VERSION ""

NS_ :

BS_:

BU_: PowertrainControlModule AtmosphericSensor SafetyRestraintSystem2 Aftertreatment_2_GasOutlet Aftertreatment_2_GasIntake DieselParticulateFilterControl Turbocharger SafetyRestraintSystem1 CabDisplay2 Aftertreatment_1_GasOutlet Aftertreatment_1_GasIntake OnBoardDataLogger OffBoardDiagnosticTool2 OffBoardDiagnosticTool1 FileServer ParkingBrakeController SeatController2 FanDriveController SteeringColumnUnit CommunicationUnitRadio CommunicationUnitSatellite CommunicationUnitCellular PropulsionBatteryCharger ChassisController2 ChassisController1 EngineValveControl AuxiliaryHeater2 AuxiliaryHeater1 ClutchUnit RampControl InformationSystem1 SuspensionSystemController2 OilSensor VehicleDynamicStability ExhaustEmissionController TransmissionDisplay2 TransmissionDisplay1 ClimateControl2 WaterPumpController RearAxleSteeringController LightingOperatorControl SeatController1 IgnitionController2 IgnitionController1 TirePressureController CabController2 CabController1 PneumaticSystemController SuspensionSystemController1 HydraulicPumpController EnduranceBrakingSystem RetarderExhaustEngine2 OnBoardDiagnosticUnit HeadwayController RetarderExhaustEngine1 CabDisplay1 ManagementComputer VirtualTerminal OffVehicleGateway PowerTakeOffFront HitchControl AuxiliaryValveControl BodyController TractorTrailerBridge1 StarterSystem ElectricalSystem VehicleSecurity VehicleNavigation AerodynamicControl ElectricalChargingSystem ClimateControl1 TripRecorder InstrumentCluster SuspensionDriveAxle2 SuspensionDriveAxle1 SuspensionSteerAxle SteeringController FuelSystem CruiseControl RetarderDriveline RetarderEngine BrakesDriveAxle2 BrakesDriveAxle1 BrakesSystemController BrakesSteerAxle AxleDrive2 AxleDrive1 AxleSteering PowerTakeOff ShiftConsoleSecondary ShiftConsolePrimary Transmission2 Transmission1 Engine2 Engine1

BO_ 2364723454 HVESP19S1: 8 Vector__XXX
 SG_ Status1CRC : 56|8@1+ (1,0) [0|255] "" Vector__XXX
 SG_ Status1Counter : 52|4@1+ (1,0) [0|15] "" Vector__XXX
 SG_ OperationalStatus : 44|4@1+ (1,0) [0|15] "" Vector__XXX
 SG_ HVBusConnectionStatus : 40|4@1+ (1,0) [0|15] "" Vector__XXX
 SG_ InternalChargerStatus : 32|2@1+ (1,0) [0|3] "" Vector__XXX
 SG_ CellBalancingActive : 30|2@1+ (1,0) [0|3] "" Vector__XXX
 SG_ CellBalanceStatus : 28|2@1+ (1,0) [0|3] "" Vector__XXX
 SG_ StOfChargeStatus : 24|4@1+ (1,0) [0|15] "" Vector__XXX
 SG_ InertiaSwStatus : 22|2@1+ (1,0) [0|3] "" Vector__XXX
 SG_ HVILStatus : 20|2@1+ (1,0) [0|3] "" Vector__XXX
 SG_ HVBusPassiveIsolTestStatus : 16|4@1+ (1,0) [0|15] "" Vector__XXX
 SG_ HVBusActiveIsolTestStatus : 12|4@1+ (1,0) [0|15] "" Vector__XXX
 SG_ CenterOfPackContactorSt : 10|2@1+ (1,0) [0|3] "" Vector__XXX
 SG_ HVBusPreChargeRelaySt : 8|2@1+ (1,0) [0|3] "" Vector__XXX
 SG_ HVBusDisconnectForewarning : 4|4@1+ (1,0) [0|15] "" Vector__XXX
 SG_ HVBusContactorSt16454 : 2|2@1+ (1,0) [0|3] "" Vector__XXX
 SG_ HVBusContactorSt : 0|2@1+ (1,0) [0|3] "" Vector__XXX

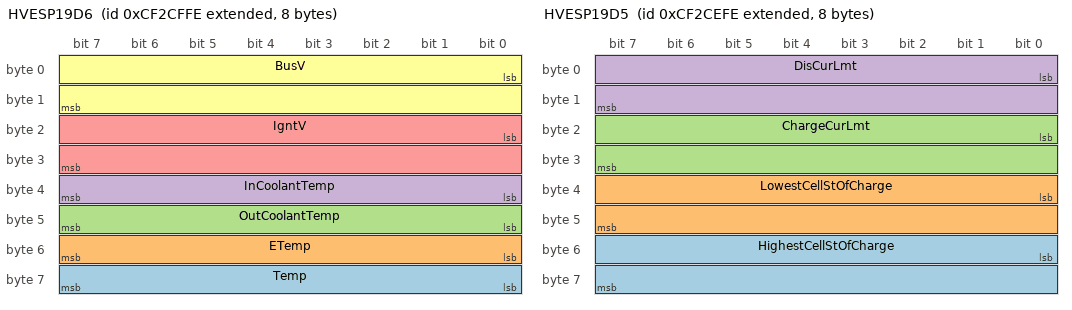
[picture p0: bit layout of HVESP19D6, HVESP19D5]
BO_ 2364723198 HVESP19D6: 8 Vector__XXX
 SG_ Temp : 56|8@1+ (1,-40) [-40|210] "°C" Vector__XXX
 SG_ ETemp : 48|8@1+ (1,-40) [-40|210] "°C" Vector__XXX
 SG_ OutCoolantTemp : 40|8@1+ (1,-40) [-40|210] "°C" Vector__XXX
 SG_ InCoolantTemp : 32|8@1+ (1,-40) [-40|210] "°C" Vector__XXX
 SG_ IgntV : 16|16@1+ (0.01,0) [0|642.55] "V" Vector__XXX
 SG_ BusV : 0|16@1+ (0.05,0) [0|3212.75] "V" Vector__XXX

BO_ 2364722942 HVESP19D5: 8 Vector__XXX
 SG_ HighestCellStOfCharge : 48|16@1+ (0.0015625,0) [0|100.3984375] "%" Vector__XXX
 SG_ LowestCellStOfCharge : 32|16@1+ (0.0015625,0) [0|100.3984375] "%" Vector__XXX
 SG_ ChargeCurLmt : 16|16@1+ (0.05,-1600) [0|1612.75] "A" Vector__XXX
 SG_ DisCurLmt : 0|16@1+ (0.05,-1600) [-1600|0] "A" Vector__XXX

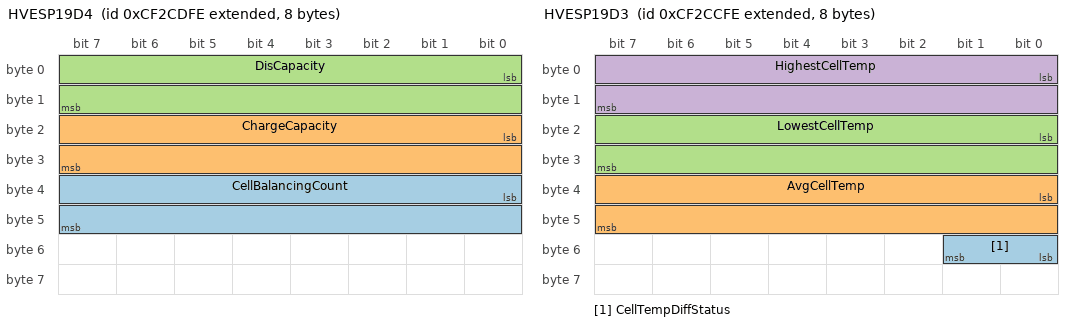
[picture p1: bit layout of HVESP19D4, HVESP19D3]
BO_ 2364722686 HVESP19D4: 8 Vector__XXX
 SG_ CellBalancingCount : 32|16@1+ (1,0) [0|64255] "" Vector__XXX
 SG_ ChargeCapacity : 16|16@1+ (0.01,0) [0|642.55] "Ah" Vector__XXX
 SG_ DisCapacity : 0|16@1+ (0.01,0) [0|642.55] "Ah" Vector__XXX

BO_ 2364722430 HVESP19D3: 8 Vector__XXX
 SG_ CellTempDiffStatus : 48|2@1+ (1,0) [0|3] "" Vector__XXX
 SG_ AvgCellTemp : 32|16@1+ (0.03125,-273) [-273|1734.96875] "°C" Vector__XXX
 SG_ LowestCellTemp : 16|16@1+ (0.03125,-273) [-273|1734.96875] "°C" Vector__XXX
 SG_ HighestCellTemp : 0|16@1+ (0.03125,-273) [-273|1734.96875] "°C" Vector__XXX

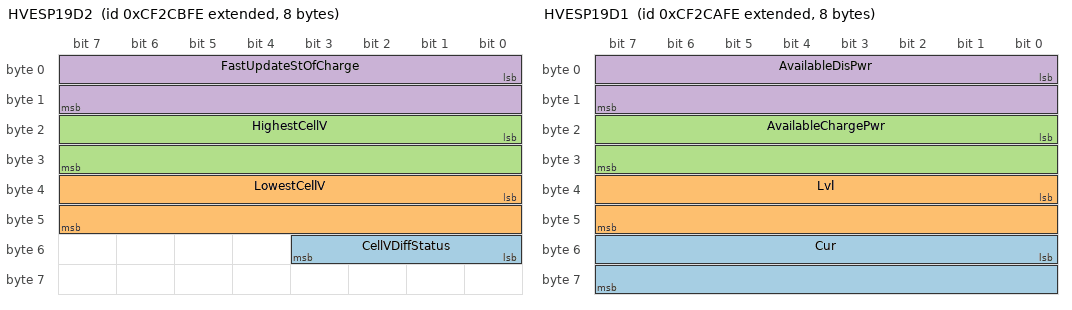
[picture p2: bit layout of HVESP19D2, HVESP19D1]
BO_ 2364722174 HVESP19D2: 8 Vector__XXX
 SG_ CellVDiffStatus : 48|4@1+ (1,0) [0|15] "" Vector__XXX
 SG_ LowestCellV : 32|16@1+ (0.001,0) [0|64.255] "V" Vector__XXX
 SG_ HighestCellV : 16|16@1+ (0.001,0) [0|64.255] "V" Vector__XXX
 SG_ FastUpdateStOfCharge : 0|16@1+ (0.0015625,0) [0|100.3984375] "%" Vector__XXX

BO_ 2364721918 HVESP19D1: 8 Vector__XXX
 SG_ Cur : 48|16@1+ (0.05,-1600) [-1600|1612.75] "A" Vector__XXX
 SG_ Lvl : 32|16@1+ (0.05,0) [0|3212.75] "V" Vector__XXX
 SG_ AvailableChargePwr : 16|16@1+ (0.05,0) [0|3212.75] "kW" Vector__XXX
 SG_ AvailableDisPwr : 0|16@1+ (0.05,0) [0|3212.75] "kW" Vector__XXX

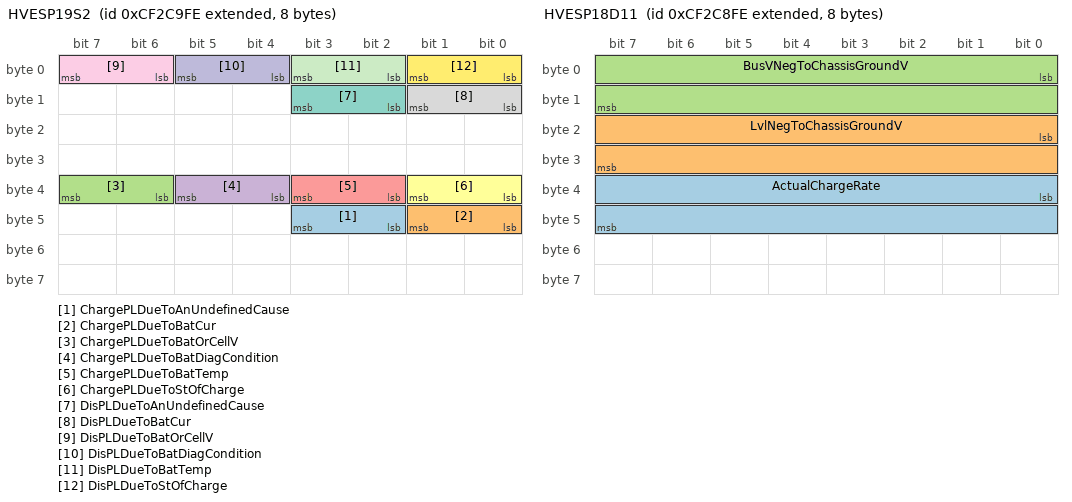
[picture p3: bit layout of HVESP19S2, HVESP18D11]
BO_ 2364721662 HVESP19S2: 8 Vector__XXX
 SG_ ChargePLDueToAnUndefinedCause : 42|2@1+ (1,0) [0|3] "" Vector__XXX
 SG_ ChargePLDueToBatCur : 40|2@1+ (1,0) [0|3] "" Vector__XXX
 SG_ ChargePLDueToBatOrCellV : 38|2@1+ (1,0) [0|3] "" Vector__XXX
 SG_ ChargePLDueToBatDiagCondition : 36|2@1+ (1,0) [0|3] "" Vector__XXX
 SG_ ChargePLDueToBatTemp : 34|2@1+ (1,0) [0|3] "" Vector__XXX
 SG_ ChargePLDueToStOfCharge : 32|2@1+ (1,0) [0|3] "" Vector__XXX
 SG_ DisPLDueToAnUndefinedCause : 10|2@1+ (1,0) [0|3] "" Vector__XXX
 SG_ DisPLDueToBatCur : 8|2@1+ (1,0) [0|3] "" Vector__XXX
 SG_ DisPLDueToBatOrCellV : 6|2@1+ (1,0) [0|3] "" Vector__XXX
 SG_ DisPLDueToBatDiagCondition : 4|2@1+ (1,0) [0|3] "" Vector__XXX
 SG_ DisPLDueToBatTemp : 2|2@1+ (1,0) [0|3] "" Vector__XXX
 SG_ DisPLDueToStOfCharge : 0|2@1+ (1,0) [0|3] "" Vector__XXX

BO_ 2364721406 HVESP18D11: 8 Vector__XXX
 SG_ ActualChargeRate : 32|16@1+ (0.05,0) [0|3212.75] "kW" Vector__XXX
 SG_ LvlNegToChassisGroundV : 16|16@1+ (0.05,0) [0|3212.75] "V" Vector__XXX
 SG_ BusVNegToChassisGroundV : 0|16@1+ (0.05,0) [0|3212.75] "V" Vector__XXX

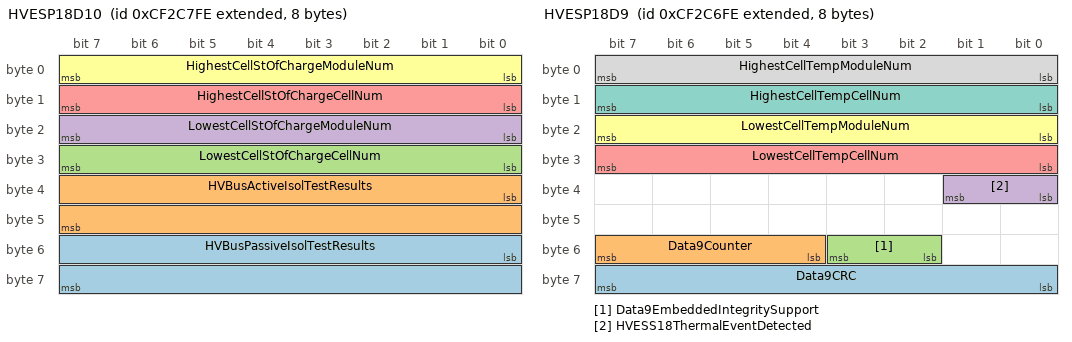
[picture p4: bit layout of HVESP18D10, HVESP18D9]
BO_ 2364721150 HVESP18D10: 8 Vector__XXX
 SG_ HVBusPassiveIsolTestResults : 48|16@1+ (0.1,0) [0|6425.5] "Ohm/V" Vector__XXX
 SG_ HVBusActiveIsolTestResults : 32|16@1+ (0.1,0) [0|6425.5] "Ohm/V" Vector__XXX
 SG_ LowestCellStOfChargeCellNum : 24|8@1+ (1,0) [0|250] "" Vector__XXX
 SG_ LowestCellStOfChargeModuleNum : 16|8@1+ (1,0) [0|250] "" Vector__XXX
 SG_ HighestCellStOfChargeCellNum : 8|8@1+ (1,0) [0|250] "" Vector__XXX
 SG_ HighestCellStOfChargeModuleNum : 0|8@1+ (1,0) [0|250] "" Vector__XXX

BO_ 2364720894 HVESP18D9: 8 Vector__XXX
 SG_ Data9CRC : 56|8@1+ (1,0) [0|255] "" Vector__XXX
 SG_ Data9Counter : 52|4@1+ (1,0) [0|15] "" Vector__XXX
 SG_ Data9EmbeddedIntegritySupport : 50|2@1+ (1,0) [0|3] "" Vector__XXX
 SG_ HVESS18ThermalEventDetected : 32|2@1+ (1,0) [0|3] "" Vector__XXX
 SG_ LowestCellTempCellNum : 24|8@1+ (1,0) [0|250] "" Vector__XXX
 SG_ LowestCellTempModuleNum : 16|8@1+ (1,0) [0|250] "" Vector__XXX
 SG_ HighestCellTempCellNum : 8|8@1+ (1,0) [0|250] "" Vector__XXX
 SG_ HighestCellTempModuleNum : 0|8@1+ (1,0) [0|250] "" Vector__XXX

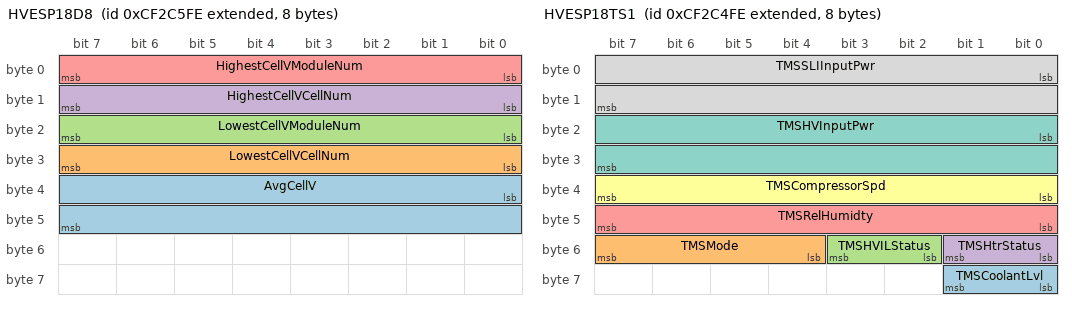
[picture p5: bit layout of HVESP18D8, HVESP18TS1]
BO_ 2364720638 HVESP18D8: 8 Vector__XXX
 SG_ AvgCellV : 32|16@1+ (0.001,0) [0|64.255] "V" Vector__XXX
 SG_ LowestCellVCellNum : 24|8@1+ (1,0) [0|250] "" Vector__XXX
 SG_ LowestCellVModuleNum : 16|8@1+ (1,0) [0|250] "" Vector__XXX
 SG_ HighestCellVCellNum : 8|8@1+ (1,0) [0|250] "" Vector__XXX
 SG_ HighestCellVModuleNum : 0|8@1+ (1,0) [0|250] "" Vector__XXX

BO_ 2364720382 HVESP18TS1: 8 Vector__XXX
 SG_ TMSCoolantLvl : 56|2@1+ (1,0) [0|3] "" Vector__XXX
 SG_ TMSMode : 52|4@1+ (1,0) [0|15] "" Vector__XXX
 SG_ TMSHVILStatus : 50|2@1+ (1,0) [0|3] "" Vector__XXX
 SG_ TMSHtrStatus : 48|2@1+ (1,0) [0|3] "" Vector__XXX
 SG_ TMSRelHumidty : 40|8@1+ (0.4,0) [0|100] "%" Vector__XXX
 SG_ TMSCompressorSpd : 32|8@1+ (32,0) [0|8000] "rpm" Vector__XXX
 SG_ TMSHVInputPwr : 16|16@1+ (0.5,0) [0|32127.5] "W" Vector__XXX
 SG_ TMSSLIInputPwr : 0|16@1+ (0.5,0) [0|32127.5] "W" Vector__XXX

BO_ 2364720126 HVESP18MS1: 8 Vector__XXX
 SG_ Module32OperationalStatus : 62|2@1+ (1,0) [0|3] "" Vector__XXX
 SG_ Module31OperationalStatus : 60|2@1+ (1,0) [0|3] "" Vector__XXX
 SG_ Module30OperationalStatus : 58|2@1+ (1,0) [0|3] "" Vector__XXX
 SG_ Module29OperationalStatus : 56|2@1+ (1,0) [0|3] "" Vector__XXX
 SG_ Module28OperationalStatus : 54|2@1+ (1,0) [0|3] "" Vector__XXX
 SG_ Module27OperationalStatus : 52|2@1+ (1,0) [0|3] "" Vector__XXX
 SG_ Module26OperationalStatus : 50|2@1+ (1,0) [0|3] "" Vector__XXX
 SG_ Module25OperationalStatus : 48|2@1+ (1,0) [0|3] "" Vector__XXX
 SG_ Module24OperationalStatus : 46|2@1+ (1,0) [0|3] "" Vector__XXX
 SG_ Module23OperationalStatus : 44|2@1+ (1,0) [0|3] "" Vector__XXX
 SG_ Module22OperationalStatus : 42|2@1+ (1,0) [0|3] "" Vector__XXX
 SG_ Module21OperationalStatus : 40|2@1+ (1,0) [0|3] "" Vector__XXX
 SG_ Module20OperationalStatus : 38|2@1+ (1,0) [0|3] "" Vector__XXX
 SG_ Module19OperationalStatus : 36|2@1+ (1,0) [0|3] "" Vector__XXX
 SG_ Module18OperationalStatus : 34|2@1+ (1,0) [0|3] "" Vector__XXX
 SG_ Module17OperationalStatus : 32|2@1+ (1,0) [0|3] "" Vector__XXX
 SG_ Module16OperationalStatus : 30|2@1+ (1,0) [0|3] "" Vector__XXX
 SG_ Module15OperationalStatus : 28|2@1+ (1,0) [0|3] "" Vector__XXX
 SG_ Module14OperationalStatus : 26|2@1+ (1,0) [0|3] "" Vector__XXX
 SG_ Module13OperationalStatus : 24|2@1+ (1,0) [0|3] "" Vector__XXX
 SG_ Module12OperationalStatus : 22|2@1+ (1,0) [0|3] "" Vector__XXX
 SG_ Module11OperationalStatus : 20|2@1+ (1,0) [0|3] "" Vector__XXX
 SG_ Module10OperationalStatus : 18|2@1+ (1,0) [0|3] "" Vector__XXX
 SG_ Module9OperationalStatus : 16|2@1+ (1,0) [0|3] "" Vector__XXX
 SG_ Module8OperationalStatus : 14|2@1+ (1,0) [0|3] "" Vector__XXX
 SG_ Module7OperationalStatus : 12|2@1+ (1,0) [0|3] "" Vector__XXX
 SG_ Module6OperationalStatus : 10|2@1+ (1,0) [0|3] "" Vector__XXX
 SG_ Module5OperationalStatus : 8|2@1+ (1,0) [0|3] "" Vector__XXX
 SG_ Module4OperationalStatus : 6|2@1+ (1,0) [0|3] "" Vector__XXX
 SG_ Module3OperationalStatus : 4|2@1+ (1,0) [0|3] "" Vector__XXX
 SG_ Module2OperationalStatus : 2|2@1+ (1,0) [0|3] "" Vector__XXX
 SG_ Module1OperationalStatus : 0|2@1+ (1,0) [0|3] "" Vector__XXX

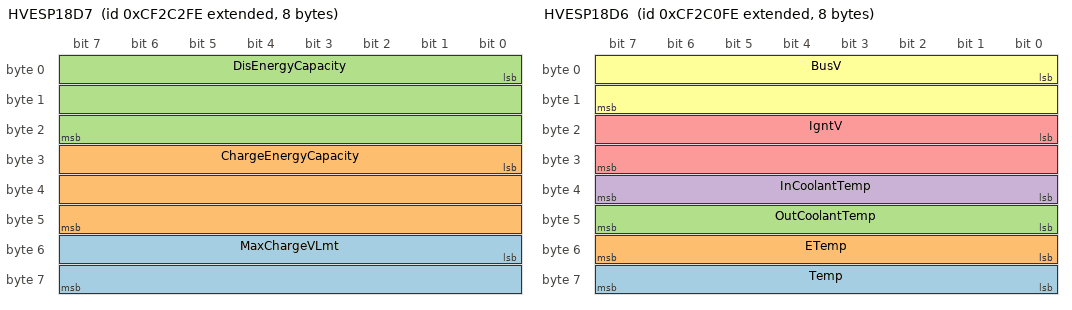
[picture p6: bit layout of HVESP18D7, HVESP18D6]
BO_ 2364719870 HVESP18D7: 8 Vector__XXX
 SG_ MaxChargeVLmt : 48|16@1+ (0.05,0) [0|3212.75] "V" Vector__XXX
 SG_ ChargeEnergyCapacity : 24|24@1+ (0.001,0) [0|16449.535] "kWh" Vector__XXX
 SG_ DisEnergyCapacity : 0|24@1+ (0.001,0) [0|16449.535] "kWh" Vector__XXX

BO_ 2364719614 HVESP18S1: 8 Vector__XXX
 SG_ Status1CRC : 56|8@1+ (1,0) [0|255] "" Vector__XXX
 SG_ Status1Counter : 52|4@1+ (1,0) [0|15] "" Vector__XXX
 SG_ OperationalStatus : 44|4@1+ (1,0) [0|15] "" Vector__XXX
 SG_ HVBusConnectionStatus : 40|4@1+ (1,0) [0|15] "" Vector__XXX
 SG_ InternalChargerStatus : 32|2@1+ (1,0) [0|3] "" Vector__XXX
 SG_ CellBalancingActive : 30|2@1+ (1,0) [0|3] "" Vector__XXX
 SG_ CellBalanceStatus : 28|2@1+ (1,0) [0|3] "" Vector__XXX
 SG_ StOfChargeStatus : 24|4@1+ (1,0) [0|15] "" Vector__XXX
 SG_ InertiaSwStatus : 22|2@1+ (1,0) [0|3] "" Vector__XXX
 SG_ HVILStatus : 20|2@1+ (1,0) [0|3] "" Vector__XXX
 SG_ HVBusPassiveIsolTestStatus : 16|4@1+ (1,0) [0|15] "" Vector__XXX
 SG_ HVBusActiveIsolTestStatus : 12|4@1+ (1,0) [0|15] "" Vector__XXX
 SG_ CenterOfPackContactorSt : 10|2@1+ (1,0) [0|3] "" Vector__XXX
 SG_ HVBusPreChargeRelaySt : 8|2@1+ (1,0) [0|3] "" Vector__XXX
 SG_ HVBusDisconnectForewarning : 4|4@1+ (1,0) [0|15] "" Vector__XXX
 SG_ HVBusContactorSt16312 : 2|2@1+ (1,0) [0|3] "" Vector__XXX
 SG_ HVBusContactorSt : 0|2@1+ (1,0) [0|3] "" Vector__XXX

BO_ 2364719358 HVESP18D6: 8 Vector__XXX
 SG_ Temp : 56|8@1+ (1,-40) [-40|210] "°C" Vector__XXX
 SG_ ETemp : 48|8@1+ (1,-40) [-40|210] "°C" Vector__XXX
 SG_ OutCoolantTemp : 40|8@1+ (1,-40) [-40|210] "°C" Vector__XXX
 SG_ InCoolantTemp : 32|8@1+ (1,-40) [-40|210] "°C" Vector__XXX
 SG_ IgntV : 16|16@1+ (0.01,0) [0|642.55] "V" Vector__XXX
 SG_ BusV : 0|16@1+ (0.05,0) [0|3212.75] "V" Vector__XXX

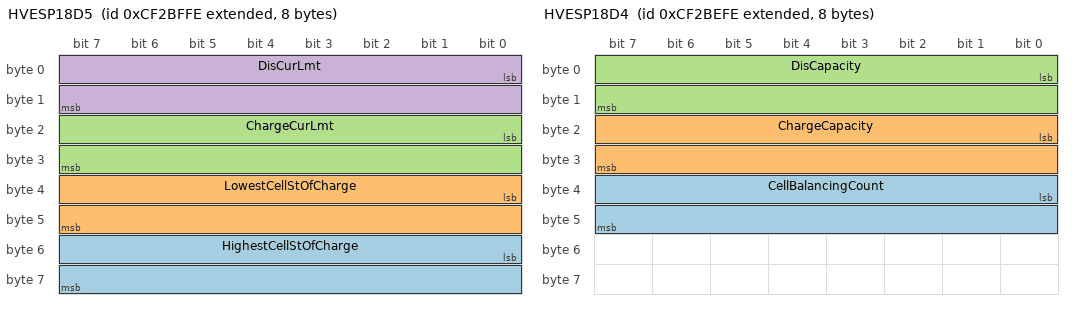
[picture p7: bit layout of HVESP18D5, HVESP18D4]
BO_ 2364719102 HVESP18D5: 8 Vector__XXX
 SG_ HighestCellStOfCharge : 48|16@1+ (0.0015625,0) [0|100.3984375] "%" Vector__XXX
 SG_ LowestCellStOfCharge : 32|16@1+ (0.0015625,0) [0|100.3984375] "%" Vector__XXX
 SG_ ChargeCurLmt : 16|16@1+ (0.05,-1600) [0|1612.75] "A" Vector__XXX
 SG_ DisCurLmt : 0|16@1+ (0.05,-1600) [-1600|0] "A" Vector__XXX

BO_ 2364718846 HVESP18D4: 8 Vector__XXX
 SG_ CellBalancingCount : 32|16@1+ (1,0) [0|64255] "" Vector__XXX
 SG_ ChargeCapacity : 16|16@1+ (0.01,0) [0|642.55] "Ah" Vector__XXX
 SG_ DisCapacity : 0|16@1+ (0.01,0) [0|642.55] "Ah" Vector__XXX

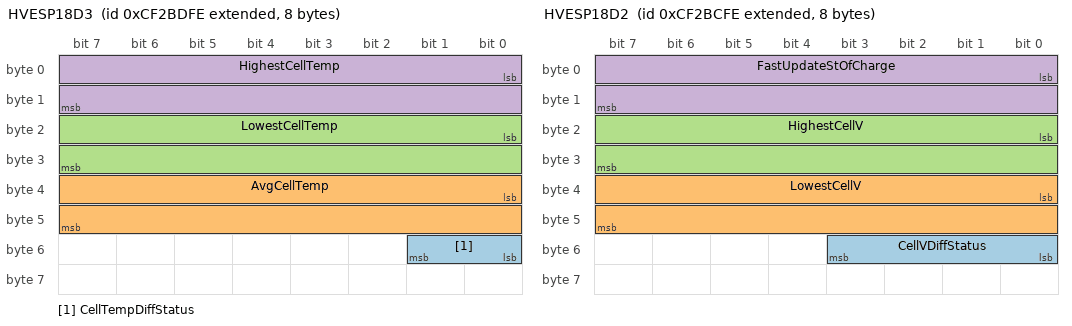
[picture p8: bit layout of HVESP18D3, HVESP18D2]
BO_ 2364718590 HVESP18D3: 8 Vector__XXX
 SG_ CellTempDiffStatus : 48|2@1+ (1,0) [0|3] "" Vector__XXX
 SG_ AvgCellTemp : 32|16@1+ (0.03125,-273) [-273|1734.96875] "°C" Vector__XXX
 SG_ LowestCellTemp : 16|16@1+ (0.03125,-273) [-273|1734.96875] "°C" Vector__XXX
 SG_ HighestCellTemp : 0|16@1+ (0.03125,-273) [-273|1734.96875] "°C" Vector__XXX

BO_ 2364718334 HVESP18D2: 8 Vector__XXX
 SG_ CellVDiffStatus : 48|4@1+ (1,0) [0|15] "" Vector__XXX
 SG_ LowestCellV : 32|16@1+ (0.001,0) [0|64.255] "V" Vector__XXX
 SG_ HighestCellV : 16|16@1+ (0.001,0) [0|64.255] "V" Vector__XXX
 SG_ FastUpdateStOfCharge : 0|16@1+ (0.0015625,0) [0|100.3984375] "%" Vector__XXX

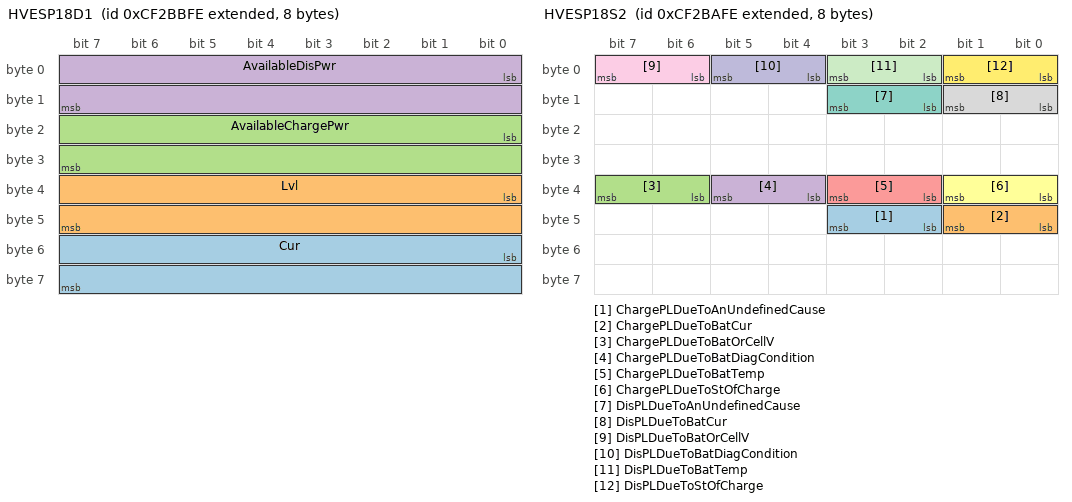
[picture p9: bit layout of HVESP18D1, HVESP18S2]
BO_ 2364718078 HVESP18D1: 8 Vector__XXX
 SG_ Cur : 48|16@1+ (0.05,-1600) [-1600|1612.75] "A" Vector__XXX
 SG_ Lvl : 32|16@1+ (0.05,0) [0|3212.75] "V" Vector__XXX
 SG_ AvailableChargePwr : 16|16@1+ (0.05,0) [0|3212.75] "kW" Vector__XXX
 SG_ AvailableDisPwr : 0|16@1+ (0.05,0) [0|3212.75] "kW" Vector__XXX

BO_ 2364717822 HVESP18S2: 8 Vector__XXX
 SG_ ChargePLDueToAnUndefinedCause : 42|2@1+ (1,0) [0|3] "" Vector__XXX
 SG_ ChargePLDueToBatCur : 40|2@1+ (1,0) [0|3] "" Vector__XXX
 SG_ ChargePLDueToBatOrCellV : 38|2@1+ (1,0) [0|3] "" Vector__XXX
 SG_ ChargePLDueToBatDiagCondition : 36|2@1+ (1,0) [0|3] "" Vector__XXX
 SG_ ChargePLDueToBatTemp : 34|2@1+ (1,0) [0|3] "" Vector__XXX
 SG_ ChargePLDueToStOfCharge : 32|2@1+ (1,0) [0|3] "" Vector__XXX
 SG_ DisPLDueToAnUndefinedCause : 10|2@1+ (1,0) [0|3] "" Vector__XXX
 SG_ DisPLDueToBatCur : 8|2@1+ (1,0) [0|3] "" Vector__XXX
 SG_ DisPLDueToBatOrCellV : 6|2@1+ (1,0) [0|3] "" Vector__XXX
 SG_ DisPLDueToBatDiagCondition : 4|2@1+ (1,0) [0|3] "" Vector__XXX
 SG_ DisPLDueToBatTemp : 2|2@1+ (1,0) [0|3] "" Vector__XXX
 SG_ DisPLDueToStOfCharge : 0|2@1+ (1,0) [0|3] "" Vector__XXX

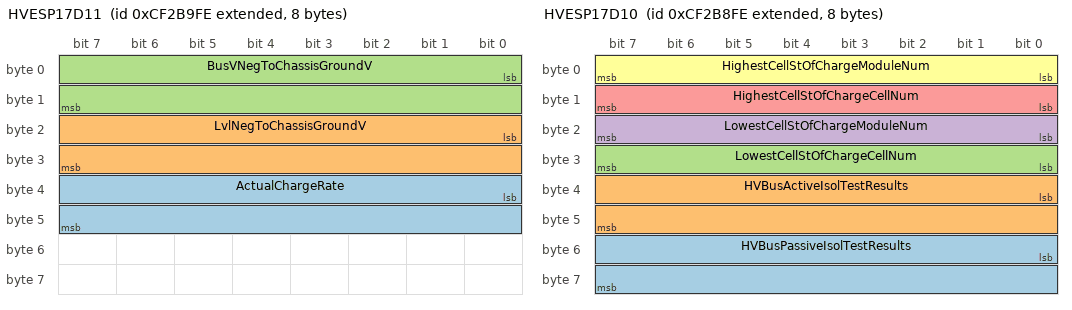
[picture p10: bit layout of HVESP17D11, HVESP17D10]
BO_ 2364717566 HVESP17D11: 8 Vector__XXX
 SG_ ActualChargeRate : 32|16@1+ (0.05,0) [0|3212.75] "kW" Vector__XXX
 SG_ LvlNegToChassisGroundV : 16|16@1+ (0.05,0) [0|3212.75] "V" Vector__XXX
 SG_ BusVNegToChassisGroundV : 0|16@1+ (0.05,0) [0|3212.75] "V" Vector__XXX

BO_ 2364717310 HVESP17D10: 8 Vector__XXX
 SG_ HVBusPassiveIsolTestResults : 48|16@1+ (0.1,0) [0|6425.5] "Ohm/V" Vector__XXX
 SG_ HVBusActiveIsolTestResults : 32|16@1+ (0.1,0) [0|6425.5] "Ohm/V" Vector__XXX
 SG_ LowestCellStOfChargeCellNum : 24|8@1+ (1,0) [0|250] "" Vector__XXX
 SG_ LowestCellStOfChargeModuleNum : 16|8@1+ (1,0) [0|250] "" Vector__XXX
 SG_ HighestCellStOfChargeCellNum : 8|8@1+ (1,0) [0|250] "" Vector__XXX
 SG_ HighestCellStOfChargeModuleNum : 0|8@1+ (1,0) [0|250] "" Vector__XXX

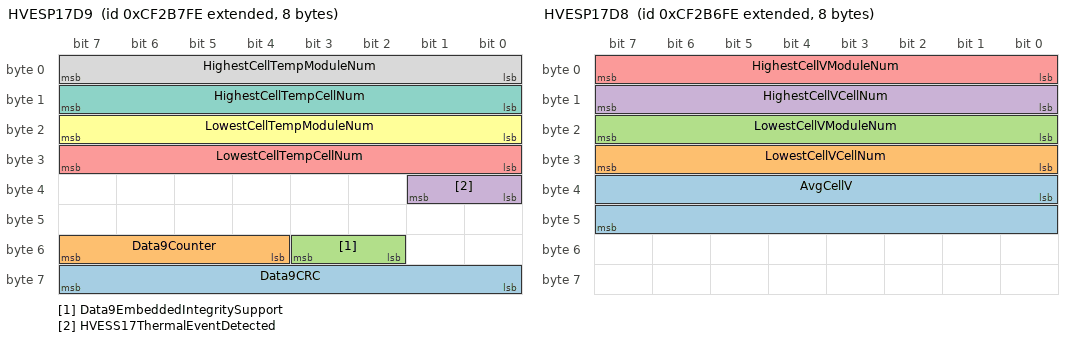
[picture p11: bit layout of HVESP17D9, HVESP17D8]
BO_ 2364717054 HVESP17D9: 8 Vector__XXX
 SG_ Data9CRC : 56|8@1+ (1,0) [0|255] "" Vector__XXX
 SG_ Data9Counter : 52|4@1+ (1,0) [0|15] "" Vector__XXX
 SG_ Data9EmbeddedIntegritySupport : 50|2@1+ (1,0) [0|3] "" Vector__XXX
 SG_ HVESS17ThermalEventDetected : 32|2@1+ (1,0) [0|3] "" Vector__XXX
 SG_ LowestCellTempCellNum : 24|8@1+ (1,0) [0|250] "" Vector__XXX
 SG_ LowestCellTempModuleNum : 16|8@1+ (1,0) [0|250] "" Vector__XXX
 SG_ HighestCellTempCellNum : 8|8@1+ (1,0) [0|250] "" Vector__XXX
 SG_ HighestCellTempModuleNum : 0|8@1+ (1,0) [0|250] "" Vector__XXX

BO_ 2364716798 HVESP17D8: 8 Vector__XXX
 SG_ AvgCellV : 32|16@1+ (0.001,0) [0|64.255] "V" Vector__XXX
 SG_ LowestCellVCellNum : 24|8@1+ (1,0) [0|250] "" Vector__XXX
 SG_ LowestCellVModuleNum : 16|8@1+ (1,0) [0|250] "" Vector__XXX
 SG_ HighestCellVCellNum : 8|8@1+ (1,0) [0|250] "" Vector__XXX
 SG_ HighestCellVModuleNum : 0|8@1+ (1,0) [0|250] "" Vector__XXX

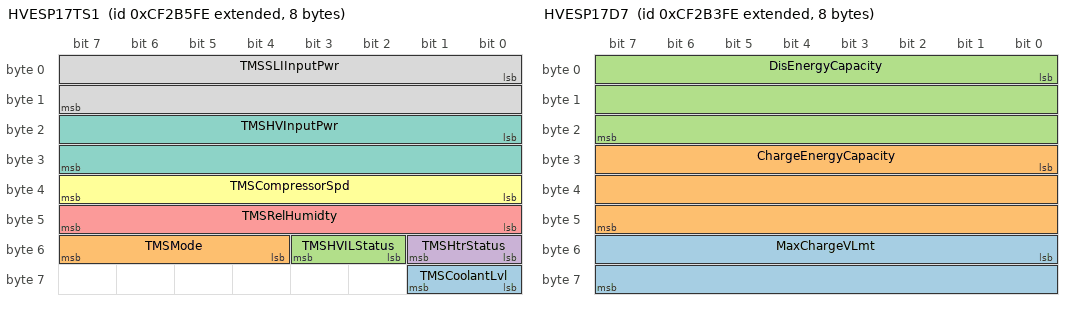
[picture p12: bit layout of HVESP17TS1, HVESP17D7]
BO_ 2364716542 HVESP17TS1: 8 Vector__XXX
 SG_ TMSCoolantLvl : 56|2@1+ (1,0) [0|3] "" Vector__XXX
 SG_ TMSMode : 52|4@1+ (1,0) [0|15] "" Vector__XXX
 SG_ TMSHVILStatus : 50|2@1+ (1,0) [0|3] "" Vector__XXX
 SG_ TMSHtrStatus : 48|2@1+ (1,0) [0|3] "" Vector__XXX
 SG_ TMSRelHumidty : 40|8@1+ (0.4,0) [0|100] "%" Vector__XXX
 SG_ TMSCompressorSpd : 32|8@1+ (32,0) [0|8000] "rpm" Vector__XXX
 SG_ TMSHVInputPwr : 16|16@1+ (0.5,0) [0|32127.5] "W" Vector__XXX
 SG_ TMSSLIInputPwr : 0|16@1+ (0.5,0) [0|32127.5] "W" Vector__XXX

BO_ 2364716286 HVESP17MS1: 8 Vector__XXX
 SG_ Module32OperationalStatus : 62|2@1+ (1,0) [0|3] "" Vector__XXX
 SG_ Module31OperationalStatus : 60|2@1+ (1,0) [0|3] "" Vector__XXX
 SG_ Module30OperationalStatus : 58|2@1+ (1,0) [0|3] "" Vector__XXX
 SG_ Module29OperationalStatus : 56|2@1+ (1,0) [0|3] "" Vector__XXX
 SG_ Module28OperationalStatus : 54|2@1+ (1,0) [0|3] "" Vector__XXX
 SG_ Module27OperationalStatus : 52|2@1+ (1,0) [0|3] "" Vector__XXX
 SG_ Module26OperationalStatus : 50|2@1+ (1,0) [0|3] "" Vector__XXX
 SG_ Module25OperationalStatus : 48|2@1+ (1,0) [0|3] "" Vector__XXX
 SG_ Module24OperationalStatus : 46|2@1+ (1,0) [0|3] "" Vector__XXX
 SG_ Module23OperationalStatus : 44|2@1+ (1,0) [0|3] "" Vector__XXX
 SG_ Module22OperationalStatus : 42|2@1+ (1,0) [0|3] "" Vector__XXX
 SG_ Module21OperationalStatus : 40|2@1+ (1,0) [0|3] "" Vector__XXX
 SG_ Module20OperationalStatus : 38|2@1+ (1,0) [0|3] "" Vector__XXX
 SG_ Module19OperationalStatus : 36|2@1+ (1,0) [0|3] "" Vector__XXX
 SG_ Module18OperationalStatus : 34|2@1+ (1,0) [0|3] "" Vector__XXX
 SG_ Module17OperationalStatus : 32|2@1+ (1,0) [0|3] "" Vector__XXX
 SG_ Module16OperationalStatus : 30|2@1+ (1,0) [0|3] "" Vector__XXX
 SG_ Module15OperationalStatus : 28|2@1+ (1,0) [0|3] "" Vector__XXX
 SG_ Module14OperationalStatus : 26|2@1+ (1,0) [0|3] "" Vector__XXX
 SG_ Module13OperationalStatus : 24|2@1+ (1,0) [0|3] "" Vector__XXX
 SG_ Module12OperationalStatus : 22|2@1+ (1,0) [0|3] "" Vector__XXX
 SG_ Module11OperationalStatus : 20|2@1+ (1,0) [0|3] "" Vector__XXX
 SG_ Module10OperationalStatus : 18|2@1+ (1,0) [0|3] "" Vector__XXX
 SG_ Module9OperationalStatus : 16|2@1+ (1,0) [0|3] "" Vector__XXX
 SG_ Module8OperationalStatus : 14|2@1+ (1,0) [0|3] "" Vector__XXX
 SG_ Module7OperationalStatus : 12|2@1+ (1,0) [0|3] "" Vector__XXX
 SG_ Module6OperationalStatus : 10|2@1+ (1,0) [0|3] "" Vector__XXX
 SG_ Module5OperationalStatus : 8|2@1+ (1,0) [0|3] "" Vector__XXX
 SG_ Module4OperationalStatus : 6|2@1+ (1,0) [0|3] "" Vector__XXX
 SG_ Module3OperationalStatus : 4|2@1+ (1,0) [0|3] "" Vector__XXX
 SG_ Module2OperationalStatus : 2|2@1+ (1,0) [0|3] "" Vector__XXX
 SG_ Module1OperationalStatus : 0|2@1+ (1,0) [0|3] "" Vector__XXX

BO_ 2364716030 HVESP17D7: 8 Vector__XXX
 SG_ MaxChargeVLmt : 48|16@1+ (0.05,0) [0|3212.75] "V" Vector__XXX
 SG_ ChargeEnergyCapacity : 24|24@1+ (0.001,0) [0|16449.535] "kWh" Vector__XXX
 SG_ DisEnergyCapacity : 0|24@1+ (0.001,0) [0|16449.535] "kWh" Vector__XXX

BO_ 2364715774 HVESP17S1: 8 Vector__XXX
 SG_ Status1CRC : 56|8@1+ (1,0) [0|255] "" Vector__XXX
 SG_ Status1Counter : 52|4@1+ (1,0) [0|15] "" Vector__XXX
 SG_ OperationalStatus : 44|4@1+ (1,0) [0|15] "" Vector__XXX
 SG_ HVBusConnectionStatus : 40|4@1+ (1,0) [0|15] "" Vector__XXX
 SG_ InternalChargerStatus : 32|2@1+ (1,0) [0|3] "" Vector__XXX
 SG_ CellBalancingActive : 30|2@1+ (1,0) [0|3] "" Vector__XXX
 SG_ CellBalanceStatus : 28|2@1+ (1,0) [0|3] "" Vector__XXX
 SG_ StOfChargeStatus : 24|4@1+ (1,0) [0|15] "" Vector__XXX
 SG_ InertiaSwStatus : 22|2@1+ (1,0) [0|3] "" Vector__XXX
 SG_ HVILStatus : 20|2@1+ (1,0) [0|3] "" Vector__XXX
 SG_ HVBusPassiveIsolTestStatus : 16|4@1+ (1,0) [0|15] "" Vector__XXX
 SG_ HVBusActiveIsolTestStatus : 12|4@1+ (1,0) [0|15] "" Vector__XXX
 SG_ CenterOfPackContactorSt : 10|2@1+ (1,0) [0|3] "" Vector__XXX
 SG_ HVBusPreChargeRelaySt : 8|2@1+ (1,0) [0|3] "" Vector__XXX
 SG_ HVBusDisconnectForewarning : 4|4@1+ (1,0) [0|15] "" Vector__XXX
 SG_ HVBusContactorSt16170 : 2|2@1+ (1,0) [0|3] "" Vector__XXX
 SG_ HVBusContactorSt : 0|2@1+ (1,0) [0|3] "" Vector__XXX

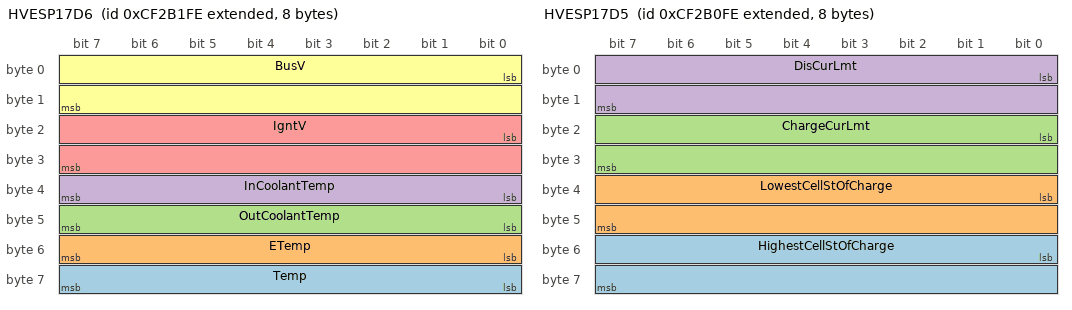
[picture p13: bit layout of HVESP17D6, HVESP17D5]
BO_ 2364715518 HVESP17D6: 8 Vector__XXX
 SG_ Temp : 56|8@1+ (1,-40) [-40|210] "°C" Vector__XXX
 SG_ ETemp : 48|8@1+ (1,-40) [-40|210] "°C" Vector__XXX
 SG_ OutCoolantTemp : 40|8@1+ (1,-40) [-40|210] "°C" Vector__XXX
 SG_ InCoolantTemp : 32|8@1+ (1,-40) [-40|210] "°C" Vector__XXX
 SG_ IgntV : 16|16@1+ (0.01,0) [0|642.55] "V" Vector__XXX
 SG_ BusV : 0|16@1+ (0.05,0) [0|3212.75] "V" Vector__XXX

BO_ 2364715262 HVESP17D5: 8 Vector__XXX
 SG_ HighestCellStOfCharge : 48|16@1+ (0.0015625,0) [0|100.3984375] "%" Vector__XXX
 SG_ LowestCellStOfCharge : 32|16@1+ (0.0015625,0) [0|100.3984375] "%" Vector__XXX
 SG_ ChargeCurLmt : 16|16@1+ (0.05,-1600) [0|1612.75] "A" Vector__XXX
 SG_ DisCurLmt : 0|16@1+ (0.05,-1600) [-1600|0] "A" Vector__XXX

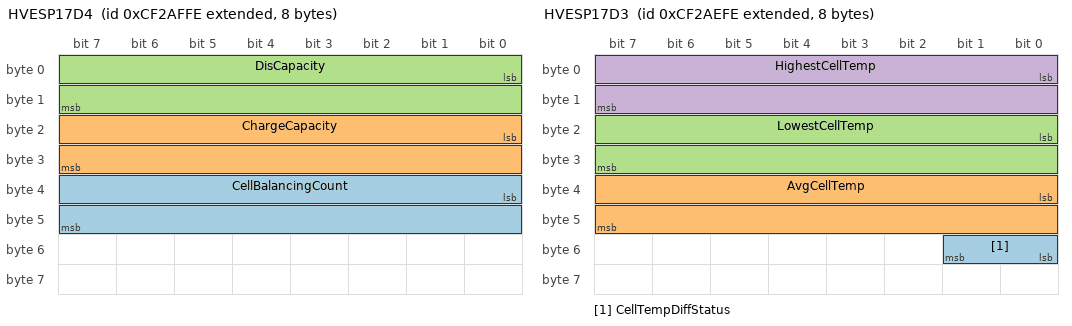
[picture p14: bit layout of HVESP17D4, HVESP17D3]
BO_ 2364715006 HVESP17D4: 8 Vector__XXX
 SG_ CellBalancingCount : 32|16@1+ (1,0) [0|64255] "" Vector__XXX
 SG_ ChargeCapacity : 16|16@1+ (0.01,0) [0|642.55] "Ah" Vector__XXX
 SG_ DisCapacity : 0|16@1+ (0.01,0) [0|642.55] "Ah" Vector__XXX

BO_ 2364714750 HVESP17D3: 8 Vector__XXX
 SG_ CellTempDiffStatus : 48|2@1+ (1,0) [0|3] "" Vector__XXX
 SG_ AvgCellTemp : 32|16@1+ (0.03125,-273) [-273|1734.96875] "°C" Vector__XXX
 SG_ LowestCellTemp : 16|16@1+ (0.03125,-273) [-273|1734.96875] "°C" Vector__XXX
 SG_ HighestCellTemp : 0|16@1+ (0.03125,-273) [-273|1734.96875] "°C" Vector__XXX

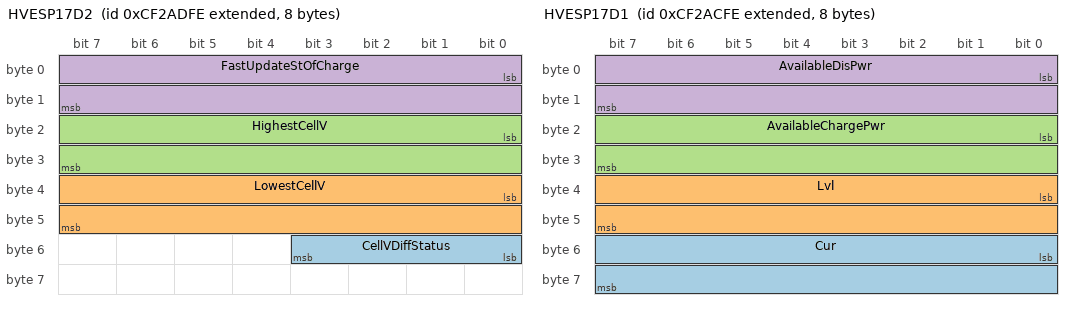
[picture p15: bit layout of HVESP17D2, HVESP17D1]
BO_ 2364714494 HVESP17D2: 8 Vector__XXX
 SG_ CellVDiffStatus : 48|4@1+ (1,0) [0|15] "" Vector__XXX
 SG_ LowestCellV : 32|16@1+ (0.001,0) [0|64.255] "V" Vector__XXX
 SG_ HighestCellV : 16|16@1+ (0.001,0) [0|64.255] "V" Vector__XXX
 SG_ FastUpdateStOfCharge : 0|16@1+ (0.0015625,0) [0|100.3984375] "%" Vector__XXX

BO_ 2364714238 HVESP17D1: 8 Vector__XXX
 SG_ Cur : 48|16@1+ (0.05,-1600) [-1600|1612.75] "A" Vector__XXX
 SG_ Lvl : 32|16@1+ (0.05,0) [0|3212.75] "V" Vector__XXX
 SG_ AvailableChargePwr : 16|16@1+ (0.05,0) [0|3212.75] "kW" Vector__XXX
 SG_ AvailableDisPwr : 0|16@1+ (0.05,0) [0|3212.75] "kW" Vector__XXX

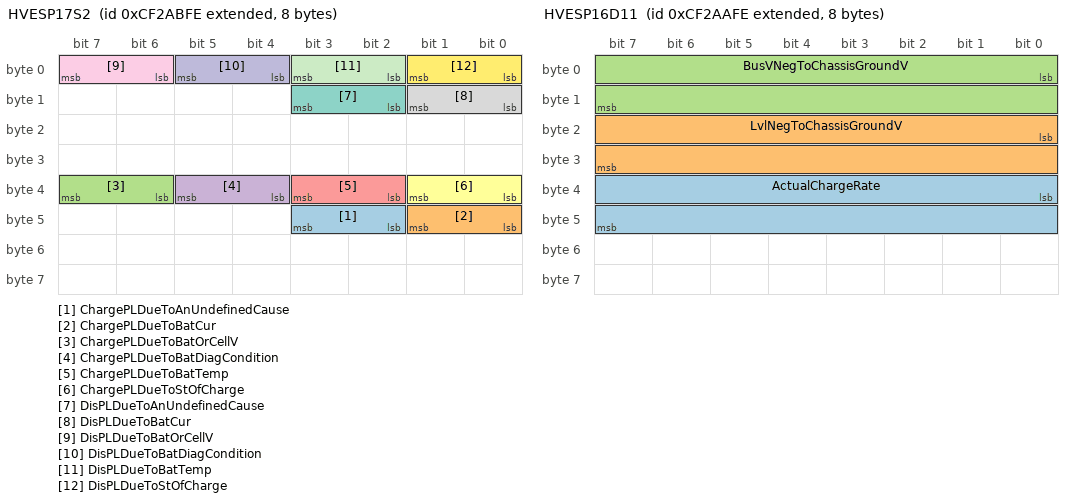
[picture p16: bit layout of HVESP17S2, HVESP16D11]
BO_ 2364713982 HVESP17S2: 8 Vector__XXX
 SG_ ChargePLDueToAnUndefinedCause : 42|2@1+ (1,0) [0|3] "" Vector__XXX
 SG_ ChargePLDueToBatCur : 40|2@1+ (1,0) [0|3] "" Vector__XXX
 SG_ ChargePLDueToBatOrCellV : 38|2@1+ (1,0) [0|3] "" Vector__XXX
 SG_ ChargePLDueToBatDiagCondition : 36|2@1+ (1,0) [0|3] "" Vector__XXX
 SG_ ChargePLDueToBatTemp : 34|2@1+ (1,0) [0|3] "" Vector__XXX
 SG_ ChargePLDueToStOfCharge : 32|2@1+ (1,0) [0|3] "" Vector__XXX
 SG_ DisPLDueToAnUndefinedCause : 10|2@1+ (1,0) [0|3] "" Vector__XXX
 SG_ DisPLDueToBatCur : 8|2@1+ (1,0) [0|3] "" Vector__XXX
 SG_ DisPLDueToBatOrCellV : 6|2@1+ (1,0) [0|3] "" Vector__XXX
 SG_ DisPLDueToBatDiagCondition : 4|2@1+ (1,0) [0|3] "" Vector__XXX
 SG_ DisPLDueToBatTemp : 2|2@1+ (1,0) [0|3] "" Vector__XXX
 SG_ DisPLDueToStOfCharge : 0|2@1+ (1,0) [0|3] "" Vector__XXX

BO_ 2364713726 HVESP16D11: 8 Vector__XXX
 SG_ ActualChargeRate : 32|16@1+ (0.05,0) [0|3212.75] "kW" Vector__XXX
 SG_ LvlNegToChassisGroundV : 16|16@1+ (0.05,0) [0|3212.75] "V" Vector__XXX
 SG_ BusVNegToChassisGroundV : 0|16@1+ (0.05,0) [0|3212.75] "V" Vector__XXX

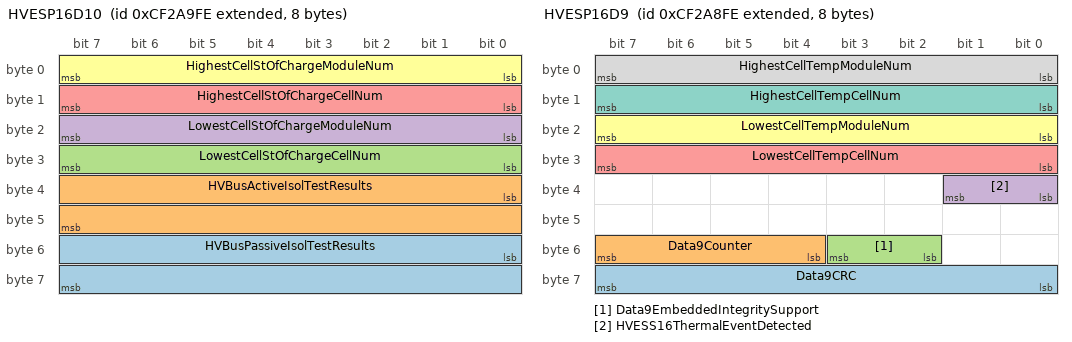
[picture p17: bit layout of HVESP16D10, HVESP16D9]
BO_ 2364713470 HVESP16D10: 8 Vector__XXX
 SG_ HVBusPassiveIsolTestResults : 48|16@1+ (0.1,0) [0|6425.5] "Ohm/V" Vector__XXX
 SG_ HVBusActiveIsolTestResults : 32|16@1+ (0.1,0) [0|6425.5] "Ohm/V" Vector__XXX
 SG_ LowestCellStOfChargeCellNum : 24|8@1+ (1,0) [0|250] "" Vector__XXX
 SG_ LowestCellStOfChargeModuleNum : 16|8@1+ (1,0) [0|250] "" Vector__XXX
 SG_ HighestCellStOfChargeCellNum : 8|8@1+ (1,0) [0|250] "" Vector__XXX
 SG_ HighestCellStOfChargeModuleNum : 0|8@1+ (1,0) [0|250] "" Vector__XXX

BO_ 2364713214 HVESP16D9: 8 Vector__XXX
 SG_ Data9CRC : 56|8@1+ (1,0) [0|255] "" Vector__XXX
 SG_ Data9Counter : 52|4@1+ (1,0) [0|15] "" Vector__XXX
 SG_ Data9EmbeddedIntegritySupport : 50|2@1+ (1,0) [0|3] "" Vector__XXX
 SG_ HVESS16ThermalEventDetected : 32|2@1+ (1,0) [0|3] "" Vector__XXX
 SG_ LowestCellTempCellNum : 24|8@1+ (1,0) [0|250] "" Vector__XXX
 SG_ LowestCellTempModuleNum : 16|8@1+ (1,0) [0|250] "" Vector__XXX
 SG_ HighestCellTempCellNum : 8|8@1+ (1,0) [0|250] "" Vector__XXX
 SG_ HighestCellTempModuleNum : 0|8@1+ (1,0) [0|250] "" Vector__XXX

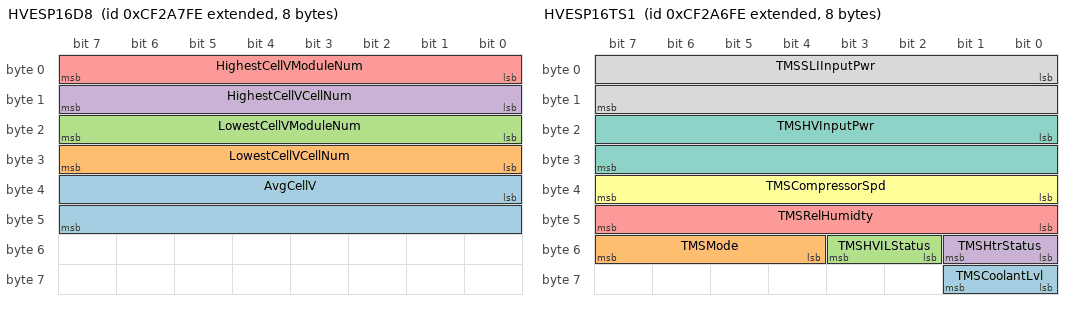
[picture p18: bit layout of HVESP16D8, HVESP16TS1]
BO_ 2364712958 HVESP16D8: 8 Vector__XXX
 SG_ AvgCellV : 32|16@1+ (0.001,0) [0|64.255] "V" Vector__XXX
 SG_ LowestCellVCellNum : 24|8@1+ (1,0) [0|250] "" Vector__XXX
 SG_ LowestCellVModuleNum : 16|8@1+ (1,0) [0|250] "" Vector__XXX
 SG_ HighestCellVCellNum : 8|8@1+ (1,0) [0|250] "" Vector__XXX
 SG_ HighestCellVModuleNum : 0|8@1+ (1,0) [0|250] "" Vector__XXX

BO_ 2364712702 HVESP16TS1: 8 Vector__XXX
 SG_ TMSCoolantLvl : 56|2@1+ (1,0) [0|3] "" Vector__XXX
 SG_ TMSMode : 52|4@1+ (1,0) [0|15] "" Vector__XXX
 SG_ TMSHVILStatus : 50|2@1+ (1,0) [0|3] "" Vector__XXX
 SG_ TMSHtrStatus : 48|2@1+ (1,0) [0|3] "" Vector__XXX
 SG_ TMSRelHumidty : 40|8@1+ (0.4,0) [0|100] "%" Vector__XXX
 SG_ TMSCompressorSpd : 32|8@1+ (32,0) [0|8000] "rpm" Vector__XXX
 SG_ TMSHVInputPwr : 16|16@1+ (0.5,0) [0|32127.5] "W" Vector__XXX
 SG_ TMSSLIInputPwr : 0|16@1+ (0.5,0) [0|32127.5] "W" Vector__XXX

CM_ BO_ 2364723454 "High Voltage Energy Storage Pack 19 Status 1
Status data set 1 for High Voltage Energy Storage Pack 19.";
CM_ SG_ 2364723454 Status1CRC "The CRC is defined as follows:
• Length: 8 bits
• Polynomial: x^8+x^5+x^3+x^2+x+1
• Initial Value: FFh
• Input Data Reflection: Not reflected
• Result Data Reflection: Not reflected
• XOR value: FFh
SAE makes no claim of the functional safety ...";
CM_ SG_ 2364723454 Status1Counter "The message counter is used to detect situations where the transmitting ECU malfunction repeats the same frame all the time. The receiver of the information may use the counter parameter to detect this situation. The transmitting device will ...";
CM_ SG_ 2364723454 OperationalStatus "Provides feedback on where this High Voltage Energy Storage Pack instance is in its operating spectrum, and includes feedback in response to the Operation Consent [i.e. SPN 16411 (HVESP19 Operation Consent)] and Power Down Command [i.e. SPN 16406 ...";
CM_ SG_ 2364723454 HVBusConnectionStatus "This parameter provides high level feedback on this High Voltage Energy Storage Pack instance high voltage bus connection. For specific contactor information, see SPN 16453 (HVESP19 High-Voltage Bus (Positive) Contactor State), SPN 16454 (HVESP19 ...";
CM_ SG_ 2364723454 InternalChargerStatus "Indicates that the charger in this HVES instance is on.  External chargers may use the External Energy Source Connection Status (SPN 7898) and related SPs.
This parameter is for one of multiple packs in an HVESS. If there is only one pack in the ...";
CM_ SG_ 2364723454 CellBalancingActive "Indicates whether or not the cells in this High Voltage Energy Storage Pack instance are currently being balanced.
This parameter is for one of multiple packs in an HVESS.  If there is only one pack in the system, the HVESS parameters should be ...";
CM_ SG_ 2364723454 CellBalanceStatus "Indicates whether or not the cells in this High Voltage Energy Storage Pack instance are balanced.
This parameter is for one of multiple packs in an HVESS.  If there is only one pack in the system, the HVESS parameters should be used. If there are ...";
CM_ SG_ 2364723454 StOfChargeStatus "Status of this High Voltage Energy Storage Pack instance State of Charge (SOC).  Note:  A given HVES controller may not support all of the states.
This parameter is for one of multiple packs in an HVESS.  If there is only one pack in the system, ...";
CM_ SG_ 2364723454 InertiaSwStatus "Switch indicating that an impact has been sensed by this High Voltage Energy Storage Pack instance. The impact indication may require action by another controller, or by this HVES instance itself.  For example, a controller may elect to take this ...";
CM_ SG_ 2364723454 HVILStatus "Status of the High Voltage Interlock Loop from the viewpoint of this High Voltage Energy Storage Pack instance.
This parameter is for one of multiple packs in an HVESS. If there is only one pack in the system, the HVESS parameters should be used ...";
CM_ SG_ 2364723454 HVBusPassiveIsolTestStatus "Status of the high-voltage bus electrical passive isolation test as performed by this High Voltage Energy Storage Pack instance.
This parameter is for one of multiple packs in an HVESS. If there is only one pack in the system, the HVESS parameters ...";
CM_ SG_ 2364723454 HVBusActiveIsolTestStatus "Status of the high-voltage bus electrical active isolation test as performed by this High Voltage Energy Storage Pack instance.
This parameter is for one of multiple packs in an HVESS. If there is only one pack in the system, the HVESS parameters ...";
CM_ SG_ 2364723454 CenterOfPackContactorSt "Position of the center high-voltage contactor. When this contactor is closed, the positive half of this High Voltage Energy Storage Pack instance is connected to the negative half. If a system controls the positive, negative, and center contactors ...";
CM_ SG_ 2364723454 HVBusPreChargeRelaySt "Position of the high-voltage bus contactor pre-charge relay.  When this relay is closed, this High Voltage Energy Storage Pack instance is bringing the high-voltage bus up to its operating level.
This parameter is for one of multiple packs in an ...";
CM_ SG_ 2364723454 HVBusDisconnectForewarning "Indicates that this High Voltage Energy Storage Pack instance is about to disconnect from the high voltage bus due to unacceptable conditions.
This parameter is for one of multiple packs in an HVESS. If there is only one pack in the system, the ...";
CM_ SG_ 2364723454 HVBusContactorSt16454 "Position of this High Voltage Energy Storage Pack instance negative side bus contactor. When this contactor is closed, the negative side of this HVES instance is connected to the negative side of the high-voltage bus. If a system controls the ...";
CM_ SG_ 2364723454 HVBusContactorSt "Position of this High Voltage Energy Storage Pack instance positive side bus contactor.  When this contactor is closed, the positive side of this HVES instance is connected to the positive side of the high-voltage bus.  In systems where all ...";
CM_ BO_ 2364723198 "High Voltage Energy Storage Pack 19 Data 6
Data set 6 (external or interface data) for High Voltage Energy Storage Pack 19.";
CM_ SG_ 2364723198 Temp "The temperature of this High Voltage Energy Storage Pack instance. The value may be determined from a unique sensor specifically for this purpose, or by aggregating various temperature sensor readings within the pack.
This parameter is for one of ...";
CM_ SG_ 2364723198 ETemp "The temperature of the electronics or control modules in this High Voltage Energy Storage Pack instance.  If there are multiple temperature sensors then this parameter would be set to the maximum sensor reading.
This parameter is for one of ...";
CM_ SG_ 2364723198 OutCoolantTemp "The temperature of liquid coolant as it exits this High Voltage Energy Storage Pack instance.
This parameter is for one of multiple packs in an HVESS.  If there is only one pack in the system, the HVESS parameters should be used. If there are ...";
CM_ SG_ 2364723198 InCoolantTemp "The temperature of liquid coolant as it enters this High Voltage Energy Storage Pack instance.
This parameter is for one of multiple packs in an HVESS.  If there is only one pack in the system, the HVESS parameters should be used. If there are ...";
CM_ SG_ 2364723198 IgntV "The voltage level at the ignition input of this High Voltage Energy Storage Pack controller.
This parameter is for one of multiple packs in an HVESS.  If there is only one pack in the system, the HVESS parameters should be used.  If there are ...";
CM_ SG_ 2364723198 BusV "The voltage level of the high voltage bus, as measured by this High Voltage Energy Storage Pack instance on the bus side (not the battery side) of its contactors.
This parameter is for one of multiple packs in an HVESS.  If there is only one pack ...";
CM_ BO_ 2364722942 "High Voltage Energy Storage Pack 19 Data 5
Data set 5 (electrical data) for High Voltage Energy Storage Pack 19.";
CM_ SG_ 2364722942 HighestCellStOfCharge "Indicates the state of charge of the highest-charged cell in this High Voltage Energy Storage Pack instance. 0% means no charge remaining, 100% means the cell is fully charged. If a single state of charge value covers more than one cell, the value ...";
CM_ SG_ 2364722942 LowestCellStOfCharge "Indicates the state of charge of the lowest-charged cell in this High Voltage Energy Storage Pack instance. 0% means no charge remaining, 100% means the cell is fully charged. If a single state of charge value covers more than one cell, the value in ...";
CM_ SG_ 2364722942 ChargeCurLmt "The maximum instantaneous current flow limit into this High Voltage Energy Storage Pack instance. This parameter is defined from the high voltage energy storage pack's point of view and should reflect the instantaneous capability of the pack.  The ...";
CM_ SG_ 2364722942 DisCurLmt "The maximum instantaneous current flow limit out of this High Voltage Energy Storage Pack instance. This parameter is defined from the high voltage energy storage pack's point of view and should reflect the instantaneous capability of the pack.  The ...";
CM_ BO_ 2364722686 "High Voltage Energy Storage Pack 19 Data 4
Data set 4 (electrical data) for High Voltage Energy Storage Pack 19.";
CM_ SG_ 2364722686 CellBalancingCount "The number of cells that are currently being balanced in this High Voltage Energy Storage Pack instance.
This parameter is for one of multiple packs in an HVESS.  If there is only one pack in the system, the HVESS parameters should be used.  If ...";
CM_ SG_ 2364722686 ChargeCapacity "The amount of unused electrical charge storage in this High Voltage Energy Storage Pack instance that is available to be filled by charging, i.e. “how much empty space is remaining in the tank”. See SPN 16471 (HVESP19 Charge Energy Capacity) for ...";
CM_ SG_ 2364722686 DisCapacity "The amount of stored electrical charge in this High Voltage Energy Storage Pack instance that is available for use by the hybrid system, i.e. “how full is the tank”. See SPN 16470 (HVESP19 Discharge Energy Capacity) for kilowatt-hours (kWh).
This ...";
CM_ BO_ 2364722430 "High Voltage Energy Storage Pack 19 Data 3
Data set 3 (thermal data) for High Voltage Energy Storage Pack 19.";
CM_ SG_ 2364722430 CellTempDiffStatus "Indicates whether or not the differential between the highest and lowest cell temperatures are within acceptable limits per this High Voltage Energy Storage Pack instance. The actual temperature differential can be calculated by subtracting SPN ...";
CM_ SG_ 2364722430 AvgCellTemp "The average temperature level of all cells in this High Voltage Energy Storage Pack instance.
This parameter is for one of multiple packs in an HVESS.  If there is only one pack in the system, the HVESS parameters should be used.  If there are ...";
CM_ SG_ 2364722430 LowestCellTemp "The lowest temperature level reported by any cell in this High Voltage Energy Storage Pack instance. If a single temperature sensor covers more than one cell, the value in this parameter is for the smallest group of cells measured. See SPN 16520 ...";
CM_ SG_ 2364722430 HighestCellTemp "The highest temperature level reported by any cell in this High Voltage Energy Storage Pack instance. If a single temperature sensor covers more than one cell, the value in this parameter is for the smallest group of cells measured. See SPN 16518 ...";
CM_ BO_ 2364722174 "High Voltage Energy Storage Pack 19 Data 2
Data set 2 (electrical data) for High Voltage Energy Storage Pack 19.";
CM_ SG_ 2364722174 CellVDiffStatus "Indicates whether or not the differential between the highest and lowest cell voltages are within acceptable limits, according to this High Voltage Energy Storage Pack instance. The actual voltage differential can be calculated by subtracting SPN ...";
CM_ SG_ 2364722174 LowestCellV "The lowest voltage level reported by any cell in this High Voltage Energy Storage Pack instance. If a single voltage sensor covers more than one cell, the value in this parameter is for the smallest group of cells measured. See SPN 16515 (HVESP19 ...";
CM_ SG_ 2364722174 HighestCellV "The highest voltage level reported by any cell in this High Voltage Energy Storage Pack instance. If a single voltage sensor covers more than one cell, the value in this parameter is for the smallest group of cells measured. See SPN 16513 (HVESP19 ...";
CM_ SG_ 2364722174 FastUpdateStOfCharge "Indicates this High Voltage Energy Storage Pack instance state of charge. 0% means no charge remaining, 100% means the system is fully charged in terms of physical limits of this energy storage pack instance. Acceptable state of charge upper and ...";
CM_ BO_ 2364721918 "High Voltage Energy Storage Pack 19 Data 1
Data set 1 (electrical data) for High Voltage Energy Storage Pack 19.";
CM_ SG_ 2364721918 Cur "The current in or out of this High Voltage Energy Storage Pack instance. This parameter should be synchronized with SPN 16430 (HVESP19 Voltage Level) such that a realized power value can be calculated. This parameter is defined from the high voltage ...";
CM_ SG_ 2364721918 Lvl "The voltage level of this High Voltage Energy Storage Pack instance. This parameter should be synchronized with SPN 16431 (HVESP19 Current) such that a realized power value can be calculated. If the HVES component physically contains the contactors ...";
CM_ SG_ 2364721918 AvailableChargePwr "The rate at which this High Voltage Energy Storage Pack instance can currently receive energy from a regenerative or recharging system.
This parameter is for one of multiple packs in an HVESS.  If there is only one pack in the system, the HVESS ...";
CM_ SG_ 2364721918 AvailableDisPwr "The rate at which this High Voltage Energy Storage Pack instance can currently provide energy for propulsion or other uses.
This parameter is for one of multiple packs in an HVESS.  If there is only one pack in the system, the HVESS parameters ...";
CM_ BO_ 2364721662 "High Voltage Energy Storage Pack 19 Status 2
Status data set 2 for High Voltage Energy Storage Pack 19.";
CM_ SG_ 2364721662 ChargePLDueToAnUndefinedCause "Indicates whether or not charge power of this HVES instance is being limited due to an undefined cause.
This parameter is for one of multiple packs in an HVESS.  If there is only one pack in the system, the HVESS parameters should be used. If there ...";
CM_ SG_ 2364721662 ChargePLDueToBatCur "Indicates whether or not charge power of this HVES instance is being limited due to battery current.
This parameter is for one of multiple packs in an HVESS.  If there is only one pack in the system, the HVESS parameters should be used. If there ...";
CM_ SG_ 2364721662 ChargePLDueToBatOrCellV "Indicates whether or not charge power of this HVES instance is being limited due to a battery or cell voltage level.
This parameter is for one of multiple packs in an HVESS.  If there is only one pack in the system, the HVESS parameters should be ...";
CM_ SG_ 2364721662 ChargePLDueToBatDiagCondition "Indicates whether or not charge power of this HVES instance is being limited due to a battery diagnostic condition.
This parameter is for one of multiple packs in an HVESS.  If there is only one pack in the system, the HVESS parameters should be ...";
CM_ SG_ 2364721662 ChargePLDueToBatTemp "Indicates whether or not charge power of this HVES instance is being limited due to battery temperature.
This parameter is for one of multiple packs in an HVESS.  If there is only one pack in the system, the HVESS parameters should be used. If ...";
CM_ SG_ 2364721662 ChargePLDueToStOfCharge "Indicates whether or not charge power of this HVES instance is being limited due to state of charge.
This parameter is for one of multiple packs in an HVESS.  If there is only one pack in the system, the HVESS parameters should be used. If there ...";
CM_ SG_ 2364721662 DisPLDueToAnUndefinedCause "Indicates whether or not discharge power of this HVES instance is being limited due to an undefined cause.
This parameter is for one of multiple packs in an HVESS.  If there is only one pack in the system, the HVESS parameters should be used. If ...";
CM_ SG_ 2364721662 DisPLDueToBatCur "Indicates whether or not discharge power of this HVES instance is being limited due to battery current.
This parameter is for one of multiple packs in an HVESS.  If there is only one pack in the system, the HVESS parameters should be used. If there ...";
CM_ SG_ 2364721662 DisPLDueToBatOrCellV "Indicates whether or not discharge power of this HVES instance is being limited due to a battery or cell voltage level.
This parameter is for one of multiple packs in an HVESS.  If there is only one pack in the system, the HVESS parameters should ...";
CM_ SG_ 2364721662 DisPLDueToBatDiagCondition "Indicates whether or not discharge power of this HVES instance is being limited due to a battery diagnostic condition.
This parameter is for one of multiple packs in an HVESS.  If there is only one pack in the system, the HVESS parameters should be ...";
CM_ SG_ 2364721662 DisPLDueToBatTemp "Indicates whether or not discharge power of this HVES instance is being limited due to battery temperature.
This parameter is for one of multiple packs in an HVESS.  If there is only one pack in the system, the HVESS parameters should be used. If ...";
CM_ SG_ 2364721662 DisPLDueToStOfCharge "Indicates whether or not discharge power of this HVES instance is being limited due to state of charge.
This parameter is for one of multiple packs in an HVESS.  If there is only one pack in the system, the HVESS parameters should be used. If there ...";
CM_ BO_ 2364721406 "High Voltage Energy Storage Pack 18 Data 11
Data set 11 (electrical data) for High Voltage Energy Storage Pack 18.";
CM_ SG_ 2364721406 ActualChargeRate "This signal represents the actual present charge rate of this High Voltage Energy Storage Pack instance.
This parameter is for one of multiple packs in an HVESS. If there is only one pack in the system, the HVESS parameters should be used. If there ...";
CM_ SG_ 2364721406 LvlNegToChassisGroundV "Voltage difference between the most negative terminal of the HVES battery and chassis measured at the battery side of any HVES contained output contactor.  This voltage may be used for system level monitoring of battery shorts to chassis within the ...";
CM_ SG_ 2364721406 BusVNegToChassisGroundV "Voltage difference between the most negative terminal of the HVES battery and chassis measured on the hybrid system bus side (not the battery side) of any HVES contained output contactor.  This voltage may be used for system level monitoring of ...";
CM_ BO_ 2364721150 "High Voltage Energy Storage Pack 18 Data 10
Data set 10 (electrical) for High Voltage Energy Storage Pack 18.";
CM_ SG_ 2364721150 HVBusPassiveIsolTestResults "The isolation resistance expressed in Ohms per Volt that resulted from the High-Voltage Bus Passive Isolation Test.
See SPN 16317 (HVESP18 High-Voltage Bus Passive Isolation Test Status) for test status and SPN 16266 (HVESP18 High-Voltage Bus ...";
CM_ SG_ 2364721150 HVBusActiveIsolTestResults "The isolation resistance expressed in Ohms per Volt that resulted from the High-Voltage Bus Active Isolation Test.
See SPN 16316 (HVESP18 High-Voltage Bus Active Isolation Test Status) for test status and SPN 16265 (HVESP18 High-Voltage Bus Active ...";
CM_ SG_ 2364721150 LowestCellStOfChargeCellNum "Identifies the location of SPN 16303 (HVESP18 Lowest Cell State of Charge) within SPN 16382 (HVESP18 Lowest Cell State of Charge Module Number).
This parameter is for one of multiple packs in an HVESS. If there is only one pack in the system, the ...";
CM_ SG_ 2364721150 LowestCellStOfChargeModuleNum "Identifies the location of the module containing SPN 16303 (HVESP18 Lowest Cell State of Charge).
This parameter is for one of multiple packs in an HVESS. If there is only one pack in the system, the HVESS parameters should be used. If there are ...";
CM_ SG_ 2364721150 HighestCellStOfChargeCellNum "Identifies the location of SPN 16304 (HVESP18 Highest Cell State of Charge) within SPN 16380 (HVESP18 Highest Cell State of Charge Module Number).
This parameter is for one of multiple packs in an HVESS. If there is only one pack in the system, the ...";
CM_ SG_ 2364721150 HighestCellStOfChargeModuleNum "Identifies the location of the module containing SPN 16304 (HVESP18 Highest Cell State of Charge).
This parameter is for one of multiple packs in an HVESS. If there is only one pack in the system, the HVESS parameters should be used. If there are ...";
CM_ BO_ 2364720894 "High Voltage Energy Storage Pack 18 Data 9
Data set 9 (thermal) for High Voltage Energy Storage Pack 18.";
CM_ SG_ 2364720894 Data9CRC "The CRC is defined as follows:
• Length: 8 bits
• Polynomial: x^8+x^5+x^3+x^2+x+1
• Initial Value: FFh
• Input Data Reflection: Not reflected
• Result Data Reflection: Not reflected
• XOR value: FFh
SAE makes no claim of the functional safety ...";
CM_ SG_ 2364720894 Data9Counter "The message counter is used to detect situations where the transmitting ECU malfunction repeats the same frame all the time. The receiver of the information may use the counter parameter to detect this situation. The transmitting device will ...";
CM_ SG_ 2364720894 Data9EmbeddedIntegritySupport "Indicates SPN 23027 (HVESP18 Data 9 CRC) and SPN 23026 (HVESP18 Data 9 Counter) are supported by the sender.
00b = Embedded CRC and Counter are supported by the sender
01b = Protection is supported using J1939-76 SHM
10b = Reserved
11b = CRC and ...";
CM_ SG_ 2364720894 HVESS18ThermalEventDetected "A sensor has detected the presence of a thermal event at or near High Voltage Energy Storage Pack instance.
00b = No Thermal Event Detected
01b = Thermal Event Detected
10b = Error
11b = Not available
This parameter is for one of multiple packs ...";
CM_ SG_ 2364720894 LowestCellTempCellNum "Identifies the location of SPN 16295 (HVESP18 Lowest Cell Temperature) within SPN 16378 (HVESP18 Lowest Cell Temperature Module Number).
This parameter is for one of multiple packs in an HVESS. If there is only one pack in the system, the HVESS ...";
CM_ SG_ 2364720894 LowestCellTempModuleNum "Identifies the location of the module containing SPN 16295 (HVESP18 Lowest Cell Temperature).
This parameter is for one of multiple packs in an HVESS. If there is only one pack in the system, the HVESS parameters should be used. If there are ...";
CM_ SG_ 2364720894 HighestCellTempCellNum "Identifies the location of SPN 16294 (HVESP18 Highest Cell Temperature) within SPN 16376 (HVESP18 Highest Cell Temperature Module Number).
This parameter is for one of multiple packs in an HVESS. If there is only one pack in the system, the HVESS ...";
CM_ SG_ 2364720894 HighestCellTempModuleNum "Identifies the location of the module containing SPN 16294 (HVESP18 Highest Cell Temperature).
This parameter is for one of multiple packs in an HVESS. If there is only one pack in the system, the HVESS parameters should be used. If there are ...";
CM_ BO_ 2364720638 "High Voltage Energy Storage Pack 18 Data 8
Data set 8 (electrical data) for High Voltage Energy Storage Pack 18.";
CM_ SG_ 2364720638 AvgCellV "The average cell voltage in this High Voltage Energy Storage Pack instance.
This parameter is for one of multiple packs in an HVESS.  If there is only one pack in the system, the HVESS parameters should be used. If there are multiple packs in the ...";
CM_ SG_ 2364720638 LowestCellVCellNum "Identifies the location of SPN 16292 (HVESP18 Lowest Cell Voltage) within SPN 16373 (HVESP18 Lowest Cell Voltage Module Number).
This parameter is for one of multiple packs in an HVESS. If there is only one pack in the system, the HVESS parameters ...";
CM_ SG_ 2364720638 LowestCellVModuleNum "Identifies the location of the module containing SPN 16292 (HVESP18 Lowest Cell Voltage).
This parameter is for one of multiple packs in an HVESS. If there is only one pack in the system, the HVESS parameters should be used. If there are multiple ...";
CM_ SG_ 2364720638 HighestCellVCellNum "Identifies the location of SPN 16291 (HVESP18 Highest Cell Voltage) within SPN 16371 (HVESP18 Highest Cell Voltage Module Number).
This parameter is for one of multiple packs in an HVESS. If there is only one pack in the system, the HVESS ...";
CM_ SG_ 2364720638 HighestCellVModuleNum "Identifies the location of the module containing SPN 16291 (HVESP18 Highest Cell Voltage).
This parameter is for one of multiple packs in an HVESS. If there is only one pack in the system, the HVESS parameters should be used. If there are multiple ...";
CM_ BO_ 2364720382 "High Voltage Energy Storage Pack 18 Thermal Management System Status 1
Collection of data the High Voltage Energy Storage Pack 18 Thermal Management System sends to the Hybrid Controller.";
CM_ SG_ 2364720382 TMSCoolantLvl "Indicates the coolant level in this HVES Thermal Management System (TMS).
This parameter is for one of multiple packs in an HVESS.  If there is only one pack in the system, the HVESS parameters should be used. If there are multiple packs in the ...";
CM_ SG_ 2364720382 TMSMode "Indicates the operating mode of the Thermal Management System.  The heat transfer medium may be (e.g. liquid or air).  The cooling system may be fans, liquid coolant, or a combination of mediums.  The system may include an air and/or liquid ...";
CM_ SG_ 2364720382 TMSHVILStatus "In multiple HVES configurations, this is the status of the High Voltage Interlock Loop from the viewpoint of this Thermal Management System.
00b = HVIL Closed
01b = HVIL Open
10b = Error
11b = Not Available
This parameter is for one of multiple ...";
CM_ SG_ 2364720382 TMSHtrStatus "The state of this High Voltage Energy Storage Pack heater
This parameter is for one of multiple packs in an HVESS.  If there is only one pack in the system, the HVESS parameters should be used. If there are multiple packs in the system, then both ...";
CM_ SG_ 2364720382 TMSRelHumidty "When this High Voltage Energy Storage Pack Thermal Management System is equipped with a relative humidity sensor, this is the  measured Relative Humidity.
This parameter is for one of multiple packs in an HVESS.  If there is only one pack in the ...";
CM_ SG_ 2364720382 TMSCompressorSpd "When this High Voltage Energy Storage Pack Thermal Management System is equipped with an active cooling system (e.g. air conditioner), this is the Compressor Speed.
This parameter is for one of multiple packs in an HVESS.  If there is only one pack ...";
CM_ SG_ 2364720382 TMSHVInputPwr "This is the high-voltage power consumed by this HVES Thermal Management System (TMS).
This parameter is for one of multiple packs in an HVESS.  If there is only one pack in the system, the HVESS parameters should be used. If there are multiple ...";
CM_ SG_ 2364720382 TMSSLIInputPwr "This is the low-voltage power consumed by this HVES Thermal Management System (TMS).
This parameter is for one of multiple packs in an HVESS.  If there is only one pack in the system, the HVESS parameters should be used.  If there are multiple ...";
CM_ BO_ 2364720126 "High Voltage Energy Storage Pack 18 Module Status 1
Module Status message 1 for High Voltage Energy Storage Pack 18.";
CM_ SG_ 2364720126 Module32OperationalStatus "Operational Status of Module 32 in this High Voltage Energy Storage Pack Instance.  Not Operational is used when the module is initializing or not able to function (e.g. internal module level monitors have failed).  Operational indicates that the ...";
CM_ SG_ 2364720126 Module31OperationalStatus "Operational Status of Module 31 in this High Voltage Energy Storage Pack Instance.  Not Operational is used when the module is initializing or not able to function (e.g. internal module level monitors have failed).  Operational indicates that the ...";
CM_ SG_ 2364720126 Module30OperationalStatus "Operational Status of Module 30 in this High Voltage Energy Storage Pack Instance.  Not Operational is used when the module is initializing or not able to function (e.g. internal module level monitors have failed).  Operational indicates that the ...";
CM_ SG_ 2364720126 Module29OperationalStatus "Operational Status of Module 29 in this High Voltage Energy Storage Pack Instance.  Not Operational is used when the module is initializing or not able to function (e.g. internal module level monitors have failed).  Operational indicates that the ...";
CM_ SG_ 2364720126 Module28OperationalStatus "Operational Status of Module 28 in this High Voltage Energy Storage Pack Instance.  Not Operational is used when the module is initializing or not able to function (e.g. internal module level monitors have failed).  Operational indicates that the ...";
CM_ SG_ 2364720126 Module27OperationalStatus "Operational Status of Module 27 in this High Voltage Energy Storage Pack Instance.  Not Operational is used when the module is initializing or not able to function (e.g. internal module level monitors have failed).  Operational indicates that the ...";
CM_ SG_ 2364720126 Module26OperationalStatus "Operational Status of Module 26 in this High Voltage Energy Storage Pack Instance.  Not Operational is used when the module is initializing or not able to function (e.g. internal module level monitors have failed).  Operational indicates that the ...";
CM_ SG_ 2364720126 Module25OperationalStatus "Operational Status of Module 25 in this High Voltage Energy Storage Pack Instance.  Not Operational is used when the module is initializing or not able to function (e.g. internal module level monitors have failed).  Operational indicates that the ...";
CM_ SG_ 2364720126 Module24OperationalStatus "Operational Status of Module 24 in this High Voltage Energy Storage Pack Instance.  Not Operational is used when the module is initializing or not able to function (e.g. internal module level monitors have failed).  Operational indicates that the ...";
CM_ SG_ 2364720126 Module23OperationalStatus "Operational Status of Module 23 in this High Voltage Energy Storage Pack Instance.  Not Operational is used when the module is initializing or not able to function (e.g. internal module level monitors have failed).  Operational indicates that the ...";
CM_ SG_ 2364720126 Module22OperationalStatus "Operational Status of Module 22 in this High Voltage Energy Storage Pack Instance.  Not Operational is used when the module is initializing or not able to function (e.g. internal module level monitors have failed).  Operational indicates that the ...";
CM_ SG_ 2364720126 Module21OperationalStatus "Operational Status of Module 21 in this High Voltage Energy Storage Pack Instance.  Not Operational is used when the module is initializing or not able to function (e.g. internal module level monitors have failed).  Operational indicates that the ...";
CM_ SG_ 2364720126 Module20OperationalStatus "Operational Status of Module 20 in this High Voltage Energy Storage Pack Instance.  Not Operational is used when the module is initializing or not able to function (e.g. internal module level monitors have failed).  Operational indicates that the ...";
CM_ SG_ 2364720126 Module19OperationalStatus "Operational Status of Module 19 in this High Voltage Energy Storage Pack Instance.  Not Operational is used when the module is initializing or not able to function (e.g. internal module level monitors have failed).  Operational indicates that the ...";
CM_ SG_ 2364720126 Module18OperationalStatus "Operational Status of Module 18 in this High Voltage Energy Storage Pack Instance.  Not Operational is used when the module is initializing or not able to function (e.g. internal module level monitors have failed).  Operational indicates that the ...";
CM_ SG_ 2364720126 Module17OperationalStatus "Operational Status of Module 17 in this High Voltage Energy Storage Pack Instance.  Not Operational is used when the module is initializing or not able to function (e.g. internal module level monitors have failed).  Operational indicates that the ...";
CM_ SG_ 2364720126 Module16OperationalStatus "Operational Status of Module 16 in this High Voltage Energy Storage Pack Instance.  Not Operational is used when the module is initializing or not able to function (e.g. internal module level monitors have failed).  Operational indicates that the ...";
CM_ SG_ 2364720126 Module15OperationalStatus "Operational Status of Module 15 in this High Voltage Energy Storage Pack Instance.  Not Operational is used when the module is initializing or not able to function (e.g. internal module level monitors have failed).  Operational indicates that the ...";
CM_ SG_ 2364720126 Module14OperationalStatus "Operational Status of Module 14 in this High Voltage Energy Storage Pack Instance.  Not Operational is used when the module is initializing or not able to function (e.g. internal module level monitors have failed).  Operational indicates that the ...";
CM_ SG_ 2364720126 Module13OperationalStatus "Operational Status of Module 13 in this High Voltage Energy Storage Pack Instance.  Not Operational is used when the module is initializing or not able to function (e.g. internal module level monitors have failed).  Operational indicates that the ...";
CM_ SG_ 2364720126 Module12OperationalStatus "Operational Status of Module 12 in this High Voltage Energy Storage Pack Instance.  Not Operational is used when the module is initializing or not able to function (e.g. internal module level monitors have failed).  Operational indicates that the ...";
CM_ SG_ 2364720126 Module11OperationalStatus "Operational Status of Module 11 in this High Voltage Energy Storage Pack Instance.  Not Operational is used when the module is initializing or not able to function (e.g. internal module level monitors have failed).  Operational indicates that the ...";
CM_ SG_ 2364720126 Module10OperationalStatus "Operational Status of Module 10 in this High Voltage Energy Storage Pack Instance.  Not Operational is used when the module is initializing or not able to function (e.g. internal module level monitors have failed).  Operational indicates that the ...";
CM_ SG_ 2364720126 Module9OperationalStatus "Operational Status of Module 9 in this High Voltage Energy Storage Pack Instance.  Not Operational is used when the module is initializing or not able to function (e.g. internal module level monitors have failed).  Operational indicates that the ...";
CM_ SG_ 2364720126 Module8OperationalStatus "Operational Status of Module 8 in this High Voltage Energy Storage Pack Instance.  Not Operational is used when the module is initializing or not able to function (e.g. internal module level monitors have failed).  Operational indicates that the ...";
CM_ SG_ 2364720126 Module7OperationalStatus "Operational Status of Module 7 in this High Voltage Energy Storage Pack Instance.  Not Operational is used when the module is initializing or not able to function (e.g. internal module level monitors have failed).  Operational indicates that the ...";
CM_ SG_ 2364720126 Module6OperationalStatus "Operational Status of Module 6 in this High Voltage Energy Storage Pack Instance.  Not Operational is used when the module is initializing or not able to function (e.g. internal module level monitors have failed).  Operational indicates that the ...";
CM_ SG_ 2364720126 Module5OperationalStatus "Operational Status of Module 5 in this High Voltage Energy Storage Pack Instance.  Not Operational is used when the module is initializing or not able to function (e.g. internal module level monitors have failed).  Operational indicates that the ...";
CM_ SG_ 2364720126 Module4OperationalStatus "Operational Status of Module 4 in this High Voltage Energy Storage Pack Instance.  Not Operational is used when the module is initializing or not able to function (e.g. internal module level monitors have failed).  Operational indicates that the ...";
CM_ SG_ 2364720126 Module3OperationalStatus "Operational Status of Module 3 in this High Voltage Energy Storage Pack Instance.  Not Operational is used when the module is initializing or not able to function (e.g. internal module level monitors have failed).  Operational indicates that the ...";
CM_ SG_ 2364720126 Module2OperationalStatus "Operational Status of Module 2 in this High Voltage Energy Storage Pack Instance.  Not Operational is used when the module is initializing or not able to function (e.g. internal module level monitors have failed).  Operational indicates that the ...";
CM_ SG_ 2364720126 Module1OperationalStatus "Operational Status of Module 1 in this High Voltage Energy Storage Pack Instance.  Not Operational is used when the module is initializing or not able to function (e.g. internal module level monitors have failed).  Operational indicates that the ...";
CM_ BO_ 2364719870 "High Voltage Energy Storage Pack 18 Data 7
Data set 7 (electrical) for High Voltage Energy Storage Pack 18.";
CM_ SG_ 2364719870 MaxChargeVLmt "The maximum voltage level not to be exceeded while charging this High Voltage Energy Storage Pack instance. If this parameter is not supported, the maximum charge voltage should be limited to SPN 16397 (HVESP18 Recommended Maximum Operating ...";
CM_ SG_ 2364719870 ChargeEnergyCapacity "The amount of unused electrical energy storage available to be filled by charging this High Voltage Energy Storage Pack instance, i.e. “how much empty space is remaining in the tank”. See SPN 16299 (HVESP18 Charge Capacity) for Ampere-hours (Ah).
 ...";
CM_ SG_ 2364719870 DisEnergyCapacity "The amount of stored electrical energy in this High Voltage Energy Storage Pack instance that is available for use by the hybrid system, i.e. “how full is the tank”. See SPN 16298 (HVESP18 Discharge Capacity) for Ampere-hours (Ah).
This parameter ...";
CM_ BO_ 2364719614 "High Voltage Energy Storage Pack 18 Status 1
Status data set 1 for High Voltage Energy Storage Pack 18.";
CM_ SG_ 2364719614 Status1CRC "The CRC is defined as follows:
• Length: 8 bits
• Polynomial: x^8+x^5+x^3+x^2+x+1
• Initial Value: FFh
• Input Data Reflection: Not reflected
• Result Data Reflection: Not reflected
• XOR value: FFh
SAE makes no claim of the functional safety ...";
CM_ SG_ 2364719614 Status1Counter "The message counter is used to detect situations where the transmitting ECU malfunction repeats the same frame all the time. The receiver of the information may use the counter parameter to detect this situation. The transmitting device will ...";
CM_ SG_ 2364719614 OperationalStatus "Provides feedback on where this High Voltage Energy Storage Pack instance is in its operating spectrum, and includes feedback in response to the Operation Consent [i.e. SPN 16269 (HVESP18 Operation Consent)] and Power Down Command [i.e. SPN 16264 ...";
CM_ SG_ 2364719614 HVBusConnectionStatus "This parameter provides high level feedback on this High Voltage Energy Storage Pack instance high voltage bus connection. For specific contactor information, see SPN 16311 (HVESP18 High-Voltage Bus (Positive) Contactor State), SPN 16312 (HVESP18 ...";
CM_ SG_ 2364719614 InternalChargerStatus "Indicates that the charger in this HVES instance is on.  External chargers may use the External Energy Source Connection Status (SPN 7898) and related SPs.
This parameter is for one of multiple packs in an HVESS. If there is only one pack in the ...";
CM_ SG_ 2364719614 CellBalancingActive "Indicates whether or not the cells in this High Voltage Energy Storage Pack instance are currently being balanced.
This parameter is for one of multiple packs in an HVESS.  If there is only one pack in the system, the HVESS parameters should be ...";
CM_ SG_ 2364719614 CellBalanceStatus "Indicates whether or not the cells in this High Voltage Energy Storage Pack instance are balanced.
This parameter is for one of multiple packs in an HVESS.  If there is only one pack in the system, the HVESS parameters should be used. If there are ...";
CM_ SG_ 2364719614 StOfChargeStatus "Status of this High Voltage Energy Storage Pack instance State of Charge (SOC).  Note:  A given HVES controller may not support all of the states.
This parameter is for one of multiple packs in an HVESS.  If there is only one pack in the system, ...";
CM_ SG_ 2364719614 InertiaSwStatus "Switch indicating that an impact has been sensed by this High Voltage Energy Storage Pack instance. The impact indication may require action by another controller, or by this HVES instance itself.  For example, a controller may elect to take this ...";
CM_ SG_ 2364719614 HVILStatus "Status of the High Voltage Interlock Loop from the viewpoint of this High Voltage Energy Storage Pack instance.
This parameter is for one of multiple packs in an HVESS. If there is only one pack in the system, the HVESS parameters should be used ...";
CM_ SG_ 2364719614 HVBusPassiveIsolTestStatus "Status of the high-voltage bus electrical passive isolation test as performed by this High Voltage Energy Storage Pack instance.
This parameter is for one of multiple packs in an HVESS. If there is only one pack in the system, the HVESS parameters ...";
CM_ SG_ 2364719614 HVBusActiveIsolTestStatus "Status of the high-voltage bus electrical active isolation test as performed by this High Voltage Energy Storage Pack instance.
This parameter is for one of multiple packs in an HVESS. If there is only one pack in the system, the HVESS parameters ...";
CM_ SG_ 2364719614 CenterOfPackContactorSt "Position of the center high-voltage contactor. When this contactor is closed, the positive half of this High Voltage Energy Storage Pack instance is connected to the negative half. If a system controls the positive, negative, and center contactors ...";
CM_ SG_ 2364719614 HVBusPreChargeRelaySt "Position of the high-voltage bus contactor pre-charge relay.  When this relay is closed, this High Voltage Energy Storage Pack instance is bringing the high-voltage bus up to its operating level.
This parameter is for one of multiple packs in an ...";
CM_ SG_ 2364719614 HVBusDisconnectForewarning "Indicates that this High Voltage Energy Storage Pack instance is about to disconnect from the high voltage bus due to unacceptable conditions.
This parameter is for one of multiple packs in an HVESS. If there is only one pack in the system, the ...";
CM_ SG_ 2364719614 HVBusContactorSt16312 "Position of this High Voltage Energy Storage Pack instance negative side bus contactor. When this contactor is closed, the negative side of this HVES instance is connected to the negative side of the high-voltage bus. If a system controls the ...";
CM_ SG_ 2364719614 HVBusContactorSt "Position of this High Voltage Energy Storage Pack instance positive side bus contactor.  When this contactor is closed, the positive side of this HVES instance is connected to the positive side of the high-voltage bus.  In systems where all ...";
CM_ BO_ 2364719358 "High Voltage Energy Storage Pack 18 Data 6
Data set 6 (external or interface data) for High Voltage Energy Storage Pack 18.";
CM_ SG_ 2364719358 Temp "The temperature of this High Voltage Energy Storage Pack instance. The value may be determined from a unique sensor specifically for this purpose, or by aggregating various temperature sensor readings within the pack.
This parameter is for one of ...";
CM_ SG_ 2364719358 ETemp "The temperature of the electronics or control modules in this High Voltage Energy Storage Pack instance.  If there are multiple temperature sensors then this parameter would be set to the maximum sensor reading.
This parameter is for one of ...";
CM_ SG_ 2364719358 OutCoolantTemp "The temperature of liquid coolant as it exits this High Voltage Energy Storage Pack instance.
This parameter is for one of multiple packs in an HVESS.  If there is only one pack in the system, the HVESS parameters should be used. If there are ...";
CM_ SG_ 2364719358 InCoolantTemp "The temperature of liquid coolant as it enters this High Voltage Energy Storage Pack instance.
This parameter is for one of multiple packs in an HVESS.  If there is only one pack in the system, the HVESS parameters should be used. If there are ...";
CM_ SG_ 2364719358 IgntV "The voltage level at the ignition input of this High Voltage Energy Storage Pack controller.
This parameter is for one of multiple packs in an HVESS.  If there is only one pack in the system, the HVESS parameters should be used.  If there are ...";
CM_ SG_ 2364719358 BusV "The voltage level of the high voltage bus, as measured by this High Voltage Energy Storage Pack instance on the bus side (not the battery side) of its contactors.
This parameter is for one of multiple packs in an HVESS.  If there is only one pack ...";
CM_ BO_ 2364719102 "High Voltage Energy Storage Pack 18 Data 5
Data set 5 (electrical data) for High Voltage Energy Storage Pack 18.";
CM_ SG_ 2364719102 HighestCellStOfCharge "Indicates the state of charge of the highest-charged cell in this High Voltage Energy Storage Pack instance. 0% means no charge remaining, 100% means the cell is fully charged. If a single state of charge value covers more than one cell, the value ...";
CM_ SG_ 2364719102 LowestCellStOfCharge "Indicates the state of charge of the lowest-charged cell in this High Voltage Energy Storage Pack instance. 0% means no charge remaining, 100% means the cell is fully charged. If a single state of charge value covers more than one cell, the value in ...";
CM_ SG_ 2364719102 ChargeCurLmt "The maximum instantaneous current flow limit into this High Voltage Energy Storage Pack instance. This parameter is defined from the high voltage energy storage pack's point of view and should reflect the instantaneous capability of the pack.  The ...";
CM_ SG_ 2364719102 DisCurLmt "The maximum instantaneous current flow limit out of this High Voltage Energy Storage Pack instance. This parameter is defined from the high voltage energy storage pack's point of view and should reflect the instantaneous capability of the pack.  The ...";
CM_ BO_ 2364718846 "High Voltage Energy Storage Pack 18 Data 4
Data set 4 (electrical data) for High Voltage Energy Storage Pack 18.";
CM_ SG_ 2364718846 CellBalancingCount "The number of cells that are currently being balanced in this High Voltage Energy Storage Pack instance.
This parameter is for one of multiple packs in an HVESS.  If there is only one pack in the system, the HVESS parameters should be used.  If ...";
CM_ SG_ 2364718846 ChargeCapacity "The amount of unused electrical charge storage in this High Voltage Energy Storage Pack instance that is available to be filled by charging, i.e. “how much empty space is remaining in the tank”. See SPN 16329 (HVESP18 Charge Energy Capacity) for ...";
CM_ SG_ 2364718846 DisCapacity "The amount of stored electrical charge in this High Voltage Energy Storage Pack instance that is available for use by the hybrid system, i.e. “how full is the tank”. See SPN 16328 (HVESP18 Discharge Energy Capacity) for kilowatt-hours (kWh).
This ...";
CM_ BO_ 2364718590 "High Voltage Energy Storage Pack 18 Data 3
Data set 3 (thermal data) for High Voltage Energy Storage Pack 18.";
CM_ SG_ 2364718590 CellTempDiffStatus "Indicates whether or not the differential between the highest and lowest cell temperatures are within acceptable limits per this High Voltage Energy Storage Pack instance. The actual temperature differential can be calculated by subtracting SPN ...";
CM_ SG_ 2364718590 AvgCellTemp "The average temperature level of all cells in this High Voltage Energy Storage Pack instance.
This parameter is for one of multiple packs in an HVESS.  If there is only one pack in the system, the HVESS parameters should be used.  If there are ...";
CM_ SG_ 2364718590 LowestCellTemp "The lowest temperature level reported by any cell in this High Voltage Energy Storage Pack instance. If a single temperature sensor covers more than one cell, the value in this parameter is for the smallest group of cells measured. See SPN 16378 ...";
CM_ SG_ 2364718590 HighestCellTemp "The highest temperature level reported by any cell in this High Voltage Energy Storage Pack instance. If a single temperature sensor covers more than one cell, the value in this parameter is for the smallest group of cells measured. See SPN 16376 ...";
CM_ BO_ 2364718334 "High Voltage Energy Storage Pack 18 Data 2
Data set 2 (electrical data) for High Voltage Energy Storage Pack 18.";
CM_ SG_ 2364718334 CellVDiffStatus "Indicates whether or not the differential between the highest and lowest cell voltages are within acceptable limits, according to this High Voltage Energy Storage Pack instance. The actual voltage differential can be calculated by subtracting SPN ...";
CM_ SG_ 2364718334 LowestCellV "The lowest voltage level reported by any cell in this High Voltage Energy Storage Pack instance. If a single voltage sensor covers more than one cell, the value in this parameter is for the smallest group of cells measured. See SPN 16373 (HVESP18 ...";
CM_ SG_ 2364718334 HighestCellV "The highest voltage level reported by any cell in this High Voltage Energy Storage Pack instance. If a single voltage sensor covers more than one cell, the value in this parameter is for the smallest group of cells measured. See SPN 16371 (HVESP18 ...";
CM_ SG_ 2364718334 FastUpdateStOfCharge "Indicates this High Voltage Energy Storage Pack instance state of charge. 0% means no charge remaining, 100% means the system is fully charged in terms of physical limits of this energy storage pack instance. Acceptable state of charge upper and ...";
CM_ BO_ 2364718078 "High Voltage Energy Storage Pack 18 Data 1
Data set 1 (electrical data) for High Voltage Energy Storage Pack 18.";
CM_ SG_ 2364718078 Cur "The current in or out of this High Voltage Energy Storage Pack instance. This parameter should be synchronized with SPN 16288 (HVESP18 Voltage Level) such that a realized power value can be calculated. This parameter is defined from the high voltage ...";
CM_ SG_ 2364718078 Lvl "The voltage level of this High Voltage Energy Storage Pack instance. This parameter should be synchronized with SPN 16289 (HVESP18 Current) such that a realized power value can be calculated. If the HVES component physically contains the contactors ...";
CM_ SG_ 2364718078 AvailableChargePwr "The rate at which this High Voltage Energy Storage Pack instance can currently receive energy from a regenerative or recharging system.
This parameter is for one of multiple packs in an HVESS.  If there is only one pack in the system, the HVESS ...";
CM_ SG_ 2364718078 AvailableDisPwr "The rate at which this High Voltage Energy Storage Pack instance can currently provide energy for propulsion or other uses.
This parameter is for one of multiple packs in an HVESS.  If there is only one pack in the system, the HVESS parameters ...";
CM_ BO_ 2364717822 "High Voltage Energy Storage Pack 18 Status 2
Status data set 2 for High Voltage Energy Storage Pack 18.";
CM_ SG_ 2364717822 ChargePLDueToAnUndefinedCause "Indicates whether or not charge power of this HVES instance is being limited due to an undefined cause.
This parameter is for one of multiple packs in an HVESS.  If there is only one pack in the system, the HVESS parameters should be used. If there ...";
CM_ SG_ 2364717822 ChargePLDueToBatCur "Indicates whether or not charge power of this HVES instance is being limited due to battery current.
This parameter is for one of multiple packs in an HVESS.  If there is only one pack in the system, the HVESS parameters should be used. If there ...";
CM_ SG_ 2364717822 ChargePLDueToBatOrCellV "Indicates whether or not charge power of this HVES instance is being limited due to a battery or cell voltage level.
This parameter is for one of multiple packs in an HVESS.  If there is only one pack in the system, the HVESS parameters should be ...";
CM_ SG_ 2364717822 ChargePLDueToBatDiagCondition "Indicates whether or not charge power of this HVES instance is being limited due to a battery diagnostic condition.
This parameter is for one of multiple packs in an HVESS.  If there is only one pack in the system, the HVESS parameters should be ...";
CM_ SG_ 2364717822 ChargePLDueToBatTemp "Indicates whether or not charge power of this HVES instance is being limited due to battery temperature.
This parameter is for one of multiple packs in an HVESS.  If there is only one pack in the system, the HVESS parameters should be used. If ...";
CM_ SG_ 2364717822 ChargePLDueToStOfCharge "Indicates whether or not charge power of this HVES instance is being limited due to state of charge.
This parameter is for one of multiple packs in an HVESS.  If there is only one pack in the system, the HVESS parameters should be used. If there ...";
CM_ SG_ 2364717822 DisPLDueToAnUndefinedCause "Indicates whether or not discharge power of this HVES instance is being limited due to an undefined cause.
This parameter is for one of multiple packs in an HVESS.  If there is only one pack in the system, the HVESS parameters should be used. If ...";
CM_ SG_ 2364717822 DisPLDueToBatCur "Indicates whether or not discharge power of this HVES instance is being limited due to battery current.
This parameter is for one of multiple packs in an HVESS.  If there is only one pack in the system, the HVESS parameters should be used. If there ...";
CM_ SG_ 2364717822 DisPLDueToBatOrCellV "Indicates whether or not discharge power of this HVES instance is being limited due to a battery or cell voltage level.
This parameter is for one of multiple packs in an HVESS.  If there is only one pack in the system, the HVESS parameters should ...";
CM_ SG_ 2364717822 DisPLDueToBatDiagCondition "Indicates whether or not discharge power of this HVES instance is being limited due to a battery diagnostic condition.
This parameter is for one of multiple packs in an HVESS.  If there is only one pack in the system, the HVESS parameters should be ...";
CM_ SG_ 2364717822 DisPLDueToBatTemp "Indicates whether or not discharge power of this HVES instance is being limited due to battery temperature.
This parameter is for one of multiple packs in an HVESS.  If there is only one pack in the system, the HVESS parameters should be used. If ...";
CM_ SG_ 2364717822 DisPLDueToStOfCharge "Indicates whether or not discharge power of this HVES instance is being limited due to state of charge.
This parameter is for one of multiple packs in an HVESS.  If there is only one pack in the system, the HVESS parameters should be used. If there ...";
CM_ BO_ 2364717566 "High Voltage Energy Storage Pack 17 Data 11
Data set 11 (electrical data) for High Voltage Energy Storage Pack 17.";
CM_ SG_ 2364717566 ActualChargeRate "This signal represents the actual present charge rate of this High Voltage Energy Storage Pack instance.
This parameter is for one of multiple packs in an HVESS. If there is only one pack in the system, the HVESS parameters should be used. If there ...";
CM_ SG_ 2364717566 LvlNegToChassisGroundV "Voltage difference between the most negative terminal of the HVES battery and chassis measured at the battery side of any HVES contained output contactor.  This voltage may be used for system level monitoring of battery shorts to chassis within the ...";
CM_ SG_ 2364717566 BusVNegToChassisGroundV "Voltage difference between the most negative terminal of the HVES battery and chassis measured on the hybrid system bus side (not the battery side) of any HVES contained output contactor.  This voltage may be used for system level monitoring of ...";
CM_ BO_ 2364717310 "High Voltage Energy Storage Pack 17 Data 10
Data set 10 (electrical) for High Voltage Energy Storage Pack 17.";
CM_ SG_ 2364717310 HVBusPassiveIsolTestResults "The isolation resistance expressed in Ohms per Volt that resulted from the High-Voltage Bus Passive Isolation Test.
See SPN 16175 (HVESP17 High-Voltage Bus Passive Isolation Test Status) for test status and SPN 16124 (HVESP17 High-Voltage Bus ...";
CM_ SG_ 2364717310 HVBusActiveIsolTestResults "The isolation resistance expressed in Ohms per Volt that resulted from the High-Voltage Bus Active Isolation Test.
See SPN 16174 (HVESP17 High-Voltage Bus Active Isolation Test Status) for test status and SPN 16123 (HVESP17 High-Voltage Bus Active ...";
CM_ SG_ 2364717310 LowestCellStOfChargeCellNum "Identifies the location of SPN 16161 (HVESP17 Lowest Cell State of Charge) within SPN 16240 (HVESP17 Lowest Cell State of Charge Module Number).
This parameter is for one of multiple packs in an HVESS. If there is only one pack in the system, the ...";
CM_ SG_ 2364717310 LowestCellStOfChargeModuleNum "Identifies the location of the module containing SPN 16161 (HVESP17 Lowest Cell State of Charge).
This parameter is for one of multiple packs in an HVESS. If there is only one pack in the system, the HVESS parameters should be used. If there are ...";
CM_ SG_ 2364717310 HighestCellStOfChargeCellNum "Identifies the location of SPN 16162 (HVESP17 Highest Cell State of Charge) within SPN 16238 (HVESP17 Highest Cell State of Charge Module Number).
This parameter is for one of multiple packs in an HVESS. If there is only one pack in the system, the ...";
CM_ SG_ 2364717310 HighestCellStOfChargeModuleNum "Identifies the location of the module containing SPN 16162 (HVESP17 Highest Cell State of Charge).
This parameter is for one of multiple packs in an HVESS. If there is only one pack in the system, the HVESS parameters should be used. If there are ...";
CM_ BO_ 2364717054 "High Voltage Energy Storage Pack 17 Data 9
Data set 9 (thermal) for High Voltage Energy Storage Pack 17.";
CM_ SG_ 2364717054 Data9CRC "The CRC is defined as follows:
• Length: 8 bits
• Polynomial: x^8+x^5+x^3+x^2+x+1
• Initial Value: FFh
• Input Data Reflection: Not reflected
• Result Data Reflection: Not reflected
• XOR value: FFh
SAE makes no claim of the functional safety ...";
CM_ SG_ 2364717054 Data9Counter "The message counter is used to detect situations where the transmitting ECU malfunction repeats the same frame all the time. The receiver of the information may use the counter parameter to detect this situation. The transmitting device will ...";
CM_ SG_ 2364717054 Data9EmbeddedIntegritySupport "Indicates SPN 23024 (HVESP17 Data 9 CRC) and SPN 23023 (HVESP17 Data 9 Counter) are supported by the sender.
00b = Embedded CRC and Counter are supported by the sender
01b = Protection is supported using J1939-76 SHM
10b = Reserved
11b = CRC and ...";
CM_ SG_ 2364717054 HVESS17ThermalEventDetected "A sensor has detected the presence of a thermal event at or near High Voltage Energy Storage Pack instance.
00b = No Thermal Event Detected
01b = Thermal Event Detected
10b = Error
11b = Not available
This parameter is for one of multiple packs ...";
CM_ SG_ 2364717054 LowestCellTempCellNum "Identifies the location of SPN 16153 (HVESP17 Lowest Cell Temperature) within SPN 16236 (HVESP17 Lowest Cell Temperature Module Number).
This parameter is for one of multiple packs in an HVESS. If there is only one pack in the system, the HVESS ...";
CM_ SG_ 2364717054 LowestCellTempModuleNum "Identifies the location of the module containing SPN 16153 (HVESP17 Lowest Cell Temperature).
This parameter is for one of multiple packs in an HVESS. If there is only one pack in the system, the HVESS parameters should be used. If there are ...";
CM_ SG_ 2364717054 HighestCellTempCellNum "Identifies the location of SPN 16152 (HVESP17 Highest Cell Temperature) within SPN 16234 (HVESP17 Highest Cell Temperature Module Number).
This parameter is for one of multiple packs in an HVESS. If there is only one pack in the system, the HVESS ...";
CM_ SG_ 2364717054 HighestCellTempModuleNum "Identifies the location of the module containing SPN 16152 (HVESP17 Highest Cell Temperature).
This parameter is for one of multiple packs in an HVESS. If there is only one pack in the system, the HVESS parameters should be used. If there are ...";
CM_ BO_ 2364716798 "High Voltage Energy Storage Pack 17 Data 8
Data set 8 (electrical data) for High Voltage Energy Storage Pack 17.";
CM_ SG_ 2364716798 AvgCellV "The average cell voltage in this High Voltage Energy Storage Pack instance.
This parameter is for one of multiple packs in an HVESS.  If there is only one pack in the system, the HVESS parameters should be used. If there are multiple packs in the ...";
CM_ SG_ 2364716798 LowestCellVCellNum "Identifies the location of SPN 16150 (HVESP17 Lowest Cell Voltage) within SPN 16231 (HVESP17 Lowest Cell Voltage Module Number).
This parameter is for one of multiple packs in an HVESS. If there is only one pack in the system, the HVESS parameters ...";
CM_ SG_ 2364716798 LowestCellVModuleNum "Identifies the location of the module containing SPN 16150 (HVESP17 Lowest Cell Voltage).
This parameter is for one of multiple packs in an HVESS. If there is only one pack in the system, the HVESS parameters should be used. If there are multiple ...";
CM_ SG_ 2364716798 HighestCellVCellNum "Identifies the location of SPN 16149 (HVESP17 Highest Cell Voltage) within SPN 16229 (HVESP17 Highest Cell Voltage Module Number).
This parameter is for one of multiple packs in an HVESS. If there is only one pack in the system, the HVESS ...";
CM_ SG_ 2364716798 HighestCellVModuleNum "Identifies the location of the module containing SPN 16149 (HVESP17 Highest Cell Voltage).
This parameter is for one of multiple packs in an HVESS. If there is only one pack in the system, the HVESS parameters should be used. If there are multiple ...";
CM_ BO_ 2364716542 "High Voltage Energy Storage Pack 17 Thermal Management System Status 1
Collection of data the High Voltage Energy Storage Pack 17 Thermal Management System sends to the Hybrid Controller.";
CM_ SG_ 2364716542 TMSCoolantLvl "Indicates the coolant level in this HVES Thermal Management System (TMS).
This parameter is for one of multiple packs in an HVESS.  If there is only one pack in the system, the HVESS parameters should be used. If there are multiple packs in the ...";
CM_ SG_ 2364716542 TMSMode "Indicates the operating mode of the Thermal Management System.  The heat transfer medium may be (e.g. liquid or air).  The cooling system may be fans, liquid coolant, or a combination of mediums.  The system may include an air and/or liquid ...";
CM_ SG_ 2364716542 TMSHVILStatus "In multiple HVES configurations, this is the status of the High Voltage Interlock Loop from the viewpoint of this Thermal Management System.
00b = HVIL Closed
01b = HVIL Open
10b = Error
11b = Not Available
This parameter is for one of multiple ...";
CM_ SG_ 2364716542 TMSHtrStatus "The state of this High Voltage Energy Storage Pack heater
This parameter is for one of multiple packs in an HVESS.  If there is only one pack in the system, the HVESS parameters should be used. If there are multiple packs in the system, then both ...";
CM_ SG_ 2364716542 TMSRelHumidty "When this High Voltage Energy Storage Pack Thermal Management System is equipped with a relative humidity sensor, this is the  measured Relative Humidity.
This parameter is for one of multiple packs in an HVESS.  If there is only one pack in the ...";
CM_ SG_ 2364716542 TMSCompressorSpd "When this High Voltage Energy Storage Pack Thermal Management System is equipped with an active cooling system (e.g. air conditioner), this is the Compressor Speed.
This parameter is for one of multiple packs in an HVESS.  If there is only one pack ...";
CM_ SG_ 2364716542 TMSHVInputPwr "This is the high-voltage power consumed by this HVES Thermal Management System (TMS).
This parameter is for one of multiple packs in an HVESS.  If there is only one pack in the system, the HVESS parameters should be used. If there are multiple ...";
CM_ SG_ 2364716542 TMSSLIInputPwr "This is the low-voltage power consumed by this HVES Thermal Management System (TMS).
This parameter is for one of multiple packs in an HVESS.  If there is only one pack in the system, the HVESS parameters should be used.  If there are multiple ...";
CM_ BO_ 2364716286 "High Voltage Energy Storage Pack 17 Module Status 1
Module Status message 1 for High Voltage Energy Storage Pack 17.";
CM_ SG_ 2364716286 Module32OperationalStatus "Operational Status of Module 32 in this High Voltage Energy Storage Pack Instance.  Not Operational is used when the module is initializing or not able to function (e.g. internal module level monitors have failed).  Operational indicates that the ...";
CM_ SG_ 2364716286 Module31OperationalStatus "Operational Status of Module 31 in this High Voltage Energy Storage Pack Instance.  Not Operational is used when the module is initializing or not able to function (e.g. internal module level monitors have failed).  Operational indicates that the ...";
CM_ SG_ 2364716286 Module30OperationalStatus "Operational Status of Module 30 in this High Voltage Energy Storage Pack Instance.  Not Operational is used when the module is initializing or not able to function (e.g. internal module level monitors have failed).  Operational indicates that the ...";
CM_ SG_ 2364716286 Module29OperationalStatus "Operational Status of Module 29 in this High Voltage Energy Storage Pack Instance.  Not Operational is used when the module is initializing or not able to function (e.g. internal module level monitors have failed).  Operational indicates that the ...";
CM_ SG_ 2364716286 Module28OperationalStatus "Operational Status of Module 28 in this High Voltage Energy Storage Pack Instance.  Not Operational is used when the module is initializing or not able to function (e.g. internal module level monitors have failed).  Operational indicates that the ...";
CM_ SG_ 2364716286 Module27OperationalStatus "Operational Status of Module 27 in this High Voltage Energy Storage Pack Instance.  Not Operational is used when the module is initializing or not able to function (e.g. internal module level monitors have failed).  Operational indicates that the ...";
CM_ SG_ 2364716286 Module26OperationalStatus "Operational Status of Module 26 in this High Voltage Energy Storage Pack Instance.  Not Operational is used when the module is initializing or not able to function (e.g. internal module level monitors have failed).  Operational indicates that the ...";
CM_ SG_ 2364716286 Module25OperationalStatus "Operational Status of Module 25 in this High Voltage Energy Storage Pack Instance.  Not Operational is used when the module is initializing or not able to function (e.g. internal module level monitors have failed).  Operational indicates that the ...";
CM_ SG_ 2364716286 Module24OperationalStatus "Operational Status of Module 24 in this High Voltage Energy Storage Pack Instance.  Not Operational is used when the module is initializing or not able to function (e.g. internal module level monitors have failed).  Operational indicates that the ...";
CM_ SG_ 2364716286 Module23OperationalStatus "Operational Status of Module 23 in this High Voltage Energy Storage Pack Instance.  Not Operational is used when the module is initializing or not able to function (e.g. internal module level monitors have failed).  Operational indicates that the ...";
CM_ SG_ 2364716286 Module22OperationalStatus "Operational Status of Module 22 in this High Voltage Energy Storage Pack Instance.  Not Operational is used when the module is initializing or not able to function (e.g. internal module level monitors have failed).  Operational indicates that the ...";
CM_ SG_ 2364716286 Module21OperationalStatus "Operational Status of Module 21 in this High Voltage Energy Storage Pack Instance.  Not Operational is used when the module is initializing or not able to function (e.g. internal module level monitors have failed).  Operational indicates that the ...";
CM_ SG_ 2364716286 Module20OperationalStatus "Operational Status of Module 20 in this High Voltage Energy Storage Pack Instance.  Not Operational is used when the module is initializing or not able to function (e.g. internal module level monitors have failed).  Operational indicates that the ...";
CM_ SG_ 2364716286 Module19OperationalStatus "Operational Status of Module 19 in this High Voltage Energy Storage Pack Instance.  Not Operational is used when the module is initializing or not able to function (e.g. internal module level monitors have failed).  Operational indicates that the ...";
CM_ SG_ 2364716286 Module18OperationalStatus "Operational Status of Module 18 in this High Voltage Energy Storage Pack Instance.  Not Operational is used when the module is initializing or not able to function (e.g. internal module level monitors have failed).  Operational indicates that the ...";
CM_ SG_ 2364716286 Module17OperationalStatus "Operational Status of Module 17 in this High Voltage Energy Storage Pack Instance.  Not Operational is used when the module is initializing or not able to function (e.g. internal module level monitors have failed).  Operational indicates that the ...";
CM_ SG_ 2364716286 Module16OperationalStatus "Operational Status of Module 16 in this High Voltage Energy Storage Pack Instance.  Not Operational is used when the module is initializing or not able to function (e.g. internal module level monitors have failed).  Operational indicates that the ...";
CM_ SG_ 2364716286 Module15OperationalStatus "Operational Status of Module 15 in this High Voltage Energy Storage Pack Instance.  Not Operational is used when the module is initializing or not able to function (e.g. internal module level monitors have failed).  Operational indicates that the ...";
CM_ SG_ 2364716286 Module14OperationalStatus "Operational Status of Module 14 in this High Voltage Energy Storage Pack Instance.  Not Operational is used when the module is initializing or not able to function (e.g. internal module level monitors have failed).  Operational indicates that the ...";
CM_ SG_ 2364716286 Module13OperationalStatus "Operational Status of Module 13 in this High Voltage Energy Storage Pack Instance.  Not Operational is used when the module is initializing or not able to function (e.g. internal module level monitors have failed).  Operational indicates that the ...";
CM_ SG_ 2364716286 Module12OperationalStatus "Operational Status of Module 12 in this High Voltage Energy Storage Pack Instance.  Not Operational is used when the module is initializing or not able to function (e.g. internal module level monitors have failed).  Operational indicates that the ...";
CM_ SG_ 2364716286 Module11OperationalStatus "Operational Status of Module 11 in this High Voltage Energy Storage Pack Instance.  Not Operational is used when the module is initializing or not able to function (e.g. internal module level monitors have failed).  Operational indicates that the ...";
CM_ SG_ 2364716286 Module10OperationalStatus "Operational Status of Module 10 in this High Voltage Energy Storage Pack Instance.  Not Operational is used when the module is initializing or not able to function (e.g. internal module level monitors have failed).  Operational indicates that the ...";
CM_ SG_ 2364716286 Module9OperationalStatus "Operational Status of Module 9 in this High Voltage Energy Storage Pack Instance.  Not Operational is used when the module is initializing or not able to function (e.g. internal module level monitors have failed).  Operational indicates that the ...";
CM_ SG_ 2364716286 Module8OperationalStatus "Operational Status of Module 8 in this High Voltage Energy Storage Pack Instance.  Not Operational is used when the module is initializing or not able to function (e.g. internal module level monitors have failed).  Operational indicates that the ...";
CM_ SG_ 2364716286 Module7OperationalStatus "Operational Status of Module 7 in this High Voltage Energy Storage Pack Instance.  Not Operational is used when the module is initializing or not able to function (e.g. internal module level monitors have failed).  Operational indicates that the ...";
CM_ SG_ 2364716286 Module6OperationalStatus "Operational Status of Module 6 in this High Voltage Energy Storage Pack Instance.  Not Operational is used when the module is initializing or not able to function (e.g. internal module level monitors have failed).  Operational indicates that the ...";
CM_ SG_ 2364716286 Module5OperationalStatus "Operational Status of Module 5 in this High Voltage Energy Storage Pack Instance.  Not Operational is used when the module is initializing or not able to function (e.g. internal module level monitors have failed).  Operational indicates that the ...";
CM_ SG_ 2364716286 Module4OperationalStatus "Operational Status of Module 4 in this High Voltage Energy Storage Pack Instance.  Not Operational is used when the module is initializing or not able to function (e.g. internal module level monitors have failed).  Operational indicates that the ...";
CM_ SG_ 2364716286 Module3OperationalStatus "Operational Status of Module 3 in this High Voltage Energy Storage Pack Instance.  Not Operational is used when the module is initializing or not able to function (e.g. internal module level monitors have failed).  Operational indicates that the ...";
CM_ SG_ 2364716286 Module2OperationalStatus "Operational Status of Module 2 in this High Voltage Energy Storage Pack Instance.  Not Operational is used when the module is initializing or not able to function (e.g. internal module level monitors have failed).  Operational indicates that the ...";
CM_ SG_ 2364716286 Module1OperationalStatus "Operational Status of Module 1 in this High Voltage Energy Storage Pack Instance.  Not Operational is used when the module is initializing or not able to function (e.g. internal module level monitors have failed).  Operational indicates that the ...";
CM_ BO_ 2364716030 "High Voltage Energy Storage Pack 17 Data 7
Data set 7 (electrical) for High Voltage Energy Storage Pack 17.";
CM_ SG_ 2364716030 MaxChargeVLmt "The maximum voltage level not to be exceeded while charging this High Voltage Energy Storage Pack instance. If this parameter is not supported, the maximum charge voltage should be limited to SPN 16255 (HVESP17 Recommended Maximum Operating ...";
CM_ SG_ 2364716030 ChargeEnergyCapacity "The amount of unused electrical energy storage available to be filled by charging this High Voltage Energy Storage Pack instance, i.e. “how much empty space is remaining in the tank”. See SPN 16157 (HVESP17 Charge Capacity) for Ampere-hours (Ah).
 ...";
CM_ SG_ 2364716030 DisEnergyCapacity "The amount of stored electrical energy in this High Voltage Energy Storage Pack instance that is available for use by the hybrid system, i.e. “how full is the tank”. See SPN 16156 (HVESP17 Discharge Capacity) for Ampere-hours (Ah).
This parameter ...";
CM_ BO_ 2364715774 "High Voltage Energy Storage Pack 17 Status 1
Status data set 1 for High Voltage Energy Storage Pack 17.";
CM_ SG_ 2364715774 Status1CRC "The CRC is defined as follows:
• Length: 8 bits
• Polynomial: x^8+x^5+x^3+x^2+x+1
• Initial Value: FFh
• Input Data Reflection: Not reflected
• Result Data Reflection: Not reflected
• XOR value: FFh
SAE makes no claim of the functional safety ...";
CM_ SG_ 2364715774 Status1Counter "The message counter is used to detect situations where the transmitting ECU malfunction repeats the same frame all the time. The receiver of the information may use the counter parameter to detect this situation. The transmitting device will ...";
CM_ SG_ 2364715774 OperationalStatus "Provides feedback on where this High Voltage Energy Storage Pack instance is in its operating spectrum, and includes feedback in response to the Operation Consent [i.e. SPN 16127 (HVESP17 Operation Consent)] and Power Down Command [i.e. SPN 16122 ...";
CM_ SG_ 2364715774 HVBusConnectionStatus "This parameter provides high level feedback on this High Voltage Energy Storage Pack instance high voltage bus connection. For specific contactor information, see SPN 16169 (HVESP17 High-Voltage Bus (Positive) Contactor State), SPN 16170 (HVESP17 ...";
CM_ SG_ 2364715774 InternalChargerStatus "Indicates that the charger in this HVES instance is on.  External chargers may use the External Energy Source Connection Status (SPN 7898) and related SPs.
This parameter is for one of multiple packs in an HVESS. If there is only one pack in the ...";
CM_ SG_ 2364715774 CellBalancingActive "Indicates whether or not the cells in this High Voltage Energy Storage Pack instance are currently being balanced.
This parameter is for one of multiple packs in an HVESS.  If there is only one pack in the system, the HVESS parameters should be ...";
CM_ SG_ 2364715774 CellBalanceStatus "Indicates whether or not the cells in this High Voltage Energy Storage Pack instance are balanced.
This parameter is for one of multiple packs in an HVESS.  If there is only one pack in the system, the HVESS parameters should be used. If there are ...";
CM_ SG_ 2364715774 StOfChargeStatus "Status of this High Voltage Energy Storage Pack instance State of Charge (SOC).  Note:  A given HVES controller may not support all of the states.
This parameter is for one of multiple packs in an HVESS.  If there is only one pack in the system, ...";
CM_ SG_ 2364715774 InertiaSwStatus "Switch indicating that an impact has been sensed by this High Voltage Energy Storage Pack instance. The impact indication may require action by another controller, or by this HVES instance itself.  For example, a controller may elect to take this ...";
CM_ SG_ 2364715774 HVILStatus "Status of the High Voltage Interlock Loop from the viewpoint of this High Voltage Energy Storage Pack instance.
This parameter is for one of multiple packs in an HVESS. If there is only one pack in the system, the HVESS parameters should be used ...";
CM_ SG_ 2364715774 HVBusPassiveIsolTestStatus "Status of the high-voltage bus electrical passive isolation test as performed by this High Voltage Energy Storage Pack instance.
This parameter is for one of multiple packs in an HVESS. If there is only one pack in the system, the HVESS parameters ...";
CM_ SG_ 2364715774 HVBusActiveIsolTestStatus "Status of the high-voltage bus electrical active isolation test as performed by this High Voltage Energy Storage Pack instance.
This parameter is for one of multiple packs in an HVESS. If there is only one pack in the system, the HVESS parameters ...";
CM_ SG_ 2364715774 CenterOfPackContactorSt "Position of the center high-voltage contactor. When this contactor is closed, the positive half of this High Voltage Energy Storage Pack instance is connected to the negative half. If a system controls the positive, negative, and center contactors ...";
CM_ SG_ 2364715774 HVBusPreChargeRelaySt "Position of the high-voltage bus contactor pre-charge relay.  When this relay is closed, this High Voltage Energy Storage Pack instance is bringing the high-voltage bus up to its operating level.
This parameter is for one of multiple packs in an ...";
CM_ SG_ 2364715774 HVBusDisconnectForewarning "Indicates that this High Voltage Energy Storage Pack instance is about to disconnect from the high voltage bus due to unacceptable conditions.
This parameter is for one of multiple packs in an HVESS. If there is only one pack in the system, the ...";
CM_ SG_ 2364715774 HVBusContactorSt16170 "Position of this High Voltage Energy Storage Pack instance negative side bus contactor. When this contactor is closed, the negative side of this HVES instance is connected to the negative side of the high-voltage bus. If a system controls the ...";
CM_ SG_ 2364715774 HVBusContactorSt "Position of this High Voltage Energy Storage Pack instance positive side bus contactor.  When this contactor is closed, the positive side of this HVES instance is connected to the positive side of the high-voltage bus.  In systems where all ...";
CM_ BO_ 2364715518 "High Voltage Energy Storage Pack 17 Data 6
Data set 6 (external or interface data) for High Voltage Energy Storage Pack 17.";
CM_ SG_ 2364715518 Temp "The temperature of this High Voltage Energy Storage Pack instance. The value may be determined from a unique sensor specifically for this purpose, or by aggregating various temperature sensor readings within the pack.
This parameter is for one of ...";
CM_ SG_ 2364715518 ETemp "The temperature of the electronics or control modules in this High Voltage Energy Storage Pack instance.  If there are multiple temperature sensors then this parameter would be set to the maximum sensor reading.
This parameter is for one of ...";
CM_ SG_ 2364715518 OutCoolantTemp "The temperature of liquid coolant as it exits this High Voltage Energy Storage Pack instance.
This parameter is for one of multiple packs in an HVESS.  If there is only one pack in the system, the HVESS parameters should be used. If there are ...";
CM_ SG_ 2364715518 InCoolantTemp "The temperature of liquid coolant as it enters this High Voltage Energy Storage Pack instance.
This parameter is for one of multiple packs in an HVESS.  If there is only one pack in the system, the HVESS parameters should be used. If there are ...";
CM_ SG_ 2364715518 IgntV "The voltage level at the ignition input of this High Voltage Energy Storage Pack controller.
This parameter is for one of multiple packs in an HVESS.  If there is only one pack in the system, the HVESS parameters should be used.  If there are ...";
CM_ SG_ 2364715518 BusV "The voltage level of the high voltage bus, as measured by this High Voltage Energy Storage Pack instance on the bus side (not the battery side) of its contactors.
This parameter is for one of multiple packs in an HVESS.  If there is only one pack ...";
CM_ BO_ 2364715262 "High Voltage Energy Storage Pack 17 Data 5
Data set 5 (electrical data) for High Voltage Energy Storage Pack 17.";
CM_ SG_ 2364715262 HighestCellStOfCharge "Indicates the state of charge of the highest-charged cell in this High Voltage Energy Storage Pack instance. 0% means no charge remaining, 100% means the cell is fully charged. If a single state of charge value covers more than one cell, the value ...";
CM_ SG_ 2364715262 LowestCellStOfCharge "Indicates the state of charge of the lowest-charged cell in this High Voltage Energy Storage Pack instance. 0% means no charge remaining, 100% means the cell is fully charged. If a single state of charge value covers more than one cell, the value in ...";
CM_ SG_ 2364715262 ChargeCurLmt "The maximum instantaneous current flow limit into this High Voltage Energy Storage Pack instance. This parameter is defined from the high voltage energy storage pack's point of view and should reflect the instantaneous capability of the pack.  The ...";
CM_ SG_ 2364715262 DisCurLmt "The maximum instantaneous current flow limit out of this High Voltage Energy Storage Pack instance. This parameter is defined from the high voltage energy storage pack's point of view and should reflect the instantaneous capability of the pack.  The ...";
CM_ BO_ 2364715006 "High Voltage Energy Storage Pack 17 Data 4
Data set 4 (electrical data) for High Voltage Energy Storage Pack 17.";
CM_ SG_ 2364715006 CellBalancingCount "The number of cells that are currently being balanced in this High Voltage Energy Storage Pack instance.
This parameter is for one of multiple packs in an HVESS.  If there is only one pack in the system, the HVESS parameters should be used.  If ...";
CM_ SG_ 2364715006 ChargeCapacity "The amount of unused electrical charge storage in this High Voltage Energy Storage Pack instance that is available to be filled by charging, i.e. “how much empty space is remaining in the tank”. See SPN 16187 (HVESP17 Charge Energy Capacity) for ...";
CM_ SG_ 2364715006 DisCapacity "The amount of stored electrical charge in this High Voltage Energy Storage Pack instance that is available for use by the hybrid system, i.e. “how full is the tank”. See SPN 16186 (HVESP17 Discharge Energy Capacity) for kilowatt-hours (kWh).
This ...";
CM_ BO_ 2364714750 "High Voltage Energy Storage Pack 17 Data 3
Data set 3 (thermal data) for High Voltage Energy Storage Pack 17.";
CM_ SG_ 2364714750 CellTempDiffStatus "Indicates whether or not the differential between the highest and lowest cell temperatures are within acceptable limits per this High Voltage Energy Storage Pack instance. The actual temperature differential can be calculated by subtracting SPN ...";
CM_ SG_ 2364714750 AvgCellTemp "The average temperature level of all cells in this High Voltage Energy Storage Pack instance.
This parameter is for one of multiple packs in an HVESS.  If there is only one pack in the system, the HVESS parameters should be used.  If there are ...";
CM_ SG_ 2364714750 LowestCellTemp "The lowest temperature level reported by any cell in this High Voltage Energy Storage Pack instance. If a single temperature sensor covers more than one cell, the value in this parameter is for the smallest group of cells measured. See SPN 16236 ...";
CM_ SG_ 2364714750 HighestCellTemp "The highest temperature level reported by any cell in this High Voltage Energy Storage Pack instance. If a single temperature sensor covers more than one cell, the value in this parameter is for the smallest group of cells measured. See SPN 16234 ...";
CM_ BO_ 2364714494 "High Voltage Energy Storage Pack 17 Data 2
Data set 2 (electrical data) for High Voltage Energy Storage Pack 17.";
CM_ SG_ 2364714494 CellVDiffStatus "Indicates whether or not the differential between the highest and lowest cell voltages are within acceptable limits, according to this High Voltage Energy Storage Pack instance. The actual voltage differential can be calculated by subtracting SPN ...";
CM_ SG_ 2364714494 LowestCellV "The lowest voltage level reported by any cell in this High Voltage Energy Storage Pack instance. If a single voltage sensor covers more than one cell, the value in this parameter is for the smallest group of cells measured. See SPN 16231 (HVESP17 ...";
CM_ SG_ 2364714494 HighestCellV "The highest voltage level reported by any cell in this High Voltage Energy Storage Pack instance. If a single voltage sensor covers more than one cell, the value in this parameter is for the smallest group of cells measured. See SPN 16229 (HVESP17 ...";
CM_ SG_ 2364714494 FastUpdateStOfCharge "Indicates this High Voltage Energy Storage Pack instance state of charge. 0% means no charge remaining, 100% means the system is fully charged in terms of physical limits of this energy storage pack instance. Acceptable state of charge upper and ...";
CM_ BO_ 2364714238 "High Voltage Energy Storage Pack 17 Data 1
Data set 1 (electrical data) for High Voltage Energy Storage Pack 17.";
CM_ SG_ 2364714238 Cur "The current in or out of this High Voltage Energy Storage Pack instance. This parameter should be synchronized with SPN 16146 (HVESP17 Voltage Level) such that a realized power value can be calculated. This parameter is defined from the high voltage ...";
CM_ SG_ 2364714238 Lvl "The voltage level of this High Voltage Energy Storage Pack instance. This parameter should be synchronized with SPN 16147 (HVESP17 Current) such that a realized power value can be calculated. If the HVES component physically contains the contactors ...";
CM_ SG_ 2364714238 AvailableChargePwr "The rate at which this High Voltage Energy Storage Pack instance can currently receive energy from a regenerative or recharging system.
This parameter is for one of multiple packs in an HVESS.  If there is only one pack in the system, the HVESS ...";
CM_ SG_ 2364714238 AvailableDisPwr "The rate at which this High Voltage Energy Storage Pack instance can currently provide energy for propulsion or other uses.
This parameter is for one of multiple packs in an HVESS.  If there is only one pack in the system, the HVESS parameters ...";
CM_ BO_ 2364713982 "High Voltage Energy Storage Pack 17 Status 2
Status data set 2 for High Voltage Energy Storage Pack 17.";
CM_ SG_ 2364713982 ChargePLDueToAnUndefinedCause "Indicates whether or not charge power of this HVES instance is being limited due to an undefined cause.
This parameter is for one of multiple packs in an HVESS.  If there is only one pack in the system, the HVESS parameters should be used. If there ...";
CM_ SG_ 2364713982 ChargePLDueToBatCur "Indicates whether or not charge power of this HVES instance is being limited due to battery current.
This parameter is for one of multiple packs in an HVESS.  If there is only one pack in the system, the HVESS parameters should be used. If there ...";
CM_ SG_ 2364713982 ChargePLDueToBatOrCellV "Indicates whether or not charge power of this HVES instance is being limited due to a battery or cell voltage level.
This parameter is for one of multiple packs in an HVESS.  If there is only one pack in the system, the HVESS parameters should be ...";
CM_ SG_ 2364713982 ChargePLDueToBatDiagCondition "Indicates whether or not charge power of this HVES instance is being limited due to a battery diagnostic condition.
This parameter is for one of multiple packs in an HVESS.  If there is only one pack in the system, the HVESS parameters should be ...";
CM_ SG_ 2364713982 ChargePLDueToBatTemp "Indicates whether or not charge power of this HVES instance is being limited due to battery temperature.
This parameter is for one of multiple packs in an HVESS.  If there is only one pack in the system, the HVESS parameters should be used. If ...";
CM_ SG_ 2364713982 ChargePLDueToStOfCharge "Indicates whether or not charge power of this HVES instance is being limited due to state of charge.
This parameter is for one of multiple packs in an HVESS.  If there is only one pack in the system, the HVESS parameters should be used. If there ...";
CM_ SG_ 2364713982 DisPLDueToAnUndefinedCause "Indicates whether or not discharge power of this HVES instance is being limited due to an undefined cause.
This parameter is for one of multiple packs in an HVESS.  If there is only one pack in the system, the HVESS parameters should be used. If ...";
CM_ SG_ 2364713982 DisPLDueToBatCur "Indicates whether or not discharge power of this HVES instance is being limited due to battery current.
This parameter is for one of multiple packs in an HVESS.  If there is only one pack in the system, the HVESS parameters should be used. If there ...";
CM_ SG_ 2364713982 DisPLDueToBatOrCellV "Indicates whether or not discharge power of this HVES instance is being limited due to a battery or cell voltage level.
This parameter is for one of multiple packs in an HVESS.  If there is only one pack in the system, the HVESS parameters should ...";
CM_ SG_ 2364713982 DisPLDueToBatDiagCondition "Indicates whether or not discharge power of this HVES instance is being limited due to a battery diagnostic condition.
This parameter is for one of multiple packs in an HVESS.  If there is only one pack in the system, the HVESS parameters should be ...";
CM_ SG_ 2364713982 DisPLDueToBatTemp "Indicates whether or not discharge power of this HVES instance is being limited due to battery temperature.
This parameter is for one of multiple packs in an HVESS.  If there is only one pack in the system, the HVESS parameters should be used. If ...";
CM_ SG_ 2364713982 DisPLDueToStOfCharge "Indicates whether or not discharge power of this HVES instance is being limited due to state of charge.
This parameter is for one of multiple packs in an HVESS.  If there is only one pack in the system, the HVESS parameters should be used. If there ...";
CM_ BO_ 2364713726 "High Voltage Energy Storage Pack 16 Data 11
Data set 11 (electrical data) for High Voltage Energy Storage Pack 16.";
CM_ SG_ 2364713726 ActualChargeRate "This signal represents the actual present charge rate of this High Voltage Energy Storage Pack instance.
This parameter is for one of multiple packs in an HVESS. If there is only one pack in the system, the HVESS parameters should be used. If there ...";
CM_ SG_ 2364713726 LvlNegToChassisGroundV "Voltage difference between the most negative terminal of the HVES battery and chassis measured at the battery side of any HVES contained output contactor.  This voltage may be used for system level monitoring of battery shorts to chassis within the ...";
CM_ SG_ 2364713726 BusVNegToChassisGroundV "Voltage difference between the most negative terminal of the HVES battery and chassis measured on the hybrid system bus side (not the battery side) of any HVES contained output contactor.  This voltage may be used for system level monitoring of ...";
CM_ BO_ 2364713470 "High Voltage Energy Storage Pack 16 Data 10
Data set 10 (electrical) for High Voltage Energy Storage Pack 16.";
CM_ SG_ 2364713470 HVBusPassiveIsolTestResults "The isolation resistance expressed in Ohms per Volt that resulted from the High-Voltage Bus Passive Isolation Test.
See SPN 16033 (HVESP16 High-Voltage Bus Passive Isolation Test Status) for test status and SPN 15982 (HVESP16 High-Voltage Bus ...";
CM_ SG_ 2364713470 HVBusActiveIsolTestResults "The isolation resistance expressed in Ohms per Volt that resulted from the High-Voltage Bus Active Isolation Test.
See SPN 16032 (HVESP16 High-Voltage Bus Active Isolation Test Status) for test status and SPN 15981 (HVESP16 High-Voltage Bus Active ...";
CM_ SG_ 2364713470 LowestCellStOfChargeCellNum "Identifies the location of SPN 16019 (HVESP16 Lowest Cell State of Charge) within SPN 16098 (HVESP16 Lowest Cell State of Charge Module Number).
This parameter is for one of multiple packs in an HVESS. If there is only one pack in the system, the ...";
CM_ SG_ 2364713470 LowestCellStOfChargeModuleNum "Identifies the location of the module containing SPN 16019 (HVESP16 Lowest Cell State of Charge).
This parameter is for one of multiple packs in an HVESS. If there is only one pack in the system, the HVESS parameters should be used. If there are ...";
CM_ SG_ 2364713470 HighestCellStOfChargeCellNum "Identifies the location of SPN 16020 (HVESP16 Highest Cell State of Charge) within SPN 16096 (HVESP16 Highest Cell State of Charge Module Number).
This parameter is for one of multiple packs in an HVESS. If there is only one pack in the system, the ...";
CM_ SG_ 2364713470 HighestCellStOfChargeModuleNum "Identifies the location of the module containing SPN 16020 (HVESP16 Highest Cell State of Charge).
This parameter is for one of multiple packs in an HVESS. If there is only one pack in the system, the HVESS parameters should be used. If there are ...";
CM_ BO_ 2364713214 "High Voltage Energy Storage Pack 16 Data 9
Data set 9 (thermal) for High Voltage Energy Storage Pack 16.";
CM_ SG_ 2364713214 Data9CRC "The CRC is defined as follows:
• Length: 8 bits
• Polynomial: x^8+x^5+x^3+x^2+x+1
• Initial Value: FFh
• Input Data Reflection: Not reflected
• Result Data Reflection: Not reflected
• XOR value: FFh
SAE makes no claim of the functional safety ...";
CM_ SG_ 2364713214 Data9Counter "The message counter is used to detect situations where the transmitting ECU malfunction repeats the same frame all the time. The receiver of the information may use the counter parameter to detect this situation. The transmitting device will ...";
CM_ SG_ 2364713214 Data9EmbeddedIntegritySupport "Indicates SPN 23021 (HVESP16 Data 9 CRC) and SPN 23020 (HVESP16 Data 9 Counter) are supported by the sender.
00b = Embedded CRC and Counter are supported by the sender
01b = Protection is supported using J1939-76 SHM
10b = Reserved
11b = CRC and ...";
CM_ SG_ 2364713214 HVESS16ThermalEventDetected "A sensor has detected the presence of a thermal event at or near High Voltage Energy Storage Pack instance.
00b = No Thermal Event Detected
01b = Thermal Event Detected
10b = Error
11b = Not available
This parameter is for one of multiple packs ...";
CM_ SG_ 2364713214 LowestCellTempCellNum "Identifies the location of SPN 16011 (HVESP16 Lowest Cell Temperature) within SPN 16094 (HVESP16 Lowest Cell Temperature Module Number).
This parameter is for one of multiple packs in an HVESS. If there is only one pack in the system, the HVESS ...";
CM_ SG_ 2364713214 LowestCellTempModuleNum "Identifies the location of the module containing SPN 16011 (HVESP16 Lowest Cell Temperature).
This parameter is for one of multiple packs in an HVESS. If there is only one pack in the system, the HVESS parameters should be used. If there are ...";
CM_ SG_ 2364713214 HighestCellTempCellNum "Identifies the location of SPN 16010 (HVESP16 Highest Cell Temperature) within SPN 16092 (HVESP16 Highest Cell Temperature Module Number).
This parameter is for one of multiple packs in an HVESS. If there is only one pack in the system, the HVESS ...";
CM_ SG_ 2364713214 HighestCellTempModuleNum "Identifies the location of the module containing SPN 16010 (HVESP16 Highest Cell Temperature).
This parameter is for one of multiple packs in an HVESS. If there is only one pack in the system, the HVESS parameters should be used. If there are ...";
CM_ BO_ 2364712958 "High Voltage Energy Storage Pack 16 Data 8
Data set 8 (electrical data) for High Voltage Energy Storage Pack 16.";
CM_ SG_ 2364712958 AvgCellV "The average cell voltage in this High Voltage Energy Storage Pack instance.
This parameter is for one of multiple packs in an HVESS.  If there is only one pack in the system, the HVESS parameters should be used. If there are multiple packs in the ...";
CM_ SG_ 2364712958 LowestCellVCellNum "Identifies the location of SPN 16008 (HVESP16 Lowest Cell Voltage) within SPN 16089 (HVESP16 Lowest Cell Voltage Module Number).
This parameter is for one of multiple packs in an HVESS. If there is only one pack in the system, the HVESS parameters ...";
CM_ SG_ 2364712958 LowestCellVModuleNum "Identifies the location of the module containing SPN 16008 (HVESP16 Lowest Cell Voltage).
This parameter is for one of multiple packs in an HVESS. If there is only one pack in the system, the HVESS parameters should be used. If there are multiple ...";
CM_ SG_ 2364712958 HighestCellVCellNum "Identifies the location of SPN 16007 (HVESP16 Highest Cell Voltage) within SPN 16087 (HVESP16 Highest Cell Voltage Module Number).
This parameter is for one of multiple packs in an HVESS. If there is only one pack in the system, the HVESS ...";
CM_ SG_ 2364712958 HighestCellVModuleNum "Identifies the location of the module containing SPN 16007 (HVESP16 Highest Cell Voltage).
This parameter is for one of multiple packs in an HVESS. If there is only one pack in the system, the HVESS parameters should be used. If there are multiple ...";
CM_ BO_ 2364712702 "High Voltage Energy Storage Pack 16 Thermal Management System Status 1
Collection of data the High Voltage Energy Storage Pack 16 Thermal Management System sends to the Hybrid Controller.";
CM_ SG_ 2364712702 TMSCoolantLvl "Indicates the coolant level in this HVES Thermal Management System (TMS).
This parameter is for one of multiple packs in an HVESS.  If there is only one pack in the system, the HVESS parameters should be used. If there are multiple packs in the ...";
CM_ SG_ 2364712702 TMSMode "Indicates the operating mode of the Thermal Management System.  The heat transfer medium may be (e.g. liquid or air).  The cooling system may be fans, liquid coolant, or a combination of mediums.  The system may include an air and/or liquid ...";
CM_ SG_ 2364712702 TMSHVILStatus "In multiple HVES configurations, this is the status of the High Voltage Interlock Loop from the viewpoint of this Thermal Management System.
00b = HVIL Closed
01b = HVIL Open
10b = Error
11b = Not Available
This parameter is for one of multiple ...";
CM_ SG_ 2364712702 TMSHtrStatus "The state of this High Voltage Energy Storage Pack heater
This parameter is for one of multiple packs in an HVESS.  If there is only one pack in the system, the HVESS parameters should be used. If there are multiple packs in the system, then both ...";
CM_ SG_ 2364712702 TMSRelHumidty "When this High Voltage Energy Storage Pack Thermal Management System is equipped with a relative humidity sensor, this is the  measured Relative Humidity.
This parameter is for one of multiple packs in an HVESS.  If there is only one pack in the ...";
CM_ SG_ 2364712702 TMSCompressorSpd "When this High Voltage Energy Storage Pack Thermal Management System is equipped with an active cooling system (e.g. air conditioner), this is the Compressor Speed.
This parameter is for one of multiple packs in an HVESS.  If there is only one pack ...";
CM_ SG_ 2364712702 TMSHVInputPwr "This is the high-voltage power consumed by this HVES Thermal Management System (TMS).
This parameter is for one of multiple packs in an HVESS.  If there is only one pack in the system, the HVESS parameters should be used. If there are multiple ...";
CM_ SG_ 2364712702 TMSSLIInputPwr "This is the low-voltage power consumed by this HVES Thermal Management System (TMS).
This parameter is for one of multiple packs in an HVESS.  If there is only one pack in the system, the HVESS parameters should be used.  If there are multiple ...";
BA_DEF_ SG_  "GenSigInactiveValue" INT 0 0;
BA_DEF_ SG_  "SigType" ENUM  "Default","Range","RangeSigned","ASCII","Discrete","Control","ReferencePGN","DTC","StringDelimiter","StringLength","StringLengthControl","MessageCounter","MessageChecksum";
BA_DEF_ SG_  "GenSigStartValue" INT 0 2147483647;
BA_DEF_ SG_  "GenSigSendType" ENUM  "Cyclic","OnWrite","OnWriteWithRepetition","OnChange","OnChangeWithRepetition","IfActive","IfActiveWithRepetition","NoSigSendType";
BA_DEF_ SG_  "GenSigILSupport" ENUM  "No","Yes";
BA_DEF_ SG_  "SPN" INT 0 524287;
BA_DEF_ BO_  "J1939CPgSendTimeout" INT -1 3600000;
BA_DEF_ BO_  "J1939CPgTOS" INT 0 7;
BA_DEF_ BO_  "J1939PgAppearanceOnBus" ENUM  "Default","CAN_Extended","CANFD_Extended";
BA_DEF_ BO_  "FsJ1939UseCrcAndCounter" STRING ;
BA_DEF_ BO_  "TpJ1939VarDlc" ENUM  "No","Yes";
BA_DEF_ BO_  "GenMsgNrOfRepetition" INT 0 1000000;
BA_DEF_ BO_  "GenMsgCycleTimeFast" INT 0 3600000;
BA_DEF_ BO_  "GenMsgFastOnStart" INT 0 100000;
BA_DEF_ BO_  "GenMsgStartDelayTime" INT 0 100000;
BA_DEF_ BO_  "GenMsgILSupport" ENUM  "No","Yes";
BA_DEF_ BO_  "GenMsgDelayTime" INT 0 1000;
BA_DEF_ BO_  "GenMsgRequestable" INT 0 1;
BA_DEF_ BO_  "GenMsgSendType" ENUM  "cyclic","NotUsed","NotUsed","NotUsed","NotUsed","NotUsed","NotUsed","IfActive","noMsgSendType";
BA_DEF_ BO_  "VFrameFormat" ENUM  "StandardCAN","ExtendedCAN","reserved","J1939PG","reserved","reserved","reserved","reserved","reserved","reserved","reserved","reserved","reserved","reserved","StandardCAN_FD","ExtendedCAN_FD";
BA_DEF_ BO_  "SingleFrame" INT 0 1;
BA_DEF_ BO_  "GenMsgCycleTime" INT 0 3600000;
BA_DEF_ SG_  "SystemSignalLongSymbol" STRING ;
BA_DEF_DEF_  "GenSigInactiveValue" 0;
BA_DEF_DEF_  "SigType" "Default";
BA_DEF_DEF_  "GenSigStartValue" 0;
BA_DEF_DEF_  "GenSigSendType" "NoSigSendType";
BA_DEF_DEF_  "GenSigILSupport" "Yes";
BA_DEF_DEF_  "SPN" 0;
BA_DEF_DEF_  "J1939CPgSendTimeout" -1;
BA_DEF_DEF_  "J1939CPgTOS" 2;
BA_DEF_DEF_  "J1939PgAppearanceOnBus" "Default";
BA_DEF_DEF_  "FsJ1939UseCrcAndCounter" "";
BA_DEF_DEF_  "TpJ1939VarDlc" "No";
BA_DEF_DEF_  "GenMsgNrOfRepetition" 0;
BA_DEF_DEF_  "GenMsgCycleTimeFast" 0;
BA_DEF_DEF_  "GenMsgFastOnStart" 0;
BA_DEF_DEF_  "GenMsgStartDelayTime" 0;
BA_DEF_DEF_  "GenMsgILSupport" "Yes";
BA_DEF_DEF_  "GenMsgDelayTime" 0;
BA_DEF_DEF_  "GenMsgRequestable" 1;
BA_DEF_DEF_  "GenMsgSendType" "noMsgSendType";
BA_DEF_DEF_  "VFrameFormat" "J1939PG";
BA_DEF_DEF_  "SingleFrame" 1;
BA_DEF_DEF_  "GenMsgCycleTime" 0;
BA_DEF_DEF_  "SystemSignalLongSymbol" "";
BA_ "FsJ1939UseCrcAndCounter" BO_ 2364723454 "Aa";
BA_ "GenMsgDelayTime" BO_ 2364723454 20;
BA_ "GenMsgSendType" BO_ 2364723454 0;
BA_ "GenMsgCycleTime" BO_ 2364723454 100;
BA_ "GenMsgSendType" BO_ 2364723198 0;
BA_ "GenMsgCycleTime" BO_ 2364723198 100;
BA_ "GenMsgSendType" BO_ 2364722942 0;
BA_ "GenMsgCycleTime" BO_ 2364722942 20;
BA_ "GenMsgSendType" BO_ 2364722686 0;
BA_ "GenMsgCycleTime" BO_ 2364722686 100;
BA_ "GenMsgSendType" BO_ 2364722430 0;
BA_ "GenMsgCycleTime" BO_ 2364722430 20;
BA_ "GenMsgSendType" BO_ 2364722174 0;
BA_ "GenMsgCycleTime" BO_ 2364722174 20;
BA_ "GenMsgSendType" BO_ 2364721918 0;
BA_ "GenMsgCycleTime" BO_ 2364721918 20;
BA_ "GenMsgSendType" BO_ 2364721662 0;
BA_ "GenMsgCycleTime" BO_ 2364721662 100;
BA_ "GenMsgSendType" BO_ 2364721406 0;
BA_ "GenMsgCycleTime" BO_ 2364721406 100;
BA_ "GenMsgSendType" BO_ 2364721150 0;
BA_ "GenMsgCycleTime" BO_ 2364721150 100;
BA_ "FsJ1939UseCrcAndCounter" BO_ 2364720894 "Aa";
BA_ "GenMsgSendType" BO_ 2364720894 0;
BA_ "GenMsgCycleTime" BO_ 2364720894 100;
BA_ "GenMsgSendType" BO_ 2364720638 0;
BA_ "GenMsgCycleTime" BO_ 2364720638 100;
BA_ "GenMsgSendType" BO_ 2364720382 0;
BA_ "GenMsgCycleTime" BO_ 2364720382 100;
BA_ "GenMsgSendType" BO_ 2364720126 0;
BA_ "GenMsgCycleTime" BO_ 2364720126 100;
BA_ "GenMsgSendType" BO_ 2364719870 0;
BA_ "GenMsgCycleTime" BO_ 2364719870 100;
BA_ "FsJ1939UseCrcAndCounter" BO_ 2364719614 "Aa";
BA_ "GenMsgDelayTime" BO_ 2364719614 20;
BA_ "GenMsgSendType" BO_ 2364719614 0;
BA_ "GenMsgCycleTime" BO_ 2364719614 100;
BA_ "GenMsgSendType" BO_ 2364719358 0;
BA_ "GenMsgCycleTime" BO_ 2364719358 100;
BA_ "GenMsgSendType" BO_ 2364719102 0;
BA_ "GenMsgCycleTime" BO_ 2364719102 20;
BA_ "GenMsgSendType" BO_ 2364718846 0;
BA_ "GenMsgCycleTime" BO_ 2364718846 100;
BA_ "GenMsgSendType" BO_ 2364718590 0;
BA_ "GenMsgCycleTime" BO_ 2364718590 20;
BA_ "GenMsgSendType" BO_ 2364718334 0;
BA_ "GenMsgCycleTime" BO_ 2364718334 20;
BA_ "GenMsgSendType" BO_ 2364718078 0;
BA_ "GenMsgCycleTime" BO_ 2364718078 20;
BA_ "GenMsgSendType" BO_ 2364717822 0;
BA_ "GenMsgCycleTime" BO_ 2364717822 100;
BA_ "GenMsgSendType" BO_ 2364717566 0;
BA_ "GenMsgCycleTime" BO_ 2364717566 100;
BA_ "GenMsgSendType" BO_ 2364717310 0;
BA_ "GenMsgCycleTime" BO_ 2364717310 100;
BA_ "FsJ1939UseCrcAndCounter" BO_ 2364717054 "Aa";
BA_ "GenMsgSendType" BO_ 2364717054 0;
BA_ "GenMsgCycleTime" BO_ 2364717054 100;
BA_ "GenMsgSendType" BO_ 2364716798 0;
BA_ "GenMsgCycleTime" BO_ 2364716798 100;
BA_ "GenMsgSendType" BO_ 2364716542 0;
BA_ "GenMsgCycleTime" BO_ 2364716542 100;
BA_ "GenMsgSendType" BO_ 2364716286 0;
BA_ "GenMsgCycleTime" BO_ 2364716286 100;
BA_ "GenMsgSendType" BO_ 2364716030 0;
BA_ "GenMsgCycleTime" BO_ 2364716030 100;
BA_ "FsJ1939UseCrcAndCounter" BO_ 2364715774 "Aa";
BA_ "GenMsgDelayTime" BO_ 2364715774 20;
BA_ "GenMsgSendType" BO_ 2364715774 0;
BA_ "GenMsgCycleTime" BO_ 2364715774 100;
BA_ "GenMsgSendType" BO_ 2364715518 0;
BA_ "GenMsgCycleTime" BO_ 2364715518 100;
BA_ "GenMsgSendType" BO_ 2364715262 0;
BA_ "GenMsgCycleTime" BO_ 2364715262 20;
BA_ "GenMsgSendType" BO_ 2364715006 0;
BA_ "GenMsgCycleTime" BO_ 2364715006 100;
BA_ "GenMsgSendType" BO_ 2364714750 0;
BA_ "GenMsgCycleTime" BO_ 2364714750 20;
BA_ "GenMsgSendType" BO_ 2364714494 0;
BA_ "GenMsgCycleTime" BO_ 2364714494 20;
BA_ "GenMsgSendType" BO_ 2364714238 0;
BA_ "GenMsgCycleTime" BO_ 2364714238 20;
BA_ "GenMsgSendType" BO_ 2364713982 0;
BA_ "GenMsgCycleTime" BO_ 2364713982 100;
BA_ "GenMsgSendType" BO_ 2364713726 0;
BA_ "GenMsgCycleTime" BO_ 2364713726 100;
BA_ "GenMsgSendType" BO_ 2364713470 0;
BA_ "GenMsgCycleTime" BO_ 2364713470 100;
BA_ "FsJ1939UseCrcAndCounter" BO_ 2364713214 "Aa";
BA_ "GenMsgSendType" BO_ 2364713214 0;
BA_ "GenMsgCycleTime" BO_ 2364713214 100;
BA_ "GenMsgSendType" BO_ 2364712958 0;
BA_ "GenMsgCycleTime" BO_ 2364712958 100;
BA_ "GenMsgSendType" BO_ 2364712702 0;
BA_ "GenMsgCycleTime" BO_ 2364712702 100;
BA_ "SigType" SG_ 2364723454 Status1CRC 12;
BA_ "SPN" SG_ 2364723454 Status1CRC 16469;
BA_ "SigType" SG_ 2364723454 Status1Counter 11;
BA_ "SPN" SG_ 2364723454 Status1Counter 16468;
BA_ "SPN" SG_ 2364723454 OperationalStatus 16467;
BA_ "SPN" SG_ 2364723454 HVBusConnectionStatus 16466;
BA_ "SigType" SG_ 2364723454 InternalChargerStatus 5;
BA_ "SPN" SG_ 2364723454 InternalChargerStatus 16465;
BA_ "SigType" SG_ 2364723454 CellBalancingActive 4;
BA_ "SPN" SG_ 2364723454 CellBalancingActive 16464;
BA_ "SigType" SG_ 2364723454 CellBalanceStatus 4;
BA_ "SPN" SG_ 2364723454 CellBalanceStatus 16463;
BA_ "SPN" SG_ 2364723454 StOfChargeStatus 16462;
BA_ "SigType" SG_ 2364723454 InertiaSwStatus 4;
BA_ "SPN" SG_ 2364723454 InertiaSwStatus 16461;
BA_ "SigType" SG_ 2364723454 HVILStatus 4;
BA_ "SPN" SG_ 2364723454 HVILStatus 16460;
BA_ "SPN" SG_ 2364723454 HVBusPassiveIsolTestStatus 16459;
BA_ "SPN" SG_ 2364723454 HVBusActiveIsolTestStatus 16458;
BA_ "SigType" SG_ 2364723454 CenterOfPackContactorSt 4;
BA_ "SPN" SG_ 2364723454 CenterOfPackContactorSt 16457;
BA_ "SigType" SG_ 2364723454 HVBusPreChargeRelaySt 4;
BA_ "SPN" SG_ 2364723454 HVBusPreChargeRelaySt 16456;
BA_ "SPN" SG_ 2364723454 HVBusDisconnectForewarning 16455;
BA_ "SigType" SG_ 2364723454 HVBusContactorSt16454 4;
BA_ "SPN" SG_ 2364723454 HVBusContactorSt16454 16454;
BA_ "SigType" SG_ 2364723454 HVBusContactorSt 4;
BA_ "SPN" SG_ 2364723454 HVBusContactorSt 16453;
BA_ "SigType" SG_ 2364723198 Temp 1;
BA_ "SPN" SG_ 2364723198 Temp 16452;
BA_ "SigType" SG_ 2364723198 ETemp 1;
BA_ "SPN" SG_ 2364723198 ETemp 16451;
BA_ "SigType" SG_ 2364723198 OutCoolantTemp 1;
BA_ "SPN" SG_ 2364723198 OutCoolantTemp 16450;
BA_ "SigType" SG_ 2364723198 InCoolantTemp 1;
BA_ "SPN" SG_ 2364723198 InCoolantTemp 16449;
BA_ "SigType" SG_ 2364723198 IgntV 1;
BA_ "SPN" SG_ 2364723198 IgntV 16448;
BA_ "SigType" SG_ 2364723198 BusV 1;
BA_ "SPN" SG_ 2364723198 BusV 16447;
BA_ "SigType" SG_ 2364722942 HighestCellStOfCharge 1;
BA_ "SPN" SG_ 2364722942 HighestCellStOfCharge 16446;
BA_ "SigType" SG_ 2364722942 LowestCellStOfCharge 1;
BA_ "SPN" SG_ 2364722942 LowestCellStOfCharge 16445;
BA_ "SigType" SG_ 2364722942 ChargeCurLmt 1;
BA_ "GenSigStartValue" SG_ 2364722942 ChargeCurLmt 32000;
BA_ "SPN" SG_ 2364722942 ChargeCurLmt 16444;
BA_ "SigType" SG_ 2364722942 DisCurLmt 1;
BA_ "SPN" SG_ 2364722942 DisCurLmt 16443;
BA_ "SigType" SG_ 2364722686 CellBalancingCount 1;
BA_ "SPN" SG_ 2364722686 CellBalancingCount 16442;
BA_ "SigType" SG_ 2364722686 ChargeCapacity 1;
BA_ "SPN" SG_ 2364722686 ChargeCapacity 16441;
BA_ "SigType" SG_ 2364722686 DisCapacity 1;
BA_ "SPN" SG_ 2364722686 DisCapacity 16440;
BA_ "SigType" SG_ 2364722430 CellTempDiffStatus 4;
BA_ "SPN" SG_ 2364722430 CellTempDiffStatus 16439;
BA_ "SigType" SG_ 2364722430 AvgCellTemp 1;
BA_ "SPN" SG_ 2364722430 AvgCellTemp 16438;
BA_ "SigType" SG_ 2364722430 LowestCellTemp 1;
BA_ "SPN" SG_ 2364722430 LowestCellTemp 16437;
BA_ "SigType" SG_ 2364722430 HighestCellTemp 1;
BA_ "SPN" SG_ 2364722430 HighestCellTemp 16436;
BA_ "SPN" SG_ 2364722174 CellVDiffStatus 16435;
BA_ "SigType" SG_ 2364722174 LowestCellV 1;
BA_ "SPN" SG_ 2364722174 LowestCellV 16434;
BA_ "SigType" SG_ 2364722174 HighestCellV 1;
BA_ "SPN" SG_ 2364722174 HighestCellV 16433;
BA_ "SigType" SG_ 2364722174 FastUpdateStOfCharge 1;
BA_ "SPN" SG_ 2364722174 FastUpdateStOfCharge 16432;
BA_ "SigType" SG_ 2364721918 Cur 1;
BA_ "SPN" SG_ 2364721918 Cur 16431;
BA_ "SigType" SG_ 2364721918 Lvl 1;
BA_ "SPN" SG_ 2364721918 Lvl 16430;
BA_ "SigType" SG_ 2364721918 AvailableChargePwr 1;
BA_ "SPN" SG_ 2364721918 AvailableChargePwr 16429;
BA_ "SigType" SG_ 2364721918 AvailableDisPwr 1;
BA_ "SPN" SG_ 2364721918 AvailableDisPwr 16428;
BA_ "SigType" SG_ 2364721662 ChargePLDueToAnUndefinedCause 4;
BA_ "SPN" SG_ 2364721662 ChargePLDueToAnUndefinedCause 16427;
BA_ "SigType" SG_ 2364721662 ChargePLDueToBatCur 4;
BA_ "SPN" SG_ 2364721662 ChargePLDueToBatCur 16426;
BA_ "SigType" SG_ 2364721662 ChargePLDueToBatOrCellV 4;
BA_ "SPN" SG_ 2364721662 ChargePLDueToBatOrCellV 16425;
BA_ "SigType" SG_ 2364721662 ChargePLDueToBatDiagCondition 4;
BA_ "SPN" SG_ 2364721662 ChargePLDueToBatDiagCondition 16424;
BA_ "SigType" SG_ 2364721662 ChargePLDueToBatTemp 4;
BA_ "SPN" SG_ 2364721662 ChargePLDueToBatTemp 16423;
BA_ "SigType" SG_ 2364721662 ChargePLDueToStOfCharge 4;
BA_ "SPN" SG_ 2364721662 ChargePLDueToStOfCharge 16422;
BA_ "SigType" SG_ 2364721662 DisPLDueToAnUndefinedCause 4;
BA_ "SPN" SG_ 2364721662 DisPLDueToAnUndefinedCause 16421;
BA_ "SigType" SG_ 2364721662 DisPLDueToBatCur 4;
BA_ "SPN" SG_ 2364721662 DisPLDueToBatCur 16420;
BA_ "SigType" SG_ 2364721662 DisPLDueToBatOrCellV 4;
BA_ "SPN" SG_ 2364721662 DisPLDueToBatOrCellV 16419;
BA_ "SigType" SG_ 2364721662 DisPLDueToBatDiagCondition 4;
BA_ "SPN" SG_ 2364721662 DisPLDueToBatDiagCondition 16418;
BA_ "SigType" SG_ 2364721662 DisPLDueToBatTemp 4;
BA_ "SPN" SG_ 2364721662 DisPLDueToBatTemp 16417;
BA_ "SigType" SG_ 2364721662 DisPLDueToStOfCharge 4;
BA_ "SPN" SG_ 2364721662 DisPLDueToStOfCharge 16416;
BA_ "SigType" SG_ 2364721406 ActualChargeRate 1;
BA_ "SPN" SG_ 2364721406 ActualChargeRate 16388;
BA_ "SigType" SG_ 2364721406 LvlNegToChassisGroundV 1;
BA_ "SPN" SG_ 2364721406 LvlNegToChassisGroundV 16387;
BA_ "SigType" SG_ 2364721406 BusVNegToChassisGroundV 1;
BA_ "SPN" SG_ 2364721406 BusVNegToChassisGroundV 16386;
BA_ "SigType" SG_ 2364721150 HVBusPassiveIsolTestResults 1;
BA_ "SPN" SG_ 2364721150 HVBusPassiveIsolTestResults 16385;
BA_ "SigType" SG_ 2364721150 HVBusActiveIsolTestResults 1;
BA_ "SPN" SG_ 2364721150 HVBusActiveIsolTestResults 16384;
BA_ "SigType" SG_ 2364721150 LowestCellStOfChargeCellNum 1;
BA_ "SPN" SG_ 2364721150 LowestCellStOfChargeCellNum 16383;
BA_ "SigType" SG_ 2364721150 LowestCellStOfChargeModuleNum 1;
BA_ "SPN" SG_ 2364721150 LowestCellStOfChargeModuleNum 16382;
BA_ "SigType" SG_ 2364721150 HighestCellStOfChargeCellNum 1;
BA_ "SPN" SG_ 2364721150 HighestCellStOfChargeCellNum 16381;
BA_ "SigType" SG_ 2364721150 HighestCellStOfChargeModuleNum 1;
BA_ "SPN" SG_ 2364721150 HighestCellStOfChargeModuleNum 16380;
BA_ "SigType" SG_ 2364720894 Data9CRC 12;
BA_ "SPN" SG_ 2364720894 Data9CRC 23027;
BA_ "SigType" SG_ 2364720894 Data9Counter 11;
BA_ "SPN" SG_ 2364720894 Data9Counter 23026;
BA_ "SigType" SG_ 2364720894 Data9EmbeddedIntegritySupport 5;
BA_ "SPN" SG_ 2364720894 Data9EmbeddedIntegritySupport 23025;
BA_ "SigType" SG_ 2364720894 HVESS18ThermalEventDetected 4;
BA_ "SPN" SG_ 2364720894 HVESS18ThermalEventDetected 21305;
BA_ "SigType" SG_ 2364720894 LowestCellTempCellNum 1;
BA_ "SPN" SG_ 2364720894 LowestCellTempCellNum 16379;
BA_ "SigType" SG_ 2364720894 LowestCellTempModuleNum 1;
BA_ "SPN" SG_ 2364720894 LowestCellTempModuleNum 16378;
BA_ "SigType" SG_ 2364720894 HighestCellTempCellNum 1;
BA_ "SPN" SG_ 2364720894 HighestCellTempCellNum 16377;
BA_ "SigType" SG_ 2364720894 HighestCellTempModuleNum 1;
BA_ "SPN" SG_ 2364720894 HighestCellTempModuleNum 16376;
BA_ "SigType" SG_ 2364720638 AvgCellV 1;
BA_ "SPN" SG_ 2364720638 AvgCellV 16375;
BA_ "SigType" SG_ 2364720638 LowestCellVCellNum 1;
BA_ "SPN" SG_ 2364720638 LowestCellVCellNum 16374;
BA_ "SigType" SG_ 2364720638 LowestCellVModuleNum 1;
BA_ "SPN" SG_ 2364720638 LowestCellVModuleNum 16373;
BA_ "SigType" SG_ 2364720638 HighestCellVCellNum 1;
BA_ "SPN" SG_ 2364720638 HighestCellVCellNum 16372;
BA_ "SigType" SG_ 2364720638 HighestCellVModuleNum 1;
BA_ "SPN" SG_ 2364720638 HighestCellVModuleNum 16371;
BA_ "SigType" SG_ 2364720382 TMSCoolantLvl 4;
BA_ "SPN" SG_ 2364720382 TMSCoolantLvl 16370;
BA_ "SPN" SG_ 2364720382 TMSMode 16369;
BA_ "SigType" SG_ 2364720382 TMSHVILStatus 4;
BA_ "SPN" SG_ 2364720382 TMSHVILStatus 16368;
BA_ "SigType" SG_ 2364720382 TMSHtrStatus 5;
BA_ "SPN" SG_ 2364720382 TMSHtrStatus 16367;
BA_ "SigType" SG_ 2364720382 TMSRelHumidty 1;
BA_ "SPN" SG_ 2364720382 TMSRelHumidty 16366;
BA_ "SigType" SG_ 2364720382 TMSCompressorSpd 1;
BA_ "SPN" SG_ 2364720382 TMSCompressorSpd 16365;
BA_ "SigType" SG_ 2364720382 TMSHVInputPwr 1;
BA_ "SPN" SG_ 2364720382 TMSHVInputPwr 16364;
BA_ "SigType" SG_ 2364720382 TMSSLIInputPwr 1;
BA_ "SPN" SG_ 2364720382 TMSSLIInputPwr 16363;
BA_ "SigType" SG_ 2364720126 Module32OperationalStatus 5;
BA_ "SPN" SG_ 2364720126 Module32OperationalStatus 16362;
BA_ "SigType" SG_ 2364720126 Module31OperationalStatus 5;
BA_ "SPN" SG_ 2364720126 Module31OperationalStatus 16361;
BA_ "SigType" SG_ 2364720126 Module30OperationalStatus 5;
BA_ "SPN" SG_ 2364720126 Module30OperationalStatus 16360;
BA_ "SigType" SG_ 2364720126 Module29OperationalStatus 5;
BA_ "SPN" SG_ 2364720126 Module29OperationalStatus 16359;
BA_ "SigType" SG_ 2364720126 Module28OperationalStatus 5;
BA_ "SPN" SG_ 2364720126 Module28OperationalStatus 16358;
BA_ "SigType" SG_ 2364720126 Module27OperationalStatus 5;
BA_ "SPN" SG_ 2364720126 Module27OperationalStatus 16357;
BA_ "SigType" SG_ 2364720126 Module26OperationalStatus 5;
BA_ "SPN" SG_ 2364720126 Module26OperationalStatus 16356;
BA_ "SigType" SG_ 2364720126 Module25OperationalStatus 5;
BA_ "SPN" SG_ 2364720126 Module25OperationalStatus 16355;
BA_ "SigType" SG_ 2364720126 Module24OperationalStatus 5;
BA_ "SPN" SG_ 2364720126 Module24OperationalStatus 16354;
BA_ "SigType" SG_ 2364720126 Module23OperationalStatus 5;
BA_ "SPN" SG_ 2364720126 Module23OperationalStatus 16353;
BA_ "SigType" SG_ 2364720126 Module22OperationalStatus 5;
BA_ "SPN" SG_ 2364720126 Module22OperationalStatus 16352;
BA_ "SigType" SG_ 2364720126 Module21OperationalStatus 5;
BA_ "SPN" SG_ 2364720126 Module21OperationalStatus 16351;
BA_ "SigType" SG_ 2364720126 Module20OperationalStatus 5;
BA_ "SPN" SG_ 2364720126 Module20OperationalStatus 16350;
BA_ "SigType" SG_ 2364720126 Module19OperationalStatus 5;
BA_ "SPN" SG_ 2364720126 Module19OperationalStatus 16349;
BA_ "SigType" SG_ 2364720126 Module18OperationalStatus 5;
BA_ "SPN" SG_ 2364720126 Module18OperationalStatus 16348;
BA_ "SigType" SG_ 2364720126 Module17OperationalStatus 5;
BA_ "SPN" SG_ 2364720126 Module17OperationalStatus 16347;
BA_ "SigType" SG_ 2364720126 Module16OperationalStatus 5;
BA_ "SPN" SG_ 2364720126 Module16OperationalStatus 16346;
BA_ "SigType" SG_ 2364720126 Module15OperationalStatus 5;
BA_ "SPN" SG_ 2364720126 Module15OperationalStatus 16345;
BA_ "SigType" SG_ 2364720126 Module14OperationalStatus 5;
BA_ "SPN" SG_ 2364720126 Module14OperationalStatus 16344;
BA_ "SigType" SG_ 2364720126 Module13OperationalStatus 5;
BA_ "SPN" SG_ 2364720126 Module13OperationalStatus 16343;
BA_ "SigType" SG_ 2364720126 Module12OperationalStatus 5;
BA_ "SPN" SG_ 2364720126 Module12OperationalStatus 16342;
BA_ "SigType" SG_ 2364720126 Module11OperationalStatus 5;
BA_ "SPN" SG_ 2364720126 Module11OperationalStatus 16341;
BA_ "SigType" SG_ 2364720126 Module10OperationalStatus 5;
BA_ "SPN" SG_ 2364720126 Module10OperationalStatus 16340;
BA_ "SigType" SG_ 2364720126 Module9OperationalStatus 5;
BA_ "SPN" SG_ 2364720126 Module9OperationalStatus 16339;
BA_ "SigType" SG_ 2364720126 Module8OperationalStatus 5;
BA_ "SPN" SG_ 2364720126 Module8OperationalStatus 16338;
BA_ "SigType" SG_ 2364720126 Module7OperationalStatus 5;
BA_ "SPN" SG_ 2364720126 Module7OperationalStatus 16337;
BA_ "SigType" SG_ 2364720126 Module6OperationalStatus 5;
BA_ "SPN" SG_ 2364720126 Module6OperationalStatus 16336;
BA_ "SigType" SG_ 2364720126 Module5OperationalStatus 5;
BA_ "SPN" SG_ 2364720126 Module5OperationalStatus 16335;
BA_ "SigType" SG_ 2364720126 Module4OperationalStatus 5;
BA_ "SPN" SG_ 2364720126 Module4OperationalStatus 16334;
BA_ "SigType" SG_ 2364720126 Module3OperationalStatus 5;
BA_ "SPN" SG_ 2364720126 Module3OperationalStatus 16333;
BA_ "SigType" SG_ 2364720126 Module2OperationalStatus 5;
BA_ "SPN" SG_ 2364720126 Module2OperationalStatus 16332;
BA_ "SigType" SG_ 2364720126 Module1OperationalStatus 5;
BA_ "SPN" SG_ 2364720126 Module1OperationalStatus 16331;
BA_ "SigType" SG_ 2364719870 MaxChargeVLmt 1;
BA_ "SPN" SG_ 2364719870 MaxChargeVLmt 16330;
BA_ "SPN" SG_ 2364719870 ChargeEnergyCapacity 16329;
BA_ "SPN" SG_ 2364719870 DisEnergyCapacity 16328;
BA_ "SigType" SG_ 2364719614 Status1CRC 12;
BA_ "SPN" SG_ 2364719614 Status1CRC 16327;
BA_ "SigType" SG_ 2364719614 Status1Counter 11;
BA_ "SPN" SG_ 2364719614 Status1Counter 16326;
BA_ "SPN" SG_ 2364719614 OperationalStatus 16325;
BA_ "SPN" SG_ 2364719614 HVBusConnectionStatus 16324;
BA_ "SigType" SG_ 2364719614 InternalChargerStatus 5;
BA_ "SPN" SG_ 2364719614 InternalChargerStatus 16323;
BA_ "SigType" SG_ 2364719614 CellBalancingActive 4;
BA_ "SPN" SG_ 2364719614 CellBalancingActive 16322;
BA_ "SigType" SG_ 2364719614 CellBalanceStatus 4;
BA_ "SPN" SG_ 2364719614 CellBalanceStatus 16321;
BA_ "SPN" SG_ 2364719614 StOfChargeStatus 16320;
BA_ "SigType" SG_ 2364719614 InertiaSwStatus 4;
BA_ "SPN" SG_ 2364719614 InertiaSwStatus 16319;
BA_ "SigType" SG_ 2364719614 HVILStatus 4;
BA_ "SPN" SG_ 2364719614 HVILStatus 16318;
BA_ "SPN" SG_ 2364719614 HVBusPassiveIsolTestStatus 16317;
BA_ "SPN" SG_ 2364719614 HVBusActiveIsolTestStatus 16316;
BA_ "SigType" SG_ 2364719614 CenterOfPackContactorSt 4;
BA_ "SPN" SG_ 2364719614 CenterOfPackContactorSt 16315;
BA_ "SigType" SG_ 2364719614 HVBusPreChargeRelaySt 4;
BA_ "SPN" SG_ 2364719614 HVBusPreChargeRelaySt 16314;
BA_ "SPN" SG_ 2364719614 HVBusDisconnectForewarning 16313;
BA_ "SigType" SG_ 2364719614 HVBusContactorSt16312 4;
BA_ "SPN" SG_ 2364719614 HVBusContactorSt16312 16312;
BA_ "SigType" SG_ 2364719614 HVBusContactorSt 4;
BA_ "SPN" SG_ 2364719614 HVBusContactorSt 16311;
BA_ "SigType" SG_ 2364719358 Temp 1;
BA_ "SPN" SG_ 2364719358 Temp 16310;
BA_ "SigType" SG_ 2364719358 ETemp 1;
BA_ "SPN" SG_ 2364719358 ETemp 16309;
BA_ "SigType" SG_ 2364719358 OutCoolantTemp 1;
BA_ "SPN" SG_ 2364719358 OutCoolantTemp 16308;
BA_ "SigType" SG_ 2364719358 InCoolantTemp 1;
BA_ "SPN" SG_ 2364719358 InCoolantTemp 16307;
BA_ "SigType" SG_ 2364719358 IgntV 1;
BA_ "SPN" SG_ 2364719358 IgntV 16306;
BA_ "SigType" SG_ 2364719358 BusV 1;
BA_ "SPN" SG_ 2364719358 BusV 16305;
BA_ "SigType" SG_ 2364719102 HighestCellStOfCharge 1;
BA_ "SPN" SG_ 2364719102 HighestCellStOfCharge 16304;
BA_ "SigType" SG_ 2364719102 LowestCellStOfCharge 1;
BA_ "SPN" SG_ 2364719102 LowestCellStOfCharge 16303;
BA_ "SigType" SG_ 2364719102 ChargeCurLmt 1;
BA_ "GenSigStartValue" SG_ 2364719102 ChargeCurLmt 32000;
BA_ "SPN" SG_ 2364719102 ChargeCurLmt 16302;
BA_ "SigType" SG_ 2364719102 DisCurLmt 1;
BA_ "SPN" SG_ 2364719102 DisCurLmt 16301;
BA_ "SigType" SG_ 2364718846 CellBalancingCount 1;
BA_ "SPN" SG_ 2364718846 CellBalancingCount 16300;
BA_ "SigType" SG_ 2364718846 ChargeCapacity 1;
BA_ "SPN" SG_ 2364718846 ChargeCapacity 16299;
BA_ "SigType" SG_ 2364718846 DisCapacity 1;
BA_ "SPN" SG_ 2364718846 DisCapacity 16298;
BA_ "SigType" SG_ 2364718590 CellTempDiffStatus 4;
BA_ "SPN" SG_ 2364718590 CellTempDiffStatus 16297;
BA_ "SigType" SG_ 2364718590 AvgCellTemp 1;
BA_ "SPN" SG_ 2364718590 AvgCellTemp 16296;
BA_ "SigType" SG_ 2364718590 LowestCellTemp 1;
BA_ "SPN" SG_ 2364718590 LowestCellTemp 16295;
BA_ "SigType" SG_ 2364718590 HighestCellTemp 1;
BA_ "SPN" SG_ 2364718590 HighestCellTemp 16294;
BA_ "SPN" SG_ 2364718334 CellVDiffStatus 16293;
BA_ "SigType" SG_ 2364718334 LowestCellV 1;
BA_ "SPN" SG_ 2364718334 LowestCellV 16292;
BA_ "SigType" SG_ 2364718334 HighestCellV 1;
BA_ "SPN" SG_ 2364718334 HighestCellV 16291;
BA_ "SigType" SG_ 2364718334 FastUpdateStOfCharge 1;
BA_ "SPN" SG_ 2364718334 FastUpdateStOfCharge 16290;
BA_ "SigType" SG_ 2364718078 Cur 1;
BA_ "SPN" SG_ 2364718078 Cur 16289;
BA_ "SigType" SG_ 2364718078 Lvl 1;
BA_ "SPN" SG_ 2364718078 Lvl 16288;
BA_ "SigType" SG_ 2364718078 AvailableChargePwr 1;
BA_ "SPN" SG_ 2364718078 AvailableChargePwr 16287;
BA_ "SigType" SG_ 2364718078 AvailableDisPwr 1;
BA_ "SPN" SG_ 2364718078 AvailableDisPwr 16286;
BA_ "SigType" SG_ 2364717822 ChargePLDueToAnUndefinedCause 4;
BA_ "SPN" SG_ 2364717822 ChargePLDueToAnUndefinedCause 16285;
BA_ "SigType" SG_ 2364717822 ChargePLDueToBatCur 4;
BA_ "SPN" SG_ 2364717822 ChargePLDueToBatCur 16284;
BA_ "SigType" SG_ 2364717822 ChargePLDueToBatOrCellV 4;
BA_ "SPN" SG_ 2364717822 ChargePLDueToBatOrCellV 16283;
BA_ "SigType" SG_ 2364717822 ChargePLDueToBatDiagCondition 4;
BA_ "SPN" SG_ 2364717822 ChargePLDueToBatDiagCondition 16282;
BA_ "SigType" SG_ 2364717822 ChargePLDueToBatTemp 4;
BA_ "SPN" SG_ 2364717822 ChargePLDueToBatTemp 16281;
BA_ "SigType" SG_ 2364717822 ChargePLDueToStOfCharge 4;
BA_ "SPN" SG_ 2364717822 ChargePLDueToStOfCharge 16280;
BA_ "SigType" SG_ 2364717822 DisPLDueToAnUndefinedCause 4;
BA_ "SPN" SG_ 2364717822 DisPLDueToAnUndefinedCause 16279;
BA_ "SigType" SG_ 2364717822 DisPLDueToBatCur 4;
BA_ "SPN" SG_ 2364717822 DisPLDueToBatCur 16278;
BA_ "SigType" SG_ 2364717822 DisPLDueToBatOrCellV 4;
BA_ "SPN" SG_ 2364717822 DisPLDueToBatOrCellV 16277;
BA_ "SigType" SG_ 2364717822 DisPLDueToBatDiagCondition 4;
BA_ "SPN" SG_ 2364717822 DisPLDueToBatDiagCondition 16276;
BA_ "SigType" SG_ 2364717822 DisPLDueToBatTemp 4;
BA_ "SPN" SG_ 2364717822 DisPLDueToBatTemp 16275;
BA_ "SigType" SG_ 2364717822 DisPLDueToStOfCharge 4;
BA_ "SPN" SG_ 2364717822 DisPLDueToStOfCharge 16274;
BA_ "SigType" SG_ 2364717566 ActualChargeRate 1;
BA_ "SPN" SG_ 2364717566 ActualChargeRate 16246;
BA_ "SigType" SG_ 2364717566 LvlNegToChassisGroundV 1;
BA_ "SPN" SG_ 2364717566 LvlNegToChassisGroundV 16245;
BA_ "SigType" SG_ 2364717566 BusVNegToChassisGroundV 1;
BA_ "SPN" SG_ 2364717566 BusVNegToChassisGroundV 16244;
BA_ "SigType" SG_ 2364717310 HVBusPassiveIsolTestResults 1;
BA_ "SPN" SG_ 2364717310 HVBusPassiveIsolTestResults 16243;
BA_ "SigType" SG_ 2364717310 HVBusActiveIsolTestResults 1;
BA_ "SPN" SG_ 2364717310 HVBusActiveIsolTestResults 16242;
BA_ "SigType" SG_ 2364717310 LowestCellStOfChargeCellNum 1;
BA_ "SPN" SG_ 2364717310 LowestCellStOfChargeCellNum 16241;
BA_ "SigType" SG_ 2364717310 LowestCellStOfChargeModuleNum 1;
BA_ "SPN" SG_ 2364717310 LowestCellStOfChargeModuleNum 16240;
BA_ "SigType" SG_ 2364717310 HighestCellStOfChargeCellNum 1;
BA_ "SPN" SG_ 2364717310 HighestCellStOfChargeCellNum 16239;
BA_ "SigType" SG_ 2364717310 HighestCellStOfChargeModuleNum 1;
BA_ "SPN" SG_ 2364717310 HighestCellStOfChargeModuleNum 16238;
BA_ "SigType" SG_ 2364717054 Data9CRC 12;
BA_ "SPN" SG_ 2364717054 Data9CRC 23024;
BA_ "SigType" SG_ 2364717054 Data9Counter 11;
BA_ "SPN" SG_ 2364717054 Data9Counter 23023;
BA_ "SigType" SG_ 2364717054 Data9EmbeddedIntegritySupport 5;
BA_ "SPN" SG_ 2364717054 Data9EmbeddedIntegritySupport 23022;
BA_ "SigType" SG_ 2364717054 HVESS17ThermalEventDetected 4;
BA_ "SPN" SG_ 2364717054 HVESS17ThermalEventDetected 21304;
BA_ "SigType" SG_ 2364717054 LowestCellTempCellNum 1;
BA_ "SPN" SG_ 2364717054 LowestCellTempCellNum 16237;
BA_ "SigType" SG_ 2364717054 LowestCellTempModuleNum 1;
BA_ "SPN" SG_ 2364717054 LowestCellTempModuleNum 16236;
BA_ "SigType" SG_ 2364717054 HighestCellTempCellNum 1;
BA_ "SPN" SG_ 2364717054 HighestCellTempCellNum 16235;
BA_ "SigType" SG_ 2364717054 HighestCellTempModuleNum 1;
BA_ "SPN" SG_ 2364717054 HighestCellTempModuleNum 16234;
BA_ "SigType" SG_ 2364716798 AvgCellV 1;
BA_ "SPN" SG_ 2364716798 AvgCellV 16233;
BA_ "SigType" SG_ 2364716798 LowestCellVCellNum 1;
BA_ "SPN" SG_ 2364716798 LowestCellVCellNum 16232;
BA_ "SigType" SG_ 2364716798 LowestCellVModuleNum 1;
BA_ "SPN" SG_ 2364716798 LowestCellVModuleNum 16231;
BA_ "SigType" SG_ 2364716798 HighestCellVCellNum 1;
BA_ "SPN" SG_ 2364716798 HighestCellVCellNum 16230;
BA_ "SigType" SG_ 2364716798 HighestCellVModuleNum 1;
BA_ "SPN" SG_ 2364716798 HighestCellVModuleNum 16229;
BA_ "SigType" SG_ 2364716542 TMSCoolantLvl 4;
BA_ "SPN" SG_ 2364716542 TMSCoolantLvl 16228;
BA_ "SPN" SG_ 2364716542 TMSMode 16227;
BA_ "SigType" SG_ 2364716542 TMSHVILStatus 4;
BA_ "SPN" SG_ 2364716542 TMSHVILStatus 16226;
BA_ "SigType" SG_ 2364716542 TMSHtrStatus 5;
BA_ "SPN" SG_ 2364716542 TMSHtrStatus 16225;
BA_ "SigType" SG_ 2364716542 TMSRelHumidty 1;
BA_ "SPN" SG_ 2364716542 TMSRelHumidty 16224;
BA_ "SigType" SG_ 2364716542 TMSCompressorSpd 1;
BA_ "SPN" SG_ 2364716542 TMSCompressorSpd 16223;
BA_ "SigType" SG_ 2364716542 TMSHVInputPwr 1;
BA_ "SPN" SG_ 2364716542 TMSHVInputPwr 16222;
BA_ "SigType" SG_ 2364716542 TMSSLIInputPwr 1;
BA_ "SPN" SG_ 2364716542 TMSSLIInputPwr 16221;
BA_ "SigType" SG_ 2364716286 Module32OperationalStatus 5;
BA_ "SPN" SG_ 2364716286 Module32OperationalStatus 16220;
BA_ "SigType" SG_ 2364716286 Module31OperationalStatus 5;
BA_ "SPN" SG_ 2364716286 Module31OperationalStatus 16219;
BA_ "SigType" SG_ 2364716286 Module30OperationalStatus 5;
BA_ "SPN" SG_ 2364716286 Module30OperationalStatus 16218;
BA_ "SigType" SG_ 2364716286 Module29OperationalStatus 5;
BA_ "SPN" SG_ 2364716286 Module29OperationalStatus 16217;
BA_ "SigType" SG_ 2364716286 Module28OperationalStatus 5;
BA_ "SPN" SG_ 2364716286 Module28OperationalStatus 16216;
BA_ "SigType" SG_ 2364716286 Module27OperationalStatus 5;
BA_ "SPN" SG_ 2364716286 Module27OperationalStatus 16215;
BA_ "SigType" SG_ 2364716286 Module26OperationalStatus 5;
BA_ "SPN" SG_ 2364716286 Module26OperationalStatus 16214;
BA_ "SigType" SG_ 2364716286 Module25OperationalStatus 5;
BA_ "SPN" SG_ 2364716286 Module25OperationalStatus 16213;
BA_ "SigType" SG_ 2364716286 Module24OperationalStatus 5;
BA_ "SPN" SG_ 2364716286 Module24OperationalStatus 16212;
BA_ "SigType" SG_ 2364716286 Module23OperationalStatus 5;
BA_ "SPN" SG_ 2364716286 Module23OperationalStatus 16211;
BA_ "SigType" SG_ 2364716286 Module22OperationalStatus 5;
BA_ "SPN" SG_ 2364716286 Module22OperationalStatus 16210;
BA_ "SigType" SG_ 2364716286 Module21OperationalStatus 5;
BA_ "SPN" SG_ 2364716286 Module21OperationalStatus 16209;
BA_ "SigType" SG_ 2364716286 Module20OperationalStatus 5;
BA_ "SPN" SG_ 2364716286 Module20OperationalStatus 16208;
BA_ "SigType" SG_ 2364716286 Module19OperationalStatus 5;
BA_ "SPN" SG_ 2364716286 Module19OperationalStatus 16207;
BA_ "SigType" SG_ 2364716286 Module18OperationalStatus 5;
BA_ "SPN" SG_ 2364716286 Module18OperationalStatus 16206;
BA_ "SigType" SG_ 2364716286 Module17OperationalStatus 5;
BA_ "SPN" SG_ 2364716286 Module17OperationalStatus 16205;
BA_ "SigType" SG_ 2364716286 Module16OperationalStatus 5;
BA_ "SPN" SG_ 2364716286 Module16OperationalStatus 16204;
BA_ "SigType" SG_ 2364716286 Module15OperationalStatus 5;
BA_ "SPN" SG_ 2364716286 Module15OperationalStatus 16203;
BA_ "SigType" SG_ 2364716286 Module14OperationalStatus 5;
BA_ "SPN" SG_ 2364716286 Module14OperationalStatus 16202;
BA_ "SigType" SG_ 2364716286 Module13OperationalStatus 5;
BA_ "SPN" SG_ 2364716286 Module13OperationalStatus 16201;
BA_ "SigType" SG_ 2364716286 Module12OperationalStatus 5;
BA_ "SPN" SG_ 2364716286 Module12OperationalStatus 16200;
BA_ "SigType" SG_ 2364716286 Module11OperationalStatus 5;
BA_ "SPN" SG_ 2364716286 Module11OperationalStatus 16199;
BA_ "SigType" SG_ 2364716286 Module10OperationalStatus 5;
BA_ "SPN" SG_ 2364716286 Module10OperationalStatus 16198;
BA_ "SigType" SG_ 2364716286 Module9OperationalStatus 5;
BA_ "SPN" SG_ 2364716286 Module9OperationalStatus 16197;
BA_ "SigType" SG_ 2364716286 Module8OperationalStatus 5;
BA_ "SPN" SG_ 2364716286 Module8OperationalStatus 16196;
BA_ "SigType" SG_ 2364716286 Module7OperationalStatus 5;
BA_ "SPN" SG_ 2364716286 Module7OperationalStatus 16195;
BA_ "SigType" SG_ 2364716286 Module6OperationalStatus 5;
BA_ "SPN" SG_ 2364716286 Module6OperationalStatus 16194;
BA_ "SigType" SG_ 2364716286 Module5OperationalStatus 5;
BA_ "SPN" SG_ 2364716286 Module5OperationalStatus 16193;
BA_ "SigType" SG_ 2364716286 Module4OperationalStatus 5;
BA_ "SPN" SG_ 2364716286 Module4OperationalStatus 16192;
BA_ "SigType" SG_ 2364716286 Module3OperationalStatus 5;
BA_ "SPN" SG_ 2364716286 Module3OperationalStatus 16191;
BA_ "SigType" SG_ 2364716286 Module2OperationalStatus 5;
BA_ "SPN" SG_ 2364716286 Module2OperationalStatus 16190;
BA_ "SigType" SG_ 2364716286 Module1OperationalStatus 5;
BA_ "SPN" SG_ 2364716286 Module1OperationalStatus 16189;
BA_ "SigType" SG_ 2364716030 MaxChargeVLmt 1;
BA_ "SPN" SG_ 2364716030 MaxChargeVLmt 16188;
BA_ "SPN" SG_ 2364716030 ChargeEnergyCapacity 16187;
BA_ "SPN" SG_ 2364716030 DisEnergyCapacity 16186;
BA_ "SigType" SG_ 2364715774 Status1CRC 12;
BA_ "SPN" SG_ 2364715774 Status1CRC 16185;
BA_ "SigType" SG_ 2364715774 Status1Counter 11;
BA_ "SPN" SG_ 2364715774 Status1Counter 16184;
BA_ "SPN" SG_ 2364715774 OperationalStatus 16183;
BA_ "SPN" SG_ 2364715774 HVBusConnectionStatus 16182;
BA_ "SigType" SG_ 2364715774 InternalChargerStatus 5;
BA_ "SPN" SG_ 2364715774 InternalChargerStatus 16181;
BA_ "SigType" SG_ 2364715774 CellBalancingActive 4;
BA_ "SPN" SG_ 2364715774 CellBalancingActive 16180;
BA_ "SigType" SG_ 2364715774 CellBalanceStatus 4;
BA_ "SPN" SG_ 2364715774 CellBalanceStatus 16179;
BA_ "SPN" SG_ 2364715774 StOfChargeStatus 16178;
BA_ "SigType" SG_ 2364715774 InertiaSwStatus 4;
BA_ "SPN" SG_ 2364715774 InertiaSwStatus 16177;
BA_ "SigType" SG_ 2364715774 HVILStatus 4;
BA_ "SPN" SG_ 2364715774 HVILStatus 16176;
BA_ "SPN" SG_ 2364715774 HVBusPassiveIsolTestStatus 16175;
BA_ "SPN" SG_ 2364715774 HVBusActiveIsolTestStatus 16174;
BA_ "SigType" SG_ 2364715774 CenterOfPackContactorSt 4;
BA_ "SPN" SG_ 2364715774 CenterOfPackContactorSt 16173;
BA_ "SigType" SG_ 2364715774 HVBusPreChargeRelaySt 4;
BA_ "SPN" SG_ 2364715774 HVBusPreChargeRelaySt 16172;
BA_ "SPN" SG_ 2364715774 HVBusDisconnectForewarning 16171;
BA_ "SigType" SG_ 2364715774 HVBusContactorSt16170 4;
BA_ "SPN" SG_ 2364715774 HVBusContactorSt16170 16170;
BA_ "SigType" SG_ 2364715774 HVBusContactorSt 4;
BA_ "SPN" SG_ 2364715774 HVBusContactorSt 16169;
BA_ "SigType" SG_ 2364715518 Temp 1;
BA_ "SPN" SG_ 2364715518 Temp 16168;
BA_ "SigType" SG_ 2364715518 ETemp 1;
BA_ "SPN" SG_ 2364715518 ETemp 16167;
BA_ "SigType" SG_ 2364715518 OutCoolantTemp 1;
BA_ "SPN" SG_ 2364715518 OutCoolantTemp 16166;
BA_ "SigType" SG_ 2364715518 InCoolantTemp 1;
BA_ "SPN" SG_ 2364715518 InCoolantTemp 16165;
BA_ "SigType" SG_ 2364715518 IgntV 1;
BA_ "SPN" SG_ 2364715518 IgntV 16164;
BA_ "SigType" SG_ 2364715518 BusV 1;
BA_ "SPN" SG_ 2364715518 BusV 16163;
BA_ "SigType" SG_ 2364715262 HighestCellStOfCharge 1;
BA_ "SPN" SG_ 2364715262 HighestCellStOfCharge 16162;
BA_ "SigType" SG_ 2364715262 LowestCellStOfCharge 1;
BA_ "SPN" SG_ 2364715262 LowestCellStOfCharge 16161;
BA_ "SigType" SG_ 2364715262 ChargeCurLmt 1;
BA_ "GenSigStartValue" SG_ 2364715262 ChargeCurLmt 32000;
BA_ "SPN" SG_ 2364715262 ChargeCurLmt 16160;
BA_ "SigType" SG_ 2364715262 DisCurLmt 1;
BA_ "SPN" SG_ 2364715262 DisCurLmt 16159;
BA_ "SigType" SG_ 2364715006 CellBalancingCount 1;
BA_ "SPN" SG_ 2364715006 CellBalancingCount 16158;
BA_ "SigType" SG_ 2364715006 ChargeCapacity 1;
BA_ "SPN" SG_ 2364715006 ChargeCapacity 16157;
BA_ "SigType" SG_ 2364715006 DisCapacity 1;
BA_ "SPN" SG_ 2364715006 DisCapacity 16156;
BA_ "SigType" SG_ 2364714750 CellTempDiffStatus 4;
BA_ "SPN" SG_ 2364714750 CellTempDiffStatus 16155;
BA_ "SigType" SG_ 2364714750 AvgCellTemp 1;
BA_ "SPN" SG_ 2364714750 AvgCellTemp 16154;
BA_ "SigType" SG_ 2364714750 LowestCellTemp 1;
BA_ "SPN" SG_ 2364714750 LowestCellTemp 16153;
BA_ "SigType" SG_ 2364714750 HighestCellTemp 1;
BA_ "SPN" SG_ 2364714750 HighestCellTemp 16152;
BA_ "SPN" SG_ 2364714494 CellVDiffStatus 16151;
BA_ "SigType" SG_ 2364714494 LowestCellV 1;
BA_ "SPN" SG_ 2364714494 LowestCellV 16150;
BA_ "SigType" SG_ 2364714494 HighestCellV 1;
BA_ "SPN" SG_ 2364714494 HighestCellV 16149;
BA_ "SigType" SG_ 2364714494 FastUpdateStOfCharge 1;
BA_ "SPN" SG_ 2364714494 FastUpdateStOfCharge 16148;
BA_ "SigType" SG_ 2364714238 Cur 1;
BA_ "SPN" SG_ 2364714238 Cur 16147;
BA_ "SigType" SG_ 2364714238 Lvl 1;
BA_ "SPN" SG_ 2364714238 Lvl 16146;
BA_ "SigType" SG_ 2364714238 AvailableChargePwr 1;
BA_ "SPN" SG_ 2364714238 AvailableChargePwr 16145;
BA_ "SigType" SG_ 2364714238 AvailableDisPwr 1;
BA_ "SPN" SG_ 2364714238 AvailableDisPwr 16144;
BA_ "SigType" SG_ 2364713982 ChargePLDueToAnUndefinedCause 4;
BA_ "SPN" SG_ 2364713982 ChargePLDueToAnUndefinedCause 16143;
BA_ "SigType" SG_ 2364713982 ChargePLDueToBatCur 4;
BA_ "SPN" SG_ 2364713982 ChargePLDueToBatCur 16142;
BA_ "SigType" SG_ 2364713982 ChargePLDueToBatOrCellV 4;
BA_ "SPN" SG_ 2364713982 ChargePLDueToBatOrCellV 16141;
BA_ "SigType" SG_ 2364713982 ChargePLDueToBatDiagCondition 4;
BA_ "SPN" SG_ 2364713982 ChargePLDueToBatDiagCondition 16140;
BA_ "SigType" SG_ 2364713982 ChargePLDueToBatTemp 4;
BA_ "SPN" SG_ 2364713982 ChargePLDueToBatTemp 16139;
BA_ "SigType" SG_ 2364713982 ChargePLDueToStOfCharge 4;
BA_ "SPN" SG_ 2364713982 ChargePLDueToStOfCharge 16138;
BA_ "SigType" SG_ 2364713982 DisPLDueToAnUndefinedCause 4;
BA_ "SPN" SG_ 2364713982 DisPLDueToAnUndefinedCause 16137;
BA_ "SigType" SG_ 2364713982 DisPLDueToBatCur 4;
BA_ "SPN" SG_ 2364713982 DisPLDueToBatCur 16136;
BA_ "SigType" SG_ 2364713982 DisPLDueToBatOrCellV 4;
BA_ "SPN" SG_ 2364713982 DisPLDueToBatOrCellV 16135;
BA_ "SigType" SG_ 2364713982 DisPLDueToBatDiagCondition 4;
BA_ "SPN" SG_ 2364713982 DisPLDueToBatDiagCondition 16134;
BA_ "SigType" SG_ 2364713982 DisPLDueToBatTemp 4;
BA_ "SPN" SG_ 2364713982 DisPLDueToBatTemp 16133;
BA_ "SigType" SG_ 2364713982 DisPLDueToStOfCharge 4;
BA_ "SPN" SG_ 2364713982 DisPLDueToStOfCharge 16132;
BA_ "SigType" SG_ 2364713726 ActualChargeRate 1;
BA_ "SPN" SG_ 2364713726 ActualChargeRate 16104;
BA_ "SigType" SG_ 2364713726 LvlNegToChassisGroundV 1;
BA_ "SPN" SG_ 2364713726 LvlNegToChassisGroundV 16103;
BA_ "SigType" SG_ 2364713726 BusVNegToChassisGroundV 1;
BA_ "SPN" SG_ 2364713726 BusVNegToChassisGroundV 16102;
BA_ "SigType" SG_ 2364713470 HVBusPassiveIsolTestResults 1;
BA_ "SPN" SG_ 2364713470 HVBusPassiveIsolTestResults 16101;
BA_ "SigType" SG_ 2364713470 HVBusActiveIsolTestResults 1;
BA_ "SPN" SG_ 2364713470 HVBusActiveIsolTestResults 16100;
BA_ "SigType" SG_ 2364713470 LowestCellStOfChargeCellNum 1;
BA_ "SPN" SG_ 2364713470 LowestCellStOfChargeCellNum 16099;
BA_ "SigType" SG_ 2364713470 LowestCellStOfChargeModuleNum 1;
BA_ "SPN" SG_ 2364713470 LowestCellStOfChargeModuleNum 16098;
BA_ "SigType" SG_ 2364713470 HighestCellStOfChargeCellNum 1;
BA_ "SPN" SG_ 2364713470 HighestCellStOfChargeCellNum 16097;
BA_ "SigType" SG_ 2364713470 HighestCellStOfChargeModuleNum 1;
BA_ "SPN" SG_ 2364713470 HighestCellStOfChargeModuleNum 16096;
BA_ "SigType" SG_ 2364713214 Data9CRC 12;
BA_ "SPN" SG_ 2364713214 Data9CRC 23021;
BA_ "SigType" SG_ 2364713214 Data9Counter 11;
BA_ "SPN" SG_ 2364713214 Data9Counter 23020;
BA_ "SigType" SG_ 2364713214 Data9EmbeddedIntegritySupport 5;
BA_ "SPN" SG_ 2364713214 Data9EmbeddedIntegritySupport 23019;
BA_ "SigType" SG_ 2364713214 HVESS16ThermalEventDetected 4;
BA_ "SPN" SG_ 2364713214 HVESS16ThermalEventDetected 21303;
BA_ "SigType" SG_ 2364713214 LowestCellTempCellNum 1;
BA_ "SPN" SG_ 2364713214 LowestCellTempCellNum 16095;
BA_ "SigType" SG_ 2364713214 LowestCellTempModuleNum 1;
BA_ "SPN" SG_ 2364713214 LowestCellTempModuleNum 16094;
BA_ "SigType" SG_ 2364713214 HighestCellTempCellNum 1;
BA_ "SPN" SG_ 2364713214 HighestCellTempCellNum 16093;
BA_ "SigType" SG_ 2364713214 HighestCellTempModuleNum 1;
BA_ "SPN" SG_ 2364713214 HighestCellTempModuleNum 16092;
BA_ "SigType" SG_ 2364712958 AvgCellV 1;
BA_ "SPN" SG_ 2364712958 AvgCellV 16091;
BA_ "SigType" SG_ 2364712958 LowestCellVCellNum 1;
BA_ "SPN" SG_ 2364712958 LowestCellVCellNum 16090;
BA_ "SigType" SG_ 2364712958 LowestCellVModuleNum 1;
BA_ "SPN" SG_ 2364712958 LowestCellVModuleNum 16089;
BA_ "SigType" SG_ 2364712958 HighestCellVCellNum 1;
BA_ "SPN" SG_ 2364712958 HighestCellVCellNum 16088;
BA_ "SigType" SG_ 2364712958 HighestCellVModuleNum 1;
BA_ "SPN" SG_ 2364712958 HighestCellVModuleNum 16087;
BA_ "SigType" SG_ 2364712702 TMSCoolantLvl 4;
BA_ "SPN" SG_ 2364712702 TMSCoolantLvl 16086;
BA_ "SPN" SG_ 2364712702 TMSMode 16085;
BA_ "SigType" SG_ 2364712702 TMSHVILStatus 4;
BA_ "SPN" SG_ 2364712702 TMSHVILStatus 16084;
BA_ "SigType" SG_ 2364712702 TMSHtrStatus 5;
BA_ "SPN" SG_ 2364712702 TMSHtrStatus 16083;
BA_ "SigType" SG_ 2364712702 TMSRelHumidty 1;
BA_ "SPN" SG_ 2364712702 TMSRelHumidty 16082;
BA_ "SigType" SG_ 2364712702 TMSCompressorSpd 1;
BA_ "SPN" SG_ 2364712702 TMSCompressorSpd 16081;
BA_ "SigType" SG_ 2364712702 TMSHVInputPwr 1;
BA_ "SPN" SG_ 2364712702 TMSHVInputPwr 16080;
BA_ "SigType" SG_ 2364712702 TMSSLIInputPwr 1;
BA_ "SPN" SG_ 2364712702 TMSSLIInputPwr 16079;
VAL_ 2364723454 OperationalStatus 15 "Not Available" 14 "Error" 13 "Reserved" 12 "Reserved" 11 "Reserved" 10 "Reserved" 9 "Reserved" 8 "Reserved" 7 "Reserved" 6 "Disabled by internal decision of HVES controller" 5 "Disabled by external command" 4 "Emergency Power-Down In Process" 3 "Normal Power-Down in Process" 2 "Operational." 1 "Initialization Complete" 0 "Initialization in process" ;
VAL_ 2364723454 HVBusConnectionStatus 15 "Not Available" 14 "Error" 13 "Reserved" 12 "Reserved" 11 "Reserved" 10 "Reserved" 9 "Reserved" 8 "Reserved" 7 "Reserved" 6 "Reserved" 5 "Reserved" 4 "Disconnected,  Precharge Failed" 3 "Disconnection in Process" 2 "Connection in Process" 1 "Connected" 0 "Disconnected, One or more contactors are open" ;
VAL_ 2364723454 InternalChargerStatus 3 "Not Available" 2 "Error" 1 "Charging on" 0 "Charging off" ;
VAL_ 2364723454 CellBalancingActive 3 "Not Available" 2 "Error" 1 "Cell balancing is active" 0 "Cell balancing is not active" ;
VAL_ 2364723454 CellBalanceStatus 3 "Not Available" 2 "Error" 1 "Cells are unbalanced" 0 "Cells are balanced" ;
VAL_ 2364723454 StOfChargeStatus 15 "Not  Available" 14 "Error" 13 "Reserved" 12 "Reserved" 11 "Reserved" 10 "Reserved" 9 "Reserved" 8 "Reserved" 7 "Reserved" 6 "SOC is above its recommended upper limit" 5 "SOC is at its recommended upper limit" 4 "SOC is approaching its recommended upper limit" 3 "SOC is below its recommended lower limit" 2 "SOC is at its recommended lower limit" 1 "SOC is approaching its recommended lower limit" 0 "SOC level is acceptable" ;
VAL_ 2364723454 InertiaSwStatus 3 "Not Available" 2 "Error" 1 "Impact sensed" 0 "No impact sensed" ;
VAL_ 2364723454 HVILStatus 3 "Not Available" 2 "Error" 1 "HVIL Open" 0 "HVIL Closed" ;
VAL_ 2364723454 HVBusPassiveIsolTestStatus 15 "Not available" 14 "Error" 13 "Reserved" 12 "Reserved" 11 "Reserved" 10 "Reserved" 9 "Reserved" 8 "Reserved" 7 "Reserved" 6 "Reserved" 5 "Test complete,  isolation fault" 4 "Test complete,  isolation marginal" 3 "Test complete,  isolation acceptable" 2 "Test in process" 1 "Test requested but not yet in process" 0 "No test requested / No test in process" ;
VAL_ 2364723454 HVBusActiveIsolTestStatus 15 "Not available" 14 "Error" 13 "Reserved" 12 "Reserved" 11 "Reserved" 10 "Reserved" 9 "Reserved" 8 "Reserved" 7 "Reserved" 6 "Reserved" 5 "Test complete,  isolation fault" 4 "Test complete,  isolation marginal" 3 "Test complete,  isolation acceptable" 2 "Test in process" 1 "Test requested but not yet in process" 0 "No test requested / No test in process" ;
VAL_ 2364723454 CenterOfPackContactorSt 3 "Not Available" 2 "Error" 1 "Contactor Closed" 0 "Contactor Open" ;
VAL_ 2364723454 HVBusPreChargeRelaySt 3 "Not Available" 2 "Error" 1 "Relay Closed" 0 "Relay Open" ;
VAL_ 2364723454 HVBusDisconnectForewarning 15 "Not Available" 14 "Error" 13 "Disconnect imminent" 12 "Reserved" 11 "Reserved" 10 "Reserved" 9 "Reserved" 8 "Reserved" 7 "Disconnect imminent due to battery pack current approaching maximum acceptable level" 6 "Disconnect imminent due to cell voltage approaching maximum acceptable level" 5 "Disconnect imminent due to cell voltage approaching minimum acceptable level" 4 "Disconnect imminent due to module voltage approaching maximum acceptable level" 3 "Disconnect imminent due to module voltage approaching minimum acceptable level" 2 "Disconnect imminent due to battery pack voltage approaching maximum acceptable level" 1 "Disconnect imminent due to battery pack voltage approaching minimum acceptable level" 0 "Disconnect not pending" ;
VAL_ 2364723454 HVBusContactorSt16454 3 "Not Available" 2 "Error" 1 "Contactor Closed" 0 "Contactor Open" ;
VAL_ 2364723454 HVBusContactorSt 3 "Not Available" 2 "Error" 1 "Contactor Closed" 0 "Contactor Open" ;
VAL_ 2364722430 CellTempDiffStatus 3 "Not Available" 2 "Error" 1 "Cell-to-cell temperature differential exceeds acceptable limits" 0 "Cell-to-cell temperature differential is within acceptable limits" ;
VAL_ 2364722174 CellVDiffStatus 15 "Not Available" 14 "Error" 13 "Reserved" 12 "Reserved" 11 "Reserved" 10 "Reserved" 9 "Reserved" 8 "Reserved" 7 "Reserved" 6 "Reserved" 5 "Reserved" 4 "Exceeds limits and it is not known whether balancing can restore performance" 3 "Exceeds limits and external maintenance balancing cannot restore performance" 2 "Exceeds limits and external maintenance balancing is required" 1 "Exceeds limits and can be corrected via auto-balancing" 0 "Is within acceptable limits" ;
VAL_ 2364721662 ChargePLDueToAnUndefinedCause 3 "Not Available" 2 "Error" 1 "Power limited for this reason" 0 "No power limit for this reason" ;
VAL_ 2364721662 ChargePLDueToBatCur 3 "Not Available" 2 "Error" 1 "Power limited for this reason" 0 "No power limit for this reason" ;
VAL_ 2364721662 ChargePLDueToBatOrCellV 3 "Not Available" 2 "Error" 1 "Power limited for this reason" 0 "No power limit for this reason" ;
VAL_ 2364721662 ChargePLDueToBatDiagCondition 3 "Not Available" 2 "Error" 1 "Power limited for this reason" 0 "No power limit for this reason" ;
VAL_ 2364721662 ChargePLDueToBatTemp 3 "Not Available" 2 "Error" 1 "Power limited for this reason" 0 "No power limit for this reason" ;
VAL_ 2364721662 ChargePLDueToStOfCharge 3 "Not Available" 2 "Error" 1 "Power limited for this reason" 0 "No power limit for this reason" ;
VAL_ 2364721662 DisPLDueToAnUndefinedCause 3 "Not Available" 2 "Error" 1 "Power limited for this reason" 0 "No power limit for this reason" ;
VAL_ 2364721662 DisPLDueToBatCur 3 "Not Available" 2 "Error" 1 "Power limited for this reason" 0 "No power limit for this reason" ;
VAL_ 2364721662 DisPLDueToBatOrCellV 3 "Not Available" 2 "Error" 1 "Power limited for this reason" 0 "No power limit for this reason" ;
VAL_ 2364721662 DisPLDueToBatDiagCondition 3 "Not Available" 2 "Error" 1 "Power limited for this reason" 0 "No power limit for this reason" ;
VAL_ 2364721662 DisPLDueToBatTemp 3 "Not Available" 2 "Error" 1 "Power limited for this reason" 0 "No power limit for this reason" ;
VAL_ 2364721662 DisPLDueToStOfCharge 3 "Not Available" 2 "Error" 1 "Power limited for this reason" 0 "No power limit for this reason" ;
VAL_ 2364720894 Data9EmbeddedIntegritySupport 3 "CRC and Counter are not supported by the sender" 2 "Reserved" 1 "Protection is supported using J1939-76 SHM" 0 "Embedded CRC and Counter are supported by the sender" ;
VAL_ 2364720894 HVESS18ThermalEventDetected 3 "Not available" 2 "Error" 1 "Thermal Event Detected" 0 "No Thermal Event Detected" ;
VAL_ 2364720382 TMSCoolantLvl 3 "Not Available" 2 "Error" 1 "Coolant Level is sufficient" 0 "Coolant Level is not sufficient" ;
VAL_ 2364720382 TMSMode 15 "Not Available" 14 "Faulted" 13 "Reserved" 12 "Reserved" 11 "Reserved" 10 "Reserved" 9 "Reserved" 8 "Reserved" 7 "Reserved" 6 "Reserved" 5 "Maintaining" 4 "Drying" 3 "Heating" 2 "Cooling" 1 "Circulating" 0 "Off" ;
VAL_ 2364720382 TMSHVILStatus 3 "Not Available" 2 "Error" 1 "HVIL Open" 0 "HVIL Closed" ;
VAL_ 2364720382 TMSHtrStatus 3 "Not Available" 2 "Error" 1 "Heater On" 0 "Heater Off" ;
VAL_ 2364720126 Module32OperationalStatus 3 "Not Available" 2 "Error" 1 "Operational" 0 "Not Operational" ;
VAL_ 2364720126 Module31OperationalStatus 3 "Not Available" 2 "Error" 1 "Operational" 0 "Not Operational" ;
VAL_ 2364720126 Module30OperationalStatus 3 "Not Available" 2 "Error" 1 "Operational" 0 "Not Operational" ;
VAL_ 2364720126 Module29OperationalStatus 3 "Not Available" 2 "Error" 1 "Operational" 0 "Not Operational" ;
VAL_ 2364720126 Module28OperationalStatus 3 "Not Available" 2 "Error" 1 "Operational" 0 "Not Operational" ;
VAL_ 2364720126 Module27OperationalStatus 3 "Not Available" 2 "Error" 1 "Operational" 0 "Not Operational" ;
VAL_ 2364720126 Module26OperationalStatus 3 "Not Available" 2 "Error" 1 "Operational" 0 "Not Operational" ;
VAL_ 2364720126 Module25OperationalStatus 3 "Not Available" 2 "Error" 1 "Operational" 0 "Not Operational" ;
VAL_ 2364720126 Module24OperationalStatus 3 "Not Available" 2 "Error" 1 "Operational" 0 "Not Operational" ;
VAL_ 2364720126 Module23OperationalStatus 3 "Not Available" 2 "Error" 1 "Operational" 0 "Not Operational" ;
VAL_ 2364720126 Module22OperationalStatus 3 "Not Available" 2 "Error" 1 "Operational" 0 "Not Operational" ;
VAL_ 2364720126 Module21OperationalStatus 3 "Not Available" 2 "Error" 1 "Operational" 0 "Not Operational" ;
VAL_ 2364720126 Module20OperationalStatus 3 "Not Available" 2 "Error" 1 "Operational" 0 "Not Operational" ;
VAL_ 2364720126 Module19OperationalStatus 3 "Not Available" 2 "Error" 1 "Operational" 0 "Not Operational" ;
VAL_ 2364720126 Module18OperationalStatus 3 "Not Available" 2 "Error" 1 "Operational" 0 "Not Operational" ;
VAL_ 2364720126 Module17OperationalStatus 3 "Not Available" 2 "Error" 1 "Operational" 0 "Not Operational" ;
VAL_ 2364720126 Module16OperationalStatus 3 "Not Available" 2 "Error" 1 "Operational" 0 "Not Operational" ;
VAL_ 2364720126 Module15OperationalStatus 3 "Not Available" 2 "Error" 1 "Operational" 0 "Not Operational" ;
VAL_ 2364720126 Module14OperationalStatus 3 "Not Available" 2 "Error" 1 "Operational" 0 "Not Operational" ;
VAL_ 2364720126 Module13OperationalStatus 3 "Not Available" 2 "Error" 1 "Operational" 0 "Not Operational" ;
VAL_ 2364720126 Module12OperationalStatus 3 "Not Available" 2 "Error" 1 "Operational" 0 "Not Operational" ;
VAL_ 2364720126 Module11OperationalStatus 3 "Not Available" 2 "Error" 1 "Operational" 0 "Not Operational" ;
VAL_ 2364720126 Module10OperationalStatus 3 "Not Available" 2 "Error" 1 "Operational" 0 "Not Operational" ;
VAL_ 2364720126 Module9OperationalStatus 3 "Not Available" 2 "Error" 1 "Operational" 0 "Not Operational" ;
VAL_ 2364720126 Module8OperationalStatus 3 "Not Available" 2 "Error" 1 "Operational" 0 "Not Operational" ;
VAL_ 2364720126 Module7OperationalStatus 3 "Not Available" 2 "Error" 1 "Operational" 0 "Not Operational" ;
VAL_ 2364720126 Module6OperationalStatus 3 "Not Available" 2 "Error" 1 "Operational" 0 "Not Operational" ;
VAL_ 2364720126 Module5OperationalStatus 3 "Not Available" 2 "Error" 1 "Operational" 0 "Not Operational" ;
VAL_ 2364720126 Module4OperationalStatus 3 "Not Available" 2 "Error" 1 "Operational" 0 "Not Operational" ;
VAL_ 2364720126 Module3OperationalStatus 3 "Not Available" 2 "Error" 1 "Operational" 0 "Not Operational" ;
VAL_ 2364720126 Module2OperationalStatus 3 "Not Available" 2 "Error" 1 "Operational" 0 "Not Operational" ;
VAL_ 2364720126 Module1OperationalStatus 3 "Not Available" 2 "Error" 1 "Operational" 0 "Not Operational" ;
VAL_ 2364719614 OperationalStatus 15 "Not Available" 14 "Error" 13 "Reserved" 12 "Reserved" 11 "Reserved" 10 "Reserved" 9 "Reserved" 8 "Reserved" 7 "Reserved" 6 "Disabled by internal decision of HVES controller" 5 "Disabled by external command" 4 "Emergency Power-Down In Process" 3 "Normal Power-Down in Process" 2 "Operational." 1 "Initialization Complete" 0 "Initialization in process" ;
VAL_ 2364719614 HVBusConnectionStatus 15 "Not Available" 14 "Error" 13 "Reserved" 12 "Reserved" 11 "Reserved" 10 "Reserved" 9 "Reserved" 8 "Reserved" 7 "Reserved" 6 "Reserved" 5 "Reserved" 4 "Disconnected,  Precharge Failed" 3 "Disconnection in Process" 2 "Connection in Process" 1 "Connected" 0 "Disconnected, One or more contactors are open" ;
VAL_ 2364719614 InternalChargerStatus 3 "Not Available" 2 "Error" 1 "Charging on" 0 "Charging off" ;
VAL_ 2364719614 CellBalancingActive 3 "Not Available" 2 "Error" 1 "Cell balancing is active" 0 "Cell balancing is not active" ;
VAL_ 2364719614 CellBalanceStatus 3 "Not Available" 2 "Error" 1 "Cells are unbalanced" 0 "Cells are balanced" ;
VAL_ 2364719614 StOfChargeStatus 15 "Not  Available" 14 "Error" 13 "Reserved" 12 "Reserved" 11 "Reserved" 10 "Reserved" 9 "Reserved" 8 "Reserved" 7 "Reserved" 6 "SOC is above its recommended upper limit" 5 "SOC is at its recommended upper limit" 4 "SOC is approaching its recommended upper limit" 3 "SOC is below its recommended lower limit" 2 "SOC is at its recommended lower limit" 1 "SOC is approaching its recommended lower limit" 0 "SOC level is acceptable" ;
VAL_ 2364719614 InertiaSwStatus 3 "Not Available" 2 "Error" 1 "Impact sensed" 0 "No impact sensed" ;
VAL_ 2364719614 HVILStatus 3 "Not Available" 2 "Error" 1 "HVIL Open" 0 "HVIL Closed" ;
VAL_ 2364719614 HVBusPassiveIsolTestStatus 15 "Not available" 14 "Error" 13 "Reserved" 12 "Reserved" 11 "Reserved" 10 "Reserved" 9 "Reserved" 8 "Reserved" 7 "Reserved" 6 "Reserved" 5 "Test complete,  isolation fault" 4 "Test complete,  isolation marginal" 3 "Test complete,  isolation acceptable" 2 "Test in process" 1 "Test requested but not yet in process" 0 "No test requested / No test in process" ;
VAL_ 2364719614 HVBusActiveIsolTestStatus 15 "Not available" 14 "Error" 13 "Reserved" 12 "Reserved" 11 "Reserved" 10 "Reserved" 9 "Reserved" 8 "Reserved" 7 "Reserved" 6 "Reserved" 5 "Test complete,  isolation fault" 4 "Test complete,  isolation marginal" 3 "Test complete,  isolation acceptable" 2 "Test in process" 1 "Test requested but not yet in process" 0 "No test requested / No test in process" ;
VAL_ 2364719614 CenterOfPackContactorSt 3 "Not Available" 2 "Error" 1 "Contactor Closed" 0 "Contactor Open" ;
VAL_ 2364719614 HVBusPreChargeRelaySt 3 "Not Available" 2 "Error" 1 "Relay Closed" 0 "Relay Open" ;
VAL_ 2364719614 HVBusDisconnectForewarning 15 "Not Available" 14 "Error" 13 "Disconnect imminent" 12 "Reserved" 11 "Reserved" 10 "Reserved" 9 "Reserved" 8 "Reserved" 7 "Disconnect imminent due to battery pack current approaching maximum acceptable level" 6 "Disconnect imminent due to cell voltage approaching maximum acceptable level" 5 "Disconnect imminent due to cell voltage approaching minimum acceptable level" 4 "Disconnect imminent due to module voltage approaching maximum acceptable level" 3 "Disconnect imminent due to module voltage approaching minimum acceptable level" 2 "Disconnect imminent due to battery pack voltage approaching maximum acceptable level" 1 "Disconnect imminent due to battery pack voltage approaching minimum acceptable level" 0 "Disconnect not pending" ;
VAL_ 2364719614 HVBusContactorSt16312 3 "Not Available" 2 "Error" 1 "Contactor Closed" 0 "Contactor Open" ;
VAL_ 2364719614 HVBusContactorSt 3 "Not Available" 2 "Error" 1 "Contactor Closed" 0 "Contactor Open" ;
VAL_ 2364718590 CellTempDiffStatus 3 "Not Available" 2 "Error" 1 "Cell-to-cell temperature differential exceeds acceptable limits" 0 "Cell-to-cell temperature differential is within acceptable limits" ;
VAL_ 2364718334 CellVDiffStatus 15 "Not Available" 14 "Error" 13 "Reserved" 12 "Reserved" 11 "Reserved" 10 "Reserved" 9 "Reserved" 8 "Reserved" 7 "Reserved" 6 "Reserved" 5 "Reserved" 4 "Exceeds limits and it is not known whether balancing can restore performance" 3 "Exceeds limits and external maintenance balancing cannot restore performance" 2 "Exceeds limits and external maintenance balancing is required" 1 "Exceeds limits and can be corrected via auto-balancing" 0 "Is within acceptable limits" ;
VAL_ 2364717822 ChargePLDueToAnUndefinedCause 3 "Not Available" 2 "Error" 1 "Power limited for this reason" 0 "No power limit for this reason" ;
VAL_ 2364717822 ChargePLDueToBatCur 3 "Not Available" 2 "Error" 1 "Power limited for this reason" 0 "No power limit for this reason" ;
VAL_ 2364717822 ChargePLDueToBatOrCellV 3 "Not Available" 2 "Error" 1 "Power limited for this reason" 0 "No power limit for this reason" ;
VAL_ 2364717822 ChargePLDueToBatDiagCondition 3 "Not Available" 2 "Error" 1 "Power limited for this reason" 0 "No power limit for this reason" ;
VAL_ 2364717822 ChargePLDueToBatTemp 3 "Not Available" 2 "Error" 1 "Power limited for this reason" 0 "No power limit for this reason" ;
VAL_ 2364717822 ChargePLDueToStOfCharge 3 "Not Available" 2 "Error" 1 "Power limited for this reason" 0 "No power limit for this reason" ;
VAL_ 2364717822 DisPLDueToAnUndefinedCause 3 "Not Available" 2 "Error" 1 "Power limited for this reason" 0 "No power limit for this reason" ;
VAL_ 2364717822 DisPLDueToBatCur 3 "Not Available" 2 "Error" 1 "Power limited for this reason" 0 "No power limit for this reason" ;
VAL_ 2364717822 DisPLDueToBatOrCellV 3 "Not Available" 2 "Error" 1 "Power limited for this reason" 0 "No power limit for this reason" ;
VAL_ 2364717822 DisPLDueToBatDiagCondition 3 "Not Available" 2 "Error" 1 "Power limited for this reason" 0 "No power limit for this reason" ;
VAL_ 2364717822 DisPLDueToBatTemp 3 "Not Available" 2 "Error" 1 "Power limited for this reason" 0 "No power limit for this reason" ;
VAL_ 2364717822 DisPLDueToStOfCharge 3 "Not Available" 2 "Error" 1 "Power limited for this reason" 0 "No power limit for this reason" ;
VAL_ 2364717054 Data9EmbeddedIntegritySupport 3 "CRC and Counter are not supported by the sender" 2 "Reserved" 1 "Protection is supported using J1939-76 SHM" 0 "Embedded CRC and Counter are supported by the sender" ;
VAL_ 2364717054 HVESS17ThermalEventDetected 3 "Not available" 2 "Error" 1 "Thermal Event Detected" 0 "No Thermal Event Detected" ;
VAL_ 2364716542 TMSCoolantLvl 3 "Not Available" 2 "Error" 1 "Coolant Level is sufficient" 0 "Coolant Level is not sufficient" ;
VAL_ 2364716542 TMSMode 15 "Not Available" 14 "Faulted" 13 "Reserved" 12 "Reserved" 11 "Reserved" 10 "Reserved" 9 "Reserved" 8 "Reserved" 7 "Reserved" 6 "Reserved" 5 "Maintaining" 4 "Drying" 3 "Heating" 2 "Cooling" 1 "Circulating" 0 "Off" ;
VAL_ 2364716542 TMSHVILStatus 3 "Not Available" 2 "Error" 1 "HVIL Open" 0 "HVIL Closed" ;
VAL_ 2364716542 TMSHtrStatus 3 "Not Available" 2 "Error" 1 "Heater On" 0 "Heater Off" ;
VAL_ 2364716286 Module32OperationalStatus 3 "Not Available" 2 "Error" 1 "Operational" 0 "Not Operational" ;
VAL_ 2364716286 Module31OperationalStatus 3 "Not Available" 2 "Error" 1 "Operational" 0 "Not Operational" ;
VAL_ 2364716286 Module30OperationalStatus 3 "Not Available" 2 "Error" 1 "Operational" 0 "Not Operational" ;
VAL_ 2364716286 Module29OperationalStatus 3 "Not Available" 2 "Error" 1 "Operational" 0 "Not Operational" ;
VAL_ 2364716286 Module28OperationalStatus 3 "Not Available" 2 "Error" 1 "Operational" 0 "Not Operational" ;
VAL_ 2364716286 Module27OperationalStatus 3 "Not Available" 2 "Error" 1 "Operational" 0 "Not Operational" ;
VAL_ 2364716286 Module26OperationalStatus 3 "Not Available" 2 "Error" 1 "Operational" 0 "Not Operational" ;
VAL_ 2364716286 Module25OperationalStatus 3 "Not Available" 2 "Error" 1 "Operational" 0 "Not Operational" ;
VAL_ 2364716286 Module24OperationalStatus 3 "Not Available" 2 "Error" 1 "Operational" 0 "Not Operational" ;
VAL_ 2364716286 Module23OperationalStatus 3 "Not Available" 2 "Error" 1 "Operational" 0 "Not Operational" ;
VAL_ 2364716286 Module22OperationalStatus 3 "Not Available" 2 "Error" 1 "Operational" 0 "Not Operational" ;
VAL_ 2364716286 Module21OperationalStatus 3 "Not Available" 2 "Error" 1 "Operational" 0 "Not Operational" ;
VAL_ 2364716286 Module20OperationalStatus 3 "Not Available" 2 "Error" 1 "Operational" 0 "Not Operational" ;
VAL_ 2364716286 Module19OperationalStatus 3 "Not Available" 2 "Error" 1 "Operational" 0 "Not Operational" ;
VAL_ 2364716286 Module18OperationalStatus 3 "Not Available" 2 "Error" 1 "Operational" 0 "Not Operational" ;
VAL_ 2364716286 Module17OperationalStatus 3 "Not Available" 2 "Error" 1 "Operational" 0 "Not Operational" ;
VAL_ 2364716286 Module16OperationalStatus 3 "Not Available" 2 "Error" 1 "Operational" 0 "Not Operational" ;
VAL_ 2364716286 Module15OperationalStatus 3 "Not Available" 2 "Error" 1 "Operational" 0 "Not Operational" ;
VAL_ 2364716286 Module14OperationalStatus 3 "Not Available" 2 "Error" 1 "Operational" 0 "Not Operational" ;
VAL_ 2364716286 Module13OperationalStatus 3 "Not Available" 2 "Error" 1 "Operational" 0 "Not Operational" ;
VAL_ 2364716286 Module12OperationalStatus 3 "Not Available" 2 "Error" 1 "Operational" 0 "Not Operational" ;
VAL_ 2364716286 Module11OperationalStatus 3 "Not Available" 2 "Error" 1 "Operational" 0 "Not Operational" ;
VAL_ 2364716286 Module10OperationalStatus 3 "Not Available" 2 "Error" 1 "Operational" 0 "Not Operational" ;
VAL_ 2364716286 Module9OperationalStatus 3 "Not Available" 2 "Error" 1 "Operational" 0 "Not Operational" ;
VAL_ 2364716286 Module8OperationalStatus 3 "Not Available" 2 "Error" 1 "Operational" 0 "Not Operational" ;
VAL_ 2364716286 Module7OperationalStatus 3 "Not Available" 2 "Error" 1 "Operational" 0 "Not Operational" ;
VAL_ 2364716286 Module6OperationalStatus 3 "Not Available" 2 "Error" 1 "Operational" 0 "Not Operational" ;
VAL_ 2364716286 Module5OperationalStatus 3 "Not Available" 2 "Error" 1 "Operational" 0 "Not Operational" ;
VAL_ 2364716286 Module4OperationalStatus 3 "Not Available" 2 "Error" 1 "Operational" 0 "Not Operational" ;
VAL_ 2364716286 Module3OperationalStatus 3 "Not Available" 2 "Error" 1 "Operational" 0 "Not Operational" ;
VAL_ 2364716286 Module2OperationalStatus 3 "Not Available" 2 "Error" 1 "Operational" 0 "Not Operational" ;
VAL_ 2364716286 Module1OperationalStatus 3 "Not Available" 2 "Error" 1 "Operational" 0 "Not Operational" ;
VAL_ 2364715774 OperationalStatus 15 "Not Available" 14 "Error" 13 "Reserved" 12 "Reserved" 11 "Reserved" 10 "Reserved" 9 "Reserved" 8 "Reserved" 7 "Reserved" 6 "Disabled by internal decision of HVES controller" 5 "Disabled by external command" 4 "Emergency Power-Down In Process" 3 "Normal Power-Down in Process" 2 "Operational." 1 "Initialization Complete" 0 "Initialization in process" ;
VAL_ 2364715774 HVBusConnectionStatus 15 "Not Available" 14 "Error" 13 "Reserved" 12 "Reserved" 11 "Reserved" 10 "Reserved" 9 "Reserved" 8 "Reserved" 7 "Reserved" 6 "Reserved" 5 "Reserved" 4 "Disconnected,  Precharge Failed" 3 "Disconnection in Process" 2 "Connection in Process" 1 "Connected" 0 "Disconnected, One or more contactors are open" ;
VAL_ 2364715774 InternalChargerStatus 3 "Not Available" 2 "Error" 1 "Charging on" 0 "Charging off" ;
VAL_ 2364715774 CellBalancingActive 3 "Not Available" 2 "Error" 1 "Cell balancing is active" 0 "Cell balancing is not active" ;
VAL_ 2364715774 CellBalanceStatus 3 "Not Available" 2 "Error" 1 "Cells are unbalanced" 0 "Cells are balanced" ;
VAL_ 2364715774 StOfChargeStatus 15 "Not  Available" 14 "Error" 13 "Reserved" 12 "Reserved" 11 "Reserved" 10 "Reserved" 9 "Reserved" 8 "Reserved" 7 "Reserved" 6 "SOC is above its recommended upper limit" 5 "SOC is at its recommended upper limit" 4 "SOC is approaching its recommended upper limit" 3 "SOC is below its recommended lower limit" 2 "SOC is at its recommended lower limit" 1 "SOC is approaching its recommended lower limit" 0 "SOC level is acceptable" ;
VAL_ 2364715774 InertiaSwStatus 3 "Not Available" 2 "Error" 1 "Impact sensed" 0 "No impact sensed" ;
VAL_ 2364715774 HVILStatus 3 "Not Available" 2 "Error" 1 "HVIL Open" 0 "HVIL Closed" ;
VAL_ 2364715774 HVBusPassiveIsolTestStatus 15 "Not available" 14 "Error" 13 "Reserved" 12 "Reserved" 11 "Reserved" 10 "Reserved" 9 "Reserved" 8 "Reserved" 7 "Reserved" 6 "Reserved" 5 "Test complete,  isolation fault" 4 "Test complete,  isolation marginal" 3 "Test complete,  isolation acceptable" 2 "Test in process" 1 "Test requested but not yet in process" 0 "No test requested / No test in process" ;
VAL_ 2364715774 HVBusActiveIsolTestStatus 15 "Not available" 14 "Error" 13 "Reserved" 12 "Reserved" 11 "Reserved" 10 "Reserved" 9 "Reserved" 8 "Reserved" 7 "Reserved" 6 "Reserved" 5 "Test complete,  isolation fault" 4 "Test complete,  isolation marginal" 3 "Test complete,  isolation acceptable" 2 "Test in process" 1 "Test requested but not yet in process" 0 "No test requested / No test in process" ;
VAL_ 2364715774 CenterOfPackContactorSt 3 "Not Available" 2 "Error" 1 "Contactor Closed" 0 "Contactor Open" ;
VAL_ 2364715774 HVBusPreChargeRelaySt 3 "Not Available" 2 "Error" 1 "Relay Closed" 0 "Relay Open" ;
VAL_ 2364715774 HVBusDisconnectForewarning 15 "Not Available" 14 "Error" 13 "Disconnect imminent" 12 "Reserved" 11 "Reserved" 10 "Reserved" 9 "Reserved" 8 "Reserved" 7 "Disconnect imminent due to battery pack current approaching maximum acceptable level" 6 "Disconnect imminent due to cell voltage approaching maximum acceptable level" 5 "Disconnect imminent due to cell voltage approaching minimum acceptable level" 4 "Disconnect imminent due to module voltage approaching maximum acceptable level" 3 "Disconnect imminent due to module voltage approaching minimum acceptable level" 2 "Disconnect imminent due to battery pack voltage approaching maximum acceptable level" 1 "Disconnect imminent due to battery pack voltage approaching minimum acceptable level" 0 "Disconnect not pending" ;
VAL_ 2364715774 HVBusContactorSt16170 3 "Not Available" 2 "Error" 1 "Contactor Closed" 0 "Contactor Open" ;
VAL_ 2364715774 HVBusContactorSt 3 "Not Available" 2 "Error" 1 "Contactor Closed" 0 "Contactor Open" ;
VAL_ 2364714750 CellTempDiffStatus 3 "Not Available" 2 "Error" 1 "Cell-to-cell temperature differential exceeds acceptable limits" 0 "Cell-to-cell temperature differential is within acceptable limits" ;
VAL_ 2364714494 CellVDiffStatus 15 "Not Available" 14 "Error" 13 "Reserved" 12 "Reserved" 11 "Reserved" 10 "Reserved" 9 "Reserved" 8 "Reserved" 7 "Reserved" 6 "Reserved" 5 "Reserved" 4 "Exceeds limits and it is not known whether balancing can restore performance" 3 "Exceeds limits and external maintenance balancing cannot restore performance" 2 "Exceeds limits and external maintenance balancing is required" 1 "Exceeds limits and can be corrected via auto-balancing" 0 "Is within acceptable limits" ;
VAL_ 2364713982 ChargePLDueToAnUndefinedCause 3 "Not Available" 2 "Error" 1 "Power limited for this reason" 0 "No power limit for this reason" ;
VAL_ 2364713982 ChargePLDueToBatCur 3 "Not Available" 2 "Error" 1 "Power limited for this reason" 0 "No power limit for this reason" ;
VAL_ 2364713982 ChargePLDueToBatOrCellV 3 "Not Available" 2 "Error" 1 "Power limited for this reason" 0 "No power limit for this reason" ;
VAL_ 2364713982 ChargePLDueToBatDiagCondition 3 "Not Available" 2 "Error" 1 "Power limited for this reason" 0 "No power limit for this reason" ;
VAL_ 2364713982 ChargePLDueToBatTemp 3 "Not Available" 2 "Error" 1 "Power limited for this reason" 0 "No power limit for this reason" ;
VAL_ 2364713982 ChargePLDueToStOfCharge 3 "Not Available" 2 "Error" 1 "Power limited for this reason" 0 "No power limit for this reason" ;
VAL_ 2364713982 DisPLDueToAnUndefinedCause 3 "Not Available" 2 "Error" 1 "Power limited for this reason" 0 "No power limit for this reason" ;
VAL_ 2364713982 DisPLDueToBatCur 3 "Not Available" 2 "Error" 1 "Power limited for this reason" 0 "No power limit for this reason" ;
VAL_ 2364713982 DisPLDueToBatOrCellV 3 "Not Available" 2 "Error" 1 "Power limited for this reason" 0 "No power limit for this reason" ;
VAL_ 2364713982 DisPLDueToBatDiagCondition 3 "Not Available" 2 "Error" 1 "Power limited for this reason" 0 "No power limit for this reason" ;
VAL_ 2364713982 DisPLDueToBatTemp 3 "Not Available" 2 "Error" 1 "Power limited for this reason" 0 "No power limit for this reason" ;
VAL_ 2364713982 DisPLDueToStOfCharge 3 "Not Available" 2 "Error" 1 "Power limited for this reason" 0 "No power limit for this reason" ;
VAL_ 2364713214 Data9EmbeddedIntegritySupport 3 "CRC and Counter are not supported by the sender" 2 "Reserved" 1 "Protection is supported using J1939-76 SHM" 0 "Embedded CRC and Counter are supported by the sender" ;
VAL_ 2364713214 HVESS16ThermalEventDetected 3 "Not available" 2 "Error" 1 "Thermal Event Detected" 0 "No Thermal Event Detected" ;
VAL_ 2364712702 TMSCoolantLvl 3 "Not Available" 2 "Error" 1 "Coolant Level is sufficient" 0 "Coolant Level is not sufficient" ;
VAL_ 2364712702 TMSMode 15 "Not Available" 14 "Faulted" 13 "Reserved" 12 "Reserved" 11 "Reserved" 10 "Reserved" 9 "Reserved" 8 "Reserved" 7 "Reserved" 6 "Reserved" 5 "Maintaining" 4 "Drying" 3 "Heating" 2 "Cooling" 1 "Circulating" 0 "Off" ;
VAL_ 2364712702 TMSHVILStatus 3 "Not Available" 2 "Error" 1 "HVIL Open" 0 "HVIL Closed" ;
VAL_ 2364712702 TMSHtrStatus 3 "Not Available" 2 "Error" 1 "Heater On" 0 "Heater Off" ;
